VERSION ""

NS_ :

BS_:

BU_: GENERIC_GWMWakeup Generic_BCM TRM GWM _delete APIM SODL RTM FCIM PDM SCMH SCMG HSWM GPSM RSM SODR DDM RBM DSM SCME TSTR
VAL_TABLE_ OffOn_NotUsed_NoData 3 "No_Data_Present" 2 "NotUsed" 1 "On" 0 "Off" ;
VAL_TABLE_ BrkDrvMde_D_Rq 7 "Faulty" 6 "NotUsed3" 5 "NotUsed2" 4 "NotUsed1" 3 "Track" 2 "Snow_Wet" 1 "Sport" 0 "Normal" ;
VAL_TABLE_ Null_Off_On 3 "NotUsed" 2 "On" 1 "Off" 0 "Null" ;
VAL_TABLE_ Faulty_1FFF 8191 "Faulty" ;
VAL_TABLE_ CnvtTopTrgt_D_Rq 7 "NotUsed4" 6 "NotUsed3" 5 "NotUsed2" 4 "NotUsed1" 3 "OpenTarget" 2 "OpenPosition" 1 "ClosePosition" 0 "CloseTarget" ;
VAL_TABLE_ CnvtTopPos_D_Stat 15 "Faulty" 14 "NotUsed7" 13 "NotUsed6" 12 "NotUsed5" 11 "NotUsed4" 10 "NotUsed3" 9 "NotUsed2" 8 "NotUsed1" 7 "ShutdownComplete" 6 "NoNormalised" 5 "Moving" 4 "PositionIntermediate" 3 "PositionOpenTarget" 2 "PositionOpenPosition" 1 "PositionClosePosition" 0 "PositionCloseTarget" ;
VAL_TABLE_ CnvtTopPar_D_Rq 7 "NotUsed" 6 "ForceIncrease3" 5 "ForceIncrease2" 4 "ForceIncrease1" 3 "NoAdapt" 2 "Teach" 1 "NoPwmNoAp" 0 "Normal" ;
VAL_TABLE_ CnvtTopComplt_D_Stat 7 "DenormalizingReady" 6 "NormalizingReady" 5 "RunoutComplete" 4 "StopByPositioning" 3 "StopByFault" 2 "StopByPinch" 1 "StopByStall" 0 "StopByRequest" ;
VAL_TABLE_ Inactive_Active_NotUsed_Faulty 3 "Faulty" 2 "NotUsed" 1 "Active" 0 "Inactive" ;
VAL_TABLE_ CnvtTop_D_Rq 7 "NotUsed" 6 "ResetErrorFlags" 5 "DiscardNormalization" 4 "SetNormalization" 3 "DirectDriveClose" 2 "DirectDriveOpen" 1 "DirectPosition" 0 "Stop" ;
VAL_TABLE_ FohEng_D_Rq 3 "AutoEnable_ParkEnable" 2 "AutoDisable_ParkEnable" 1 "AutoEnable_ParkDisable" 0 "Disable_Stop" ;
VAL_TABLE_ Null_Hi_NotUsed_Low 3 "Low" 2 "Not_Used" 1 "High" 0 "Null" ;
VAL_TABLE_ Current_Color 15 "NotUsed7" 14 "NotUsed6" 13 "NotUsed5" 12 "NotUsed4" 11 "NotUsed3" 10 "NotUsed2" 9 "NotUsed1" 8 "Null" 7 "Color7" 6 "Color6" 5 "Color5" 4 "Color4" 3 "Color3" 2 "Color2" 1 "Color1" 0 "Off" ;
VAL_TABLE_ Blended_Color 15 "NotUsed10" 14 "NotUsed9" 13 "NotUsed8" 12 "NotUsed7" 11 "NotUsed6" 10 "NotUsed5" 9 "NotUsed4" 8 "NotUsed3" 7 "NotUsed2" 6 "NotUsed1" 5 "_5" 4 "_4" 3 "_3" 2 "_2" 1 "_1" 0 "Null" ;
VAL_TABLE_ OffOn_Null_NotUsed 3 "NotUsed" 2 "Null" 1 "On" 0 "Off" ;
VAL_TABLE_ Null_Pers1_4_Vehicle 7 "Unused_2" 6 "Unused_1" 5 "Vehicle" 4 "PERS_4" 3 "PERS_3" 2 "PERS_2" 1 "PERS_1" 0 "Null" ;
VAL_TABLE_ VehKeyActv_D_Stat 15 "NotUsed7" 14 "NotUsed6" 13 "NotUsed5" 12 "NotUsed4" 11 "NotUsed3" 10 "NotUsed2" 9 "NotUsed1" 8 "Key8Active" 7 "Key7Active" 6 "Key6Active" 5 "Key5Active" 4 "Key4Active" 3 "Key3Active" 2 "Key2Active" 1 "Key1Active" 0 "NoKeyActive" ;
VAL_TABLE_ VehLckInd_D_Rq 3 "NotUsed" 2 "On_Day" 1 "On_Night" 0 "Off" ;
VAL_TABLE_ Off_On_Unknown_Invalid 3 "Invalid" 2 "Unknown" 1 "On" 0 "Off" ;
VAL_TABLE_ TowBarMsgTxt_D_Rq 7 "NotUsed3" 6 "NotUsed2" 5 "NotUsed1" 4 "TowBar_Ext_No_Trlr" 3 "Error_Dealer_Fix" 2 "Start_Engine_Swivel" 1 "Check_Tow_Bar" 0 "Null" ;
VAL_TABLE_ SeatFnChng 15 "Faulty" 14 "NotUsed9" 13 "NotUsed8" 12 "NotUsed7" 11 "NotUsed6" 10 "NotUsed5" 9 "NotUsed4" 8 "NotUsed3" 7 "NotUsed2" 6 "High" 5 "Low" 4 "Off" 3 "Decrease" 2 "Increase" 1 "NotUsed1" 0 "Inactive" ;
VAL_TABLE_ NoData_Faulty_3E_3F 63 "Faulty" 62 "NoDataExists" ;
VAL_TABLE_ Faulty_3FF 1023 "Faulty" ;
VAL_TABLE_ DynoMde_B_Cmd 1 "Two_Wheel_Dyno" 0 "Normal_Operation" ;
VAL_TABLE_ HvacPrecondRecirc_D_Rq 3 "Last_User_Setting" 2 "Auto" 1 "Recirc" 0 "Outside" ;
VAL_TABLE_ HvacPrecondAC_D_Rq 3 "Last_User_Setting" 2 "Auto" 1 "On" 0 "Off" ;
VAL_TABLE_ NoData_Faulty_FFFE_FFFF 65535 "Faulty" 65534 "NoDataExists" ;
VAL_TABLE_ PepsKeyActv_D_Stat 15 "NotUsed11" 14 "NotUsed10" 13 "NotUsed9" 12 "NotUsed8" 11 "NotUsed7" 10 "NotUsed6" 9 "NotUsed5" 8 "Key4Active" 7 "NotUsed4" 6 "NotUsed3" 5 "NotUsed2" 4 "Key3Active" 3 "NotUsed1" 2 "Key2Active" 1 "Key1Active" 0 "NoKeyActive" ;
VAL_TABLE_ CellLock_D_Rq 7 "NotUsed3" 6 "NotUsed2" 5 "NotUsed1" 4 "TrunkRelPopGlassLgCargo" 3 "LockAllDoorsandTailgate" 2 "UnlockDriversDoor" 1 "UnlockAllDoorsandTailgate" 0 "NoRequest" ;
VAL_TABLE_ DrTgateChime2_D_Rq 7 "NotUsed3" 6 "NotUsed2" 5 "NotUsed1" 4 "Long_Repeated" 3 "Fast" 2 "Short" 1 "Long" 0 "Off" ;
VAL_TABLE_ ValetMode_D_Stat 3 "Not used_3" 2 "On" 1 "Off" 0 "Null" ;
VAL_TABLE_ StopStrtDrvMde_D_Indic 3 "NotUsed" 2 "StartStop_IndirectDeselect" 1 "StopStart_Deselected" 0 "StopStart_Selected" ;
VAL_TABLE_ StopStrtStdby_D_Indic 6 "NotUsed2" 5 "Telltale_Struck_Out" 4 "Telltale_Flashing_Amber" 3 "Telltale_On_Amber" 2 "Telltale_Flashing_Green" 1 "Telltale_On_Green" 0 "Telltale_Off" 7 "NotUsed3" ;
VAL_TABLE_ CtaInnr_D_Stat 3 "Reporting" 2 "Not_Reporting" 1 "System_Standby" 0 "Initialization" ;
VAL_TABLE_ FohMsgTxt_D_Rq 4 "BatteryNotFullyCharged" 3 "Exceed7DaysFromLastEngRun" 2 "AmbientTemperatureTooHigh" 1 "LowFuel" 0 "NoMessage" ;
VAL_TABLE_ FohStrtDay_T_Rq 7 "Sunday" 6 "Saturday" 5 "Friday" 4 "Thursday" 3 "Wednesday" 2 "Tuesday" 1 "Monday" 0 "NotUsed" ;
VAL_TABLE_ DisableEnableNotUsedUnknown 3 "Unknown" 2 "NotUsed" 1 "Enable" 0 "Disable" ;
VAL_TABLE_ NoRequest_Request 1 "Request" 0 "NoRequest" ;
VAL_TABLE_ Foh_D_Stat 7 "Unused3" 6 "Unused2" 5 "Unused1" 4 "Stopping" 3 "Running" 2 "Starting" 1 "Prestart" 0 "Off" ;
VAL_TABLE_ ActiveStoragePassenger 7 "Unused3" 6 "Unused2" 5 "Unused1" 4 "StoreDipMemoryButton4" 3 "StoreDipMemoryButton3" 2 "StoreDipMemoryButton2" 1 "StoreDipMemoryButton1" 0 "Off" ;
VAL_TABLE_ DipMirror 1 "Dipped" 0 "Off" ;
VAL_TABLE_ WindowCmd 7 "Unused2" 6 "Unused1" 5 "NotDefined" 4 "Audo_Down" 3 "Manual_Down" 2 "Auto_Up" 1 "Manual_Up" 0 "Idle" ;
VAL_TABLE_ MirrorCmd 7 "Unused" 6 "Unfold" 5 "Fold" 4 "Right" 3 "Left" 2 "Down" 1 "Up" 0 "Idle" ;
VAL_TABLE_ WindowPosition 7 "Unused2" 6 "Unused1" 5 "Fully_Open" 4 "Bet60Percent_FullyOpen" 3 "Bet10Percent_60Percent" 2 "BetFully_10PercentOpen" 1 "Fully_Closed" 0 "Undefined" ;
VAL_TABLE_ OffOnNoDataUnused 3 "Unused" 2 "NoDataExists" 1 "On" 0 "Off" ;
VAL_TABLE_ FohFalt_D_Stat 15 "NotUsed4" 14 "NotUsed3" 13 "NotUsed2" 12 "NotUsed1" 11 "FuelTypeDoesNotMatchFOH" 10 "Lifecycle_ModeNotSet" 9 "AuxElectricCoolantPumpInop" 8 "TimeDelayAvoidExcessCycl" 7 "Fuel_Level_OutofRange" 6 "External_Fault" 5 "Internal_Fault" 4 "Voltage_limitation" 3 "Impact_Event" 2 "CoolantTemp_OutofRange" 1 "AmbientTemp_OutofRange" 0 "No_Disable" ;
VAL_TABLE_ FohRqRun_B_Rq 1 "SubmitRequest_toRun" 0 "DoesNotSubmitRequest_toRun" ;
VAL_TABLE_ SteWhlHeat 15 "NotUsed6" 14 "NotUsed5" 13 "NotUsed4" 12 "NotUsed3" 11 "NotUsed2" 10 "NotUsed1" 9 "Reserved_3" 8 "Reserved_2" 7 "Reserved_1" 6 "Level_3_Heating" 5 "Level_3_Heating_LS" 4 "Level_2_Heating" 3 "Level_2_Heating_LS" 2 "Level_1_Heating" 1 "Level_1_Heating_LS" 0 "Off" ;
VAL_TABLE_ OffOnUnusedFault 3 "Fault" 2 "Unused" 1 "On" 0 "Off" ;
VAL_TABLE_ EngineBrakeOff_Active 1 "Engine_Braking_Activated" 0 "Engine_Braking_Off" ;
VAL_TABLE_ Allowed_Denied 1 "Denied" 0 "Allowed" ;
VAL_TABLE_ PrkAid_D_Falt 7 "NotUsed2" 6 "NotUsed1" 5 "Failure_Front_PSM_Sensors" 4 "No_Data_Exists" 3 "Failure_Rear_Sensors" 2 "Speaker_Fault" 1 "ECU_Fault" 0 "No_Fault" ;
VAL_TABLE_ ApaSwtch_D_RqDrv 3 "Faulty" 2 "Stuck" 1 "Pressed" 0 "NotPressed" ;
VAL_TABLE_ _7F_Null 127 "Null" ;
VAL_TABLE_ SeatFnDrv_D_Rq 7 "CushionMassage" 6 "LumbarMassage" 5 "UpperBolster" 4 "LowerBolster" 3 "UpperLumbar" 2 "MiddleLumbar" 1 "LowerLumbar" 0 "Inactive" ;
VAL_TABLE_ Inactive_IncreaseDecrease 2 "Decrease" 1 "Increase" 0 "Inactive" ;
VAL_TABLE_ MemFeedback 8 "Recall_4" 7 "Recall_3" 6 "Recall_2" 5 "Recall_1" 4 "Store_4" 3 "Store_3" 2 "Store_2" 1 "Store_1" 0 "Inactive" ;
VAL_TABLE_ Null_Off_LowHigh 3 "High" 2 "Low" 1 "Off" 0 "Null" ;
VAL_TABLE_ NotUpdate_Update 1 "Updating" 0 "NotUpdating" ;
VAL_TABLE_ SeatFnDrv_D_Stat 7 "CushionMassage" 6 "LumbarMassage" 5 "UpperBolster" 4 "LowerBolster" 3 "UpperLumbar" 2 "MiddleLumbar" 1 "LowerLumbar" 0 "Null" ;
VAL_TABLE_ GearRvrse_D_Actl 7 "Fault" 6 "NotUsed_3" 5 "NotUsed_2" 4 "NotUsed_1" 3 "Active_confirmed" 2 "Active_not_confirmed" 1 "Inactive_confirmed" 0 "Inactive_not_confirmed" ;
VAL_TABLE_ SideDetect_SnStat_Invalid 3 "Invalid" 2 "System_Failure" 1 "Blocked" 0 "Clear" ;
VAL_TABLE_ SideDetect_OpStat 4 "Invalid" 3 "Disabled" 2 "On" 1 "Trailer_Tow_Off" 0 "Off" ;
VAL_TABLE_ SideDetect_Present 4 "Sensor_Blocked" 3 "Sensor_Fault" 2 "Flash_On" 1 "Alert_On" 0 "AlertOff_FlashOff_SensrClr" ;
VAL_TABLE_ Off_On_Flash_BulbProveout 3 "Bulb_Proveout" 2 "Flash" 1 "On" 0 "Off" ;
VAL_TABLE_ SideDetect_BLIS_Off_On 2 "BLIS_On_Second_Warning_ON" 1 "BLIS_On_Second_Warning_OFF" 0 "Off" ;
VAL_TABLE_ SideDetect_report 3 "Reporting" 2 "Not_Reporting" 1 "System_Standby" 0 "Initialization" ;
VAL_TABLE_ DrTGate_D_Rq 3 "NotUsed" 2 "Closing" 1 "Opening" 0 "Not_Moving" ;
VAL_TABLE_ WndwSide_D_Stat 3 "BothWindow_Operating" 2 "RearWindow_Operating" 1 "FrontWindow_Operating" 0 "NoWindows_Operating" ;
VAL_TABLE_ False_True 1 "True" 0 "False" ;
VAL_TABLE_ Null_Up_Down 3 "Unused" 2 "Down" 1 "Up" 0 "Null" ;
VAL_TABLE_ Null_Fwd_Rwd 3 "Unused" 2 "Rearward" 1 "Forward" 0 "Null" ;
VAL_TABLE_ Null_Ack_Nack_NotUsed 3 "Not_Used" 2 "Nack" 1 "Ack" 0 "Null" ;
VAL_TABLE_ HvacBlwrFront_D_Stat 31 "Not_Used" 20 "Full_On" 19 "95_Percent" 18 "90_Percent" 17 "85_Percent" 16 "80_Percent" 15 "75_Percent" 14 "70_Percent" 13 "65_Percent" 12 "60_Percent" 11 "55_Percent" 10 "50_Percent" 9 "45_Percent" 8 "40_Percent" 7 "35_Percent" 6 "30_Percent" 5 "25_Percent" 4 "20_Percent" 3 "15_Percent" 2 "10_Percent" 1 "5_Percent" 0 "Off" ;
VAL_TABLE_ ACU_ARAudioSource_Rsp 15 "iPod" 14 "USB" 13 "BTAudio" 0 "AmfmRadio" 1 "FrontDisc" 2 "SDARS_DAB" 3 "InDashCdChanger" 4 "VoiceRecogniser" 5 "TelematicUnit" 6 "BluetoothPhone" 7 "RearDisc" 8 "APIM" 9 "FrontAuxInput" 10 "Navigation" 11 "RearAux" 12 "NotReq" ;
VAL_TABLE_ ACU_AROperationType_Rsp 0 "Inactive" 1 "Requestaudioresource" 2 "Releaseaudioresource" 3 "Releaseallaudioresouces" 4 "Getresourceupdate" 5 "Getallresourceupdates" ;
VAL_TABLE_ ACU_ARResponse_Rsp 0 "Inactive" 1 "RequestAccepted" 2 "RequestAcceptedWoCtrl" 3 "RequestDenied" 4 "RessourceUpdateStatus" ;
VAL_TABLE_ ACU_ARReqstrPriority_Rp 0 "EmergencyServ" 1 "TelService" 2 "AutoAnswer" 3 "Ta" 4 "PttMutevoice" 5 "NavUserVoiceCmd" 6 "NavSysVoiceCmd" 7 "Radio" 8 "Disc" 9 "Alarm" 10 "Ptynews" 11 "Aux_ExtSource" 12 "MobileNavAndTelMute" 13 "ManualAudioMute" 14 "NotReq" ;
VAL_TABLE_ ACU_RUAudioSource_St 15 "iPod" 14 "USB" 13 "BTAudio" 0 "AmfmRadio" 1 "FrontDisc" 2 "SDARS_DAB" 3 "InDashCdChanger" 4 "VoiceRecogniser" 5 "TelematicUnit" 6 "BluetoothPhone" 7 "RearDisc" 8 "APIM" 9 "FrontAuxInput" 10 "Navigation" 11 "RearAux" 12 "NotReq" ;
VAL_TABLE_ FrontRequest_RearRequest 0 "FrontRequester" 1 "RearRequester" ;
VAL_TABLE_ ACU_RUResReqstStatus_St 0 "NoResourceupdate" 1 "Deallocated" 2 "Allocated" 3 "Stacked" 4 "Granted" 5 "GrantedNoControlOfAudioSrc" ;
VAL_TABLE_ ACU_RUReqstrPriority_St 0 "EmergencyServ" 1 "TelService" 2 "AutoAnswer" 3 "Ta" 4 "PttMutevoice" 5 "NavUserVoiceCmd" 6 "NavSysVoiceCmd" 7 "Radio" 8 "Disc" 9 "Alarm" 10 "Ptynews" 11 "Aux_ExtSource" 12 "MobileNavAndTelMute" 13 "ManualAudioMute" 14 "NotReq" ;
VAL_TABLE_ EFP_Bezel_Diag_St 15 "Reserved" 3 "CalibrationPartNumber" 2 "HardwarePartNumber" 1 "SoftwarePartNumber" 0 "Inactive_NOP" ;
VAL_TABLE_ Invalid_SupportedNotSup 2 "Not_Supported" 1 "Supported" 0 "Invalid" ;
VAL_TABLE_ Invalid_EnabledDisabled 0 "Invalid" 2 "Disabled" 1 "Enabled" ;
VAL_TABLE_ Diagnostic_Operation_Rq 7 "SignalStrength" 6 "SDARSESNNumber" 5 "SpeakerWalkAround" 4 "CalibrationPartNumber" 15 "Reserved" 3 "HardwarePartNumber" 2 "SoftwarePartNumber" 1 "GetAllBackgroundDiagRq" 0 "Inactive" ;
VAL_TABLE_ Bezel_Diag_Module_Rq 15 "Reserved" 3 "EFP" 2 "DSP_AMP" 1 "AHU" 0 "Inactive" ;
VAL_TABLE_ HMI_HMIMode_St 5 "Load_Shed_Active" 0 "Invalid" 1 "OffMode" 2 "On" 3 "Phone" 4 "Climate" ;
VAL_TABLE_ PrmtrAlrmEvnt_D_Stat 15 "NotUsed" 14 "Trailer" 13 "Shock_Sensor" 12 "Post_Crash" 11 "Panic" 10 "Intrusion" 9 "Inclination" 8 "Ign_Tamper" 7 "LG_Door" 6 "Decklid" 5 "Hood" 4 "PR_Door" 3 "PF_Door" 2 "DR_Door" 1 "DF_Door" 0 "Null" ;
VAL_TABLE_ PtcHtr_D_Cmd 3 "TurnOn" 2 "AutoMode" 1 "TurnOff" 0 "NoDecision_Initializing" ;
VAL_TABLE_ NoData_Fault_FFFE_FFFF 65535 "Fault" 65534 "NoDataExists" ;
VAL_TABLE_ TrlrBattChrg_D_Stat 3 "Reverse" 2 "Normal" 1 "Low" 0 "Null" ;
VAL_TABLE_ TrlrLampCtl_D_Stat 3 "NotUsed" 2 "TrlrLampCnnctDrvFailure" 1 "TrlrLampNotCnnctDrvFailure" 0 "Null" ;
VAL_TABLE_ ElPw_D_StatStrtStop 15 "NotUsed6" 14 "NotUsed5" 13 "NotUsed4" 12 "NotUsed3" 11 "NotUsed2" 10 "NotUsed1" 9 "Supported_Level_4" 8 "Supported_Level_3" 7 "Supported_Level_2" 6 "Supported_Level_1" 5 "Limited_Support" 4 "Fault_Limited" 3 "LV_Event_in_Progress" 2 "Not_Supported_Imminent" 1 "Supported_All" 0 "Not_Supported" ;
VAL_TABLE_ ImpactEvntFdbck_D_Stat 3 "NotUsed" 2 "EventComplete" 1 "EventInProgress" 0 "Normal" ;
VAL_TABLE_ NoData_Fault_3E_3F 63 "Fault" 62 "NoDataExists" ;
VAL_TABLE_ Null_Open 1 "Open" 0 "Null" ;
VAL_TABLE_ Inactive_Enable_Disable 0 "Inactive" 2 "Disable" 1 "Enable" ;
VAL_TABLE_ TempDegreesC_DegreesF 0 "Temperature_deg_c" 1 "Temperature_deg_f" ;
VAL_TABLE_ Temp_Detents 15 "Unused5" 14 "Unused4" 13 "Unused3" 12 "Unused2" 11 "Unused1" 10 "Display_Blank" 9 "_4_Heat_Bars" 8 "_3_Heat_Bars" 7 "_2_Heat_Bars" 6 "_1_Heat_Bar" 5 "Neutral_Bar_Only" 4 "_1_Cool_Bar" 3 "_2_Cool_Bars" 2 "_3_Cool_Bars" 1 "_4_Cool_Bars" 0 "No_Bars" ;
VAL_TABLE_ Set_Temp_Dig3 2 "_5" 1 "_0" 0 "Off" ;
VAL_TABLE_ Set_Temp_Dig 15 "Blank6" 14 "Blank5" 13 "Blank4" 12 "Blank3" 11 "Blank2" 10 "Blank1" 9 "_9" 8 "_8" 7 "_7" 6 "_6" 5 "_5" 4 "_4" 3 "_3" 2 "_2" 1 "_1" 0 "_0" ;
VAL_TABLE_ Btn_Status 16 "Rear_Control_Pressed" 15 "RHS_Cld_Seat_Pressed" 14 "LHS_Cld_Seat_Pressed" 13 "RHS_Htd_Seat_Pressed" 12 "LHS_Htd_Seat_Pressed" 11 "Rear_Power_Pressed" 10 "AUTO_Pressed" 9 "Blwr_Dec_Pressed" 8 "Blwr_Inc_Pressed" 7 "RHS_Temp_Dec_Pressed" 6 "RHS_Temp_Inc_Pressed" 5 "LHS_Temp_Dec_Pressed" 4 "LHS_Temp_Inc_Pressed" 3 "Floor_Pressed" 2 "Panel_Floor_Pressed" 1 "Panel_Pressed" 0 "None_Pressed" ;
VAL_TABLE_ Cond_Seat_Status 7 "Unused" 6 "Level_3_Heating" 5 "Level_2_Heating" 4 "Level_1_Heating" 3 "Level_3_Cooling" 2 "Level_2_Cooling" 1 "Level_1_Cooling" 0 "Off" ;
VAL_TABLE_ Htd_Strg_Whl_Status 3 "Level_3_Heating" 2 "Level_2_Heating" 1 "Level_1_Heating" 0 "Off" ;
VAL_TABLE_ Frt_Btn_Status_1st 31 "Defrost_Pressed" 30 "Htg_Strg_Whl_Pressed" 29 "RHS_Cld_Seat_Pressed" 28 "LHS_Cld_Seat_Pressed" 27 "RHS_Htd_Seat_Pressed" 26 "LHS_Htd_Seat_Pressed" 25 "Max_Defrost_Pressed" 24 "My_Temp_Pressed" 23 "Front_Power_Pressed" 22 "Rear_Defrost_Pressed" 21 "Pnl_Flr_Ws_Pressed" 20 "Pnl_Ws_Pressed" 19 "Windscreen_Pressed" 18 "Htd_Frt_Wsh_Pressed" 17 "Auto_Recirc_Pressed" 16 "Outside_Pressed" 15 "Recirc_Pressed" 14 "Max_AC_Pressed" 13 "AUTO_Pressed" 12 "Blwr_Dec_Pressed" 11 "Blwr_Inc_Pressed" 10 "RHS_Temp_Dec_Pressed" 9 "RHS_Temp_Inc_Pressed" 8 "LHS_Temp_Dec_Pressed" 7 "LHS_Temp_Inc_Pressed" 6 "Dual_Pressed" 5 "AC_Pressed" 4 "Floor_Ws_Pressed" 3 "Floor_Pressed" 2 "Panel_Floor_Pressed" 1 "Panel_Pressed" 0 "None_Pressed" ;
VAL_TABLE_ Frt_Blower_Speed 3 "NotUsed" 2 "Max_Blower" 1 "Min_Blower" 0 "No_Request" ;
VAL_TABLE_ Blower_Indicate 15 "Display_Blank" 14 "14_Indicators_On" 13 "13_Indicators_On" 12 "12_Indicators_On" 11 "11_Indicators_On" 10 "10_Indicators_On" 9 "9_Indicators_On" 8 "8_Indicators_On" 7 "7_Indicators_On" 6 "6_Indicators_On" 5 "5_Indicators_On" 4 "4_Indicators_On" 3 "3_Indicators_On" 2 "2_Indicators_On" 1 "1_Indicator_On" 0 "Indicators_Off" ;
VAL_TABLE_ Front_AUTO_Label 3 "Full" 2 "Mode" 1 "Blower" 0 "Off" ;
VAL_TABLE_ Drv_Set_Temp 31 "HI" 30 "29_5" 29 "29_0" 28 "28_5" 27 "28_0" 26 "27_5" 25 "27_0" 24 "26_5" 23 "26_0" 22 "25_5" 21 "25_0" 20 "24_5" 19 "24_0" 18 "23_5" 17 "23_0" 16 "22_5" 15 "22_0" 14 "21_5" 13 "21_0" 12 "20_5" 11 "20_0" 10 "19_5" 9 "19_0" 8 "18_5" 7 "18_0" 6 "17_5" 5 "17_0" 4 "16_5" 3 "16_0" 2 "15_5" 1 "LO" 0 "No_Request" ;
VAL_TABLE_ CC_Fr_Stat_User_Adj 7 "Unused4" 6 "Unused3" 5 "Unused2" 4 "Unused1" 3 "Fr_Blwr_Spd_Selection" 2 "FRHS_SetPt_Selection" 1 "FLHS_SetPt_Selection" 0 "None" ;
VAL_TABLE_ CC_Rr_Stat_User_Adj 15 "Unused9" 14 "Unused8" 13 "Unused7" 12 "Unused6" 11 "Unused5" 10 "Unused4" 9 "Unused3" 8 "Unused2" 7 "Unused1" 6 "Rr_Auto_Selection" 5 "Rr_Control_Selection" 4 "Rr_Power_Selection" 3 "Rr_Blwr_Spd_Selection" 2 "RRHS_SetPt_Selection" 1 "RLHS_SetPt_Selection" 0 "None" ;
VAL_TABLE_ CC_Fr_Btn_User_Adj 31 "Unused15" 30 "Unused14" 29 "Unused13" 28 "Unused12" 27 "Unused11" 26 "Unused10" 25 "Unused9" 24 "Unused8" 23 "Unused7" 22 "Unused6" 21 "Unused5" 20 "Unused4" 19 "Unused3" 18 "Unused2" 17 "Unused1" 16 "Htd_WS_Selection" 15 "FLR_Cnd_St_Selection" 14 "FLH_Cnd_St_Selection" 13 "HSW_Selection" 12 "Dual_Selection" 11 "Rear_Defrost_Selection" 10 "Max_Defrost_Selection" 9 "Defrost_Selection" 8 "Fr_Air_Dist_Selection" 7 "Max_AC_Selection" 6 "Fr_Power_Selection" 5 "Recirc_Selection" 4 "AC_Selection" 3 "Fr_Auto_Selection" 2 "Use_MyTemp_Selection" 1 "Save_MyTemp_Selection" 0 "None" ;
VAL_TABLE_ HeadLghtHiFdbck_D_Stat 3 "NotUsed" 2 "Cancel" 1 "Hold" 0 "Allow_Change" ;
VAL_TABLE_ Backlit_LED_Status 15 "Unused3" 14 "Unused2" 13 "Unused1" 12 "Night_12" 11 "Night_11" 10 "Night_10" 9 "Night_9" 8 "Night_8" 7 "Night_7" 6 "Night_6" 5 "Night_5" 4 "Night_4" 3 "Night_3" 2 "Night_2" 1 "Night_1" 0 "Off" ;
VAL_TABLE_ Veh_Lock_Status 3 "UNLOCK_DRV" 2 "UNLOCK_ALL" 1 "LOCK_ALL" 0 "LOCK_DBL" ;
VAL_TABLE_ CrashEvnt_D_Stat 3 "Invalid" 2 "Fuel_Cutoff_Event" 1 "Deploy_Event" 0 "No_Event" ;
VAL_TABLE_ ReducedGuard_D_Stat 3 "NotUsed" 2 "Alarm_On" 1 "Alarm_Off_Previously_On" 0 "Alarm_Off" ;
VAL_TABLE_ HvacPrecondBlwr_D_Rq 15 "NotUsed6" 14 "NotUsed5" 13 "NotUsed4" 12 "NotUsed3" 11 "NotUsed2" 10 "NotUsed1" 9 "Last_User_Setting" 8 "Auto" 7 "Speed7" 6 "Speed6" 5 "Speed5" 4 "Speed4" 3 "Speed3" 2 "Speed2" 1 "Speed1" 0 "Off" ;
VAL_TABLE_ HvacPrecondMode_D_Rq 15 "NotUsed4" 14 "NotUsed3" 13 "NotUsed2" 12 "NotUsed1" 11 "Last_User_Settings" 10 "Auto" 9 "Max_Defrost" 8 "Windshield_Panel_Floor" 7 "Windshield_Panel" 6 "Windshield" 5 "Windshield_Floor" 4 "Floor" 3 "Panel_Floor" 2 "Panel" 1 "MAX_AC" 0 "Off" ;
VAL_TABLE_ Null_Pressed 1 "Pressed" 0 "Null" ;
VAL_TABLE_ FobComm_D_Stat 3 "NotUsed" 2 "RemEngStartOK" 1 "RemEngStartFail" 0 "Null" ;
VAL_TABLE_ PudLamp_D_Rq 3 "RAMP_DOWN" 2 "RAMP_UP" 1 "ON" 0 "OFF" ;
VAL_TABLE_ WndwGlbl_D_Cmd 7 "NotUsed3" 6 "NotUsed2" 5 "NotUsed1" 4 "GLEARN" 3 "GCLOSE" 2 "GOPEN" 1 "GSTOP" 0 "Null" ;
VAL_TABLE_ LockMsg 7 "MSG7" 6 "MSG6" 5 "MSG5" 4 "MSG4" 3 "MSG3" 2 "MSG2" 1 "MSG1" 0 "NO_WARNING" ;
VAL_TABLE_ ChildLockDisplay 3 "NOT_SUPPORTED" 2 "ERROR" 1 "CHILD_UNLOCK" 0 "CHILD_LOCK" ;
VAL_TABLE_ Null_Lock_Unlock 3 "Not Used" 2 "Unlock" 1 "Lock" 0 "Null" ;
VAL_TABLE_ NotDown_Down 1 "Down" 0 "Not_Down" ;
VAL_TABLE_ NotUp_Up 1 "Up" 0 "Not_Up" ;
VAL_TABLE_ Wiper 15 "NO_DATA_EXISTS" 14 "STALLED" 13 "RESERVED" 12 "AUTO_ADJUST" 11 "COURTESYWIPE" 10 "AUTO_HIGH" 9 "AUTO_LOW" 8 "WASH" 7 "MIST_FLICK" 6 "MAN_HIGH" 5 "MAN_LOW" 4 "MAN_INT_ON" 3 "MAN_INT_OFF" 2 "OFF_MOVING" 1 "AUTO_OFF" 0 "OFF" ;
VAL_TABLE_ Turn_switch 3 "Unused_Treat_As_Off" 2 "Right" 1 "Left" 0 "Off" ;
VAL_TABLE_ PrkLght_D_Stat 3 "Park_Both" 2 "Park_Right" 1 "Park_Left" 0 "Off" ;
VAL_TABLE_ HeadLghtSwtch_D_Stat 3 "Autolamp" 2 "Headlamp" 1 "Parklamp" 0 "Off" ;
VAL_TABLE_ LifeCycMde_D_Actl 3 "Transport" 2 "NotUsed" 1 "Factory" 0 "Normal" ;
VAL_TABLE_ ClimtHeat_D_Rq 7 "NotUsed4" 6 "NotUsed3" 5 "NotUsed2" 4 "NotUsed1" 3 "Defrost_Defog" 2 "FastTempPullDownHeatingReq" 1 "OpportunisticHeatingReq" 0 "NoHeatingRequest" ;
VAL_TABLE_ ClimtCool_D_Rq 7 "NotUsed4" 6 "NotUsed3" 5 "NotUsed2" 4 "NotUsed1" 3 "Defrost_Defog" 2 "FastTempPullDownCoolReq" 1 "OpportunisticCoolingReq" 0 "NoCoolingRequest" ;
VAL_TABLE_ HvacRec_D_RqMxBatt 15 "NotUsed5" 14 "NotUsed4" 13 "NotUsed3" 12 "NotUsed2" 11 "NotUsed1" 10 "No_Override" 9 "90Percent_RecircMax" 8 "80Percent_RecircMax" 7 "70Percent_RecircMax" 6 "60Percent_RecircMax" 5 "50Percent_RecircMax" 4 "40Percent_RecircMax" 3 "30Percent_RecircMax" 2 "20Percent_RecircMax" 1 "10Percent_RecircMax" 0 "0Percent_RecircFullOpen" ;
VAL_TABLE_ PrkBrkStatus 7 "GeneralFault_MaintenceMode" 6 "ECD_by_Brake_ECU_Active" 5 "EPB_Limphome_Active" 4 "Rear_Caliper_Open" 3 "RWU_By_EPB_Active" 2 "Rear_Caliper_Transition" 1 "Rear_Caliper_Closed" 0 "Not_Supported" ;
VAL_TABLE_ Quality_Data 3 "OK" 2 "Not_Within_Specifications" 1 "Eval_In_Progress" 0 "Fault" ;
VAL_TABLE_ PwSrcULoFalt_D_Stat 3 "Fault_No_Output" 2 "Fault_Reduced_Output" 1 "Fault_NonSpecific" 0 "No_Fault" ;
VAL_TABLE_ Eng_D_Stat 3 "NotUsed" 2 "EngAutoStopped" 1 "EngOn" 0 "EngOff" ;
VAL_TABLE_ ElPw_D_Stat 7 "NotUsed_3" 6 "NotUsed_2" 5 "NotUsed_1" 4 "Fault_Limited" 3 "LV_Event_In_Progress" 2 "Not_Supported_Imminent" 1 "Supported" 0 "Not_Supported" ;
VAL_TABLE_ PwPckTq_D_Stat 3 "PwPckOn_TqAvailable" 2 "StartInPrgrss_TqNotAvail" 1 "PwPckOn_TqNotAvailable" 0 "PwPckOff_TqNotAvailable" ;
VAL_TABLE_ Fault_FF 255 "Fault" ;
VAL_TABLE_ ElCmprOverTe_D_Stat 3 "OverTempStop" 2 "OverTempWarning" 1 "Normal" 0 "Undefined" ;
VAL_TABLE_ Southern_Northern 3 "Fault" 2 "Northern" 1 "Southern" 0 "Invalid" ;
VAL_TABLE_ Fault_3FF 1023 "Fault" ;
VAL_TABLE_ Fault_F 15 "Fault" ;
VAL_TABLE_ Fault_1F 31 "Fault" ;
VAL_TABLE_ LockInhibit 1 "Inhibit" 0 "No_Inhibit" ;
VAL_TABLE_ FCIM_Target_ID 15 "ALL" 9 "GIM" 8 "DSP" 7 "SAT3" 6 "SAT2" 5 "SAT1" 4 "RSC" 3 "FES" 2 "ACM" 1 "CPM" 0 "NOP" ;
VAL_TABLE_ FCIM_Button_Type 54 "_6" 53 "_5" 52 "_4" 51 "_3" 50 "_2" 49 "_1" 48 "_0" 47 "Phone_Mute" 46 "Pause" 45 "Play_Pause" 44 "Volume_Down" 43 "Volume_Up" 42 "Tune_Down" 41 "Tune_Up" 40 "Treble_Down" 39 "Treble_Up" 38 "Tape" 37 "Seek_Down" 36 "Seek_Up" 35 "Shuffle" 34 "Repeat" 33 "Scan" 32 "Navigation" 31 "Fast_Forward" 30 "Reverse" 29 "Preset_6" 28 "Preset_5" 27 "Preset_4" 26 "Preset_3" 25 "Preset_2" 24 "Preset_1" 23 "Memory_Recall" 22 "Clear" 21 "End" 20 "Send" 19 "Fade_Down" 18 "Fade_Up" 17 "Dolby" 16 "Compression" 15 "Clock" 14 "Bass_Down" 13 "Bass_Up" 12 "Balance_Down" 11 "Balance_Up" 10 "Folder_Previous" 9 "Folder_Next" 8 "Category_Folder" 7 "File" 6 "Autoset" 5 "Menu_Previous" 4 "Menu_Next" 3 "Menu" 2 "OK_Select" 1 "Power_On_Off" 0 "NOP_No_Button" 255 "Last" 153 "RPT_Repeat" 152 "NAV" 151 "Dest_Destination" 150 "Map" 149 "SWC_End" 148 "SWC_Send" 147 "Special_2" 146 "Special_1" 145 "Phone_Data" 144 "Rear_Zone_Control" 141 "DISP_Display" 140 "INFO" 139 "Climate" 138 "Radio" 137 "Playmode" 136 "Bezel_Diagnostics" 135 "CursorDown" 134 "CursorUp" 133 "Mute" 132 "Phone" 131 "Eject" 130 "Load" 129 "CD" 128 "AM_FM" 124 "Pound_Clock" 123 "Reserved" 122 "Compass_Cal" 121 "SAT" 120 "Aux" 119 "Sound" 118 "Star_Direct_Direct" 117 "List_Item_5" 116 "List_Item_4" 115 "List_Item_3" 114 "List_Item_2" 113 "List_Item_1" 112 "Reserved_Feature_C" 111 "Reserved_Feature_B" 110 "Reserved_Feature_A" 109 "Active_Path" 108 "Distance_Markers" 107 "Return" 106 "Off" 105 "On" 104 "SWC_Seek_Down" 103 "SWC_Seek_Up" 102 "Media" 101 "Stop_Eject" 100 "B_Button" 99 "A_Button" 98 "TestTone" 97 "Lock_List_Item_5" 96 "Lock_List_Item_4" 95 "Lock_List_Item_3" 94 "Lock_List_Item_2" 93 "Lock_List_Item_1" 92 "Skip_List_Item_5" 91 "Skip_List_Item_4" 90 "Skip_List_Item_3" 89 "Skip_List_Item_2" 88 "Skip_List_Item_1" 87 "Enter" 86 "Back" 85 "Keypad" 84 "Channel_List_5" 83 "Channel_List_4" 82 "Channel_List_3" 81 "Channel_List_2" 80 "Channel_List_1" 79 "Category_List_Item_5" 78 "Category_List_Item_4" 77 "Category_List_Item_3" 76 "Category_List_Item_2" 75 "Category_List_Item_1" 74 "Channel_Guide" 73 "Scan_Presets" 72 "Category_Previous" 71 "Category_Next" 70 "Album" 69 "Song_Title" 68 "Artist" 67 "Text" 66 "BER_Display_Button" 65 "PSN_Display_Button" 64 "ESN_Display_Button" 63 "Category" 62 "Display_Previous" 61 "Display_Next" 60 "Voice_PTT" 59 "POUND" 58 "ASTERISK" 57 "_9" 56 "_8" 55 "_7" ;
VAL_TABLE_ FCIM_Button_State 2 "Button_Pressed" 1 "Button_Released" 0 "NOP" ;
VAL_TABLE_ Temp_Units 2 "Fahrenheit" 1 "Celsius" 0 "Off" ;
VAL_TABLE_ Shed_Feature_Group_ID 14 "HtdMirr" 13 "HvacRearBlwr_Third" 12 "HvacRearBlwr_Second" 11 "HvacRearBlwr_First" 31 "All LSHED1 Features" 10 "Htd_Windscrn" 9 "SpltHtdBcklight_HtdMirr" 8 "HtdBcklight_HtdMirr" 7 "HtdCoolSeat_FrtDriver" 6 "HtdCoolSeat_FrtPass" 5 "HtdCoolSeat_RearPass" 4 "HtdCoolSeat_RearDriver" 3 "SmartTrlrTowBattCharge" 2 "Htd_StrWhl" 1 "Htd_Washer_Fluid" 0 "No_LSHED1_Features" 15 "Engine_Coolant_Fan" ;
VAL_TABLE_ CoolantFanStepAct 31 "Unused7" 30 "Unused6" 29 "Unused5" 28 "Unused4" 27 "Unused3" 26 "Unused2" 25 "Unused1" 23 "Step23" 22 "Step22" 21 "Step21" 20 "Step20" 19 "Step19" 18 "Step18" 17 "Step17" 16 "Step16" 15 "Step15" 14 "Step14" 13 "Step13" 12 "Step12" 11 "Step11" 10 "Step10" 9 "Step9" 8 "Step8" 7 "Step7" 6 "Step6" 5 "Step5" 4 "Step4" 3 "Step3" 2 "Step2" 1 "Step1" 24 "Max_Fan_Speed_Req" 0 "Fan_Cmd_Off" ;
VAL_TABLE_ Null_Cancel 1 "Cancel" 0 "Null" ;
VAL_TABLE_ Null_Drive_EasyEntry 2 "Easy_Entry" 1 "Drive" 0 "Null" ;
VAL_TABLE_ Veh_Lock_Requestor 31 "Unused8" 30 "Unused7" 29 "Unused6" 28 "Unused5" 27 "Unused4" 26 "Unused3" 25 "Unused2" 24 "Unused1" 23 "Diagnostics" 22 "Console_Lock" 21 "Child_Lock" 20 "Double_Lock" 19 "Passive_Pasenger" 18 "Passive_Driver" 17 "Slam_Lock_Protect" 16 "SYNC" 15 "Passport" 14 "Passive_Smart_Unlock" 13 "Autorelock" 12 "RemoteStart" 0 "Null" 1 "Autolock" 11 "Smart_Unlock" 10 "Sliding_Door" 9 "Passive" 8 "Remote" 7 "Programming" 6 "Powerslide" 5 "Keypad" 4 "Key_Cylinder" 3 "Interior" 2 "Auto_Unlock" ;
VAL_TABLE_ Perimeter_Alarm_Mode 3 "Activated" 2 "Armed" 1 "Prearmed" 0 "Disarmed" ;
VAL_TABLE_ Invalid_FFFF 65535 "Invalid" ;
VAL_TABLE_ Shed_Level_Req 7 "Unused_2" 6 "Loads_On" 5 "SHED_ENG_OFF" 4 "SOON_ENG_OFF" 3 "SHED2_CONTIN" 2 "SHED2_TRANS" 1 "SHED1" 0 "NO_SHED" ;
VAL_TABLE_ Eastern_Western 0 "Invalid" 1 "Eastern" 2 "Western" 3 "Fault" ;
VAL_TABLE_ EATC_Temp_Digit3 2 "_5" 1 "_0" 0 "OFF" ;
VAL_TABLE_ EATC_Units 2 "Fahrenheit" 1 "Celsius" 0 "Off" ;
VAL_TABLE_ RKE_Filter_Ctrl 3 "Streaming" 2 "Filter" 1 "Not_Used" 0 "Null" ;
VAL_TABLE_ RstrnImpactEvntStatus 7 "Invalid" 6 "Not_Used_4" 5 "Threshold_2_Exceeded" 4 "Not_Used_3" 3 "Threshold_1_Exceeded" 2 "Not_Used_2" 1 "Not_Used_1" 0 "Normal" ;
VAL_TABLE_ Closed_Ajar 1 "Ajar" 0 "Closed" ;
VAL_TABLE_ Quality_Factor 3 "OK" 2 "Not_Within_Specifications" 1 "No_Data_Exists" 0 "Faulty" ;
VAL_TABLE_ Null_Day_Night 3 "NotUsed" 2 "Night" 1 "Day" 0 "Null" ;
VAL_TABLE_ WhlDir 3 "Failed" 2 "Unknown" 1 "Backward" 0 "Forward" ;
VAL_TABLE_ Unknown_Fault_1FE_1FF 511 "Fault" 510 "Unknown" ;
VAL_TABLE_ Unknown_Fault_FFFE_FFFF 65535 "Fault" 65534 "Unknown" ;
VAL_TABLE_ Invalid_FFFFFF 16777215 "Invalid" ;
VAL_TABLE_ GearLvrPos_D_Actl 15 "Fault" 14 "Unknown_Position" 13 "Undefined_Treat_as__Fault" 12 "Undefined_Treat_as_Fault" 11 "sixth" 10 "fifth" 9 "fourth" 8 "third" 7 "second" 6 "first" 5 "Low" 4 "Sport_DriveSport" 3 "Drive" 2 "Neutral" 1 "Reverse" 0 "Park" ;
VAL_TABLE_ AslIconDsply_D_Rq 3 "Not_Used" 2 "On_Active" 1 "On_Passive" 0 "Off" ;
VAL_TABLE_ Unknown_Fault_3E_3F 63 "Fault" 62 "Unknown" ;
VAL_TABLE_ NotPressed_Pressed 1 "Pressed" 0 "Not_Pressed" ;
VAL_TABLE_ NotQuiet_Quiet 1 "Quiet" 0 "Not_Quiet" ;
VAL_TABLE_ Remote_Device_Feedback 7 "Unused3" 6 "Unused2" 5 "Unused1" 4 "Shutdown" 3 "Running" 2 "Starting" 1 "Acknowledge" 0 "Null" ;
VAL_TABLE_ Remote_Start_Req 3 "Not_Used" 2 "Remote_Cancel" 1 "Remote_Start" 0 "No_Request" ;
VAL_TABLE_ Modulation_Ctrl 3 "Unused" 2 "FSK" 1 "ASK_FSK" 0 "ASK" ;
VAL_TABLE_ Unlock_Lock 1 "Locked" 0 "Unlock" ;
VAL_TABLE_ Unknown_Fault_FFE_FFF 4095 "Fault" 4094 "Unknown" ;
VAL_TABLE_ InhibitNoinhibit 1 "Inhibit" 0 "No_Inibit" ;
VAL_TABLE_ DisableEnable 1 "Enable" 0 "Disable" ;
VAL_TABLE_ Side_Detect_Sn_State 3 "Second_Warning_Audio" 2 "System_Failure" 1 "Blocked" 0 "Clear" ;
VAL_TABLE_ Litval_values 255 "Invalid" 254 "Unknown" 5 "Day" 4 "Twilight_4" 3 "Twilight_3" 2 "Twilight_2" 1 "Twilight_1" 0 "Night" ;
VAL_TABLE_ Dimming_Lvl 255 "Invalid" 254 "Unknown" 18 "Day_6" 17 "Day_5" 16 "Day_4" 15 "Day_3" 14 "Day_2" 13 "Day_1" 12 "Night_12" 11 "Night_11" 10 "Night_10" 9 "Night_9" 8 "Night_8" 7 "Night_7" 6 "Night_6" 5 "Night_5" 4 "Night_4" 3 "Night_3" 2 "Night_2" 1 "Night_1" 0 "Off" ;
VAL_TABLE_ Remote_Start_Status 3 "Invalid" 2 "Unknown" 1 "Remote" 0 "Null" ;
VAL_TABLE_ Enabled_Active_Disabled 3 "Unused" 2 "Disabled" 1 "Active" 0 "Enabled_Inactive" ;
VAL_TABLE_ Lock_Subld 15 "Unused7" 14 "Unused6" 13 "Unused5" 12 "Unused4" 11 "Unused3" 10 "Unused2" 9 "Unused1" 8 "Customer_8" 7 "Customer_7" 6 "Customer_6" 5 "Customer_5" 4 "Customer_4" 3 "Customer_3" 2 "Customer_2" 1 "Customer_1" 0 "Null" ;
VAL_TABLE_ OFF_ON_Unknown_Invalid 1 "On" 0 "Off" 3 "Invalid" 2 "Unknown" ;
VAL_TABLE_ Brake_Fluid 3 "Invalid" 2 "Unknown" 1 "Low" 0 "OK" ;
VAL_TABLE_ Unknown_Invalid_FE_FF 255 "Invalid" 254 "Unknown" ;
VAL_TABLE_ Invalid_FF 255 "Invalid" ;
VAL_TABLE_ NotLow_Low 1 "Low" 0 "Not_Low" ;
VAL_TABLE_ Key_In_Ignition_Status 1 "In" 0 "Out" ;
VAL_TABLE_ Ignition_Status 0 "Unknown" 1 "Off" 15 "Invalid" 8 "Start" 4 "Run" 2 "Accessory" ;
VAL_TABLE_ Disabled_Enabled_NoSupport 2 "Unused" 3 "Not_Supported" 1 "Enabled" 0 "Disabled" ;
VAL_TABLE_ Unknown_Fault_FE_FF 255 "Fault" 254 "Unknown" ;
VAL_TABLE_ Null_Unlock 1 "Unlock" 0 "Null" ;
VAL_TABLE_ Null_Active 1 "Active" 0 "Null" ;
VAL_TABLE_ MemoryCmd 7 "Recall_3" 4 "Store_4" 3 "Store_3" 6 "Recall_2" 5 "Recall_1" 2 "Store_2" 1 "Store_1" 0 "Null" 8 "Recall_4" ;
VAL_TABLE_ PassRstrnInd_Stat 7 "Invalid" 6 "Unused_2" 5 "Unused_1" 4 "Both_Indicators_Faulted" 3 "AirbagOff_Indicator_fault" 2 "AirbagOn_Indicator_fault" 1 "Normal" 0 "Not_Supported" ;
VAL_TABLE_ PassRstrnInd_Req 3 "ABOnNotIllum_OffNotIllum" 2 "AirbagOnNot_Illum_OffIllum" 1 "AirbagOn_Illum_OffNotIllum" 0 "AirbagOn_Illum_Off_Illum" ;
VAL_TABLE_ GPS_dimension 2 "_3D" 1 "_2D" 0 "No_Fix" ;
VAL_TABLE_ GPS_Compass_dirctn 7 "NorthWest" 6 "West" 5 "SouthWest" 4 "South" 3 "SouthEast" 2 "East" 1 "NorthEast" 0 "North" ;
VAL_TABLE_ GPS_Actual_Infer 1 "Inferred_Position" 0 "Actual_Postition" ;
VAL_TABLE_ Off_On 1 "On" 0 "Off" ;
VAL_TABLE_ InactiveActive 1 "Active" 0 "Inactive" ;
VAL_TABLE_ Unknown_Invalid_1E_1F 31 "Invalid" 30 "Unknown" ;
VAL_TABLE_ Unknown_Invalid_3FFE_3FFF 16383 "Invalid" 16382 "Unknown" ;
VAL_TABLE_ NoYes 1 "Yes" 0 "No" ;
VAL_TABLE_ Unknown_Fault_3FE_3FF 1023 "Fault" 1022 "Unknown" ;
VAL_TABLE_ LockSwStat 3 "Invalid" 2 "Unlock" 1 "Lock" 0 "Null" ;
VAL_TABLE_ Null_Override 1 "Override" 0 "Null" ;
VAL_TABLE_ Off_On_Flash 3 "Not_Used" 2 "Flash" 1 "On" 0 "Off" ;
VAL_TABLE_ Update_Bit 1 "Fresh_data" 0 "Unchanged_data" ;
VAL_TABLE_ Tire_Pressure_Stat 4 "Alert" 15 "Not_Supported" 3 "Fault" 2 "Low" 1 "Normal" 0 "Unknown" ;
VAL_TABLE_ Tire_Pressure_System2 13 "Training_Complete" 12 "Train_InsideLeftRear_tire" 11 "Train_OutsideLeftRear_tire" 10 "Train_LeftRear_tire" 9 "Train_InsideRtRear_tire" 8 "Train_OutsideRtRear_tire" 7 "Train_RightRear_tire" 14 "Tires_not_trained" 6 "Train_RightFront_tire" 5 "Train_LeftFront_tire" 4 "Systm_Activ_Composite_Stat" 3 "Low_Composite_Stat" 2 "Sensr_Fault_Composite_Stat" 1 "Systm_Fault_Composite_Stat" 0 "Unknown_Composite_Stat" ;
VAL_TABLE_ Running_Board 3 "Unused" 2 "Manually_Deployed" 1 "All_Enabled" 0 "All_Disabled" ;
VAL_TABLE_ Clmt_Ctrl_Seat_Setting 128 "H3_High_Heat__MAX" 64 "H2_Medium_Heat" 32 "H1_Low_Heat" 16 "C3_High_Cool__MAX" 8 "C2_Medium_Cool" 4 "C1_Low_Cool" 2 "Off" ;
VAL_TABLE_ Turn_Seq 3 "Seq" 2 "On" 1 "Off" 0 "Null" ;
VAL_TABLE_ NotPark 1 "Park" 0 "Not_Park" ;
VAL_TABLE_ PersOptIn 1 "OPTED_IN" 0 "NOT_OPTED_IN" ;
VAL_TABLE_ PersonalSetUp 3 "Non_Moveable_Person" 2 "Moveable_Person" 1 "Vehicle" 0 "Factory" ;
VAL_TABLE_ Full_Limited 1 "Limited" 0 "Full" ;
VAL_TABLE_ NoConflict_Conflict 1 "Conflict" 0 "No_Conflict" ;
VAL_TABLE_ Assoc_Confirm 0 "None" 7 "Associate" 6 "Keycode_Rejected" 5 "Keycode_Accepted" 4 "In_Progress" 3 "Erase" 2 "Duplicate" 1 "Disassociate" ;
VAL_TABLE_ Complete_Inprogress 3 "Unused" 2 "Null" 1 "InProgress" 0 "Complete" ;
VAL_TABLE_ Null_Pers1_4 7 "Unused_3" 6 "Unused_2" 5 "Unused_1" 4 "PERS_4" 3 "PERS_3" 2 "PERS_2" 1 "PERS_1" 0 "Null" ;
VAL_TABLE_ Pers1_4 7 "Unused_3" 6 "Unused_2" 5 "Unused_1" 4 "Vehicle" 3 "PERS_4" 2 "PERS_3" 1 "PERS_2" 0 "PERS_1" ;
VAL_TABLE_ Null_Query 7 "Unused_2" 6 "Unused_1" 5 "Copy" 4 "Restore" 3 "Upload" 2 "Set" 1 "Query" 0 "Null" ;
VAL_TABLE_ Ign_Key_Device_Type 15 "Invalid" 14 "Unknown" 3 "Key_Not_Prgrm_Read_Failure" 2 "Key_In_Ign_My_Key" 1 "Key_In_Ign_Standard_Key" 0 "Key_Read_In_Progress" ;
VAL_TABLE_ Off_No_Eff_Unknown_Invalid 3 "Invalid" 2 "Unknown" 1 "No_Effect" 0 "Off" ;
VAL_TABLE_ Null_Out 1 "Out" 0 "Null" ;

BO_ 945 Body_Info_7_MS1: 8 GWM
 SG_ KeyOffMde_D_Actl : 7|4@0+ (1,0) [0|15] "SED" Vector__XXX

BO_ 1079 GatewayData2_MS1: 8 GWM
 SG_ BattULo2_Te_Actl : 7|7@0+ (1,-40) [-40|86] "degC"  FCIM
 SG_ BattULo2_Te_Actl_UB : 0|1@0+ (1,0) [0|1] "SED"  FCIM

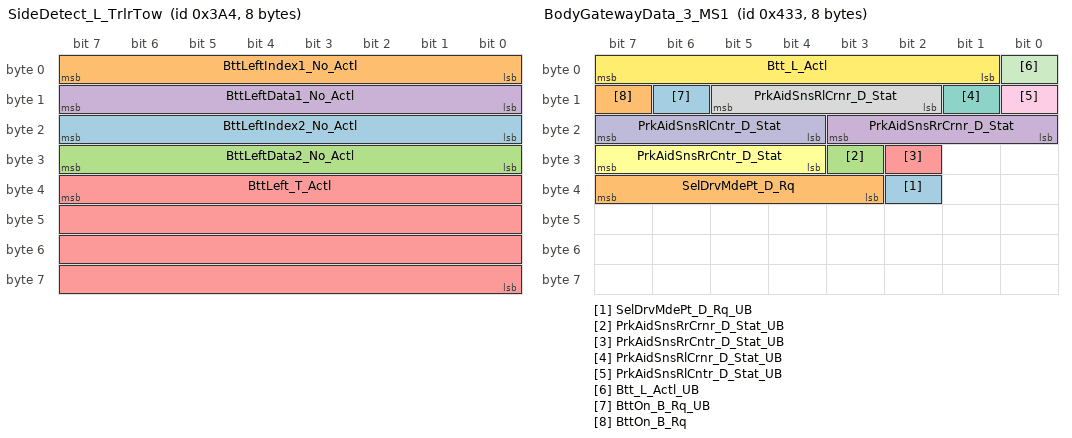
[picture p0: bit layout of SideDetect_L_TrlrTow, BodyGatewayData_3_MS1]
BO_ 932 SideDetect_L_TrlrTow: 8 SODL
 SG_ BttLeftIndex2_No_Actl : 23|8@0+ (1,0) [0|255] "unitless"  SODR
 SG_ BttLeftIndex1_No_Actl : 7|8@0+ (1,0) [0|255] "unitless"  SODR
 SG_ BttLeftData2_No_Actl : 31|8@0+ (1,0) [0|255] "unitless"  SODR
 SG_ BttLeftData1_No_Actl : 15|8@0+ (1,0) [0|255] "unitless"  SODR
 SG_ BttLeft_T_Actl : 39|32@0+ (1,0) [0|4294967295] "ms"  SODR

BO_ 1075 BodyGatewayData_3_MS1: 8 GWM
 SG_ SelDrvMdePt_D_Rq_UB : 34|1@0+ (1,0) [0|1] "SED"  FCIM
 SG_ SelDrvMdePt_D_Rq : 39|5@0+ (1,0) [0|31] "SED"  FCIM
 SG_ PrkAidSnsRrCrnr_D_Stat_UB : 27|1@0+ (1,0) [0|1] "SED"  SODL,SODR
 SG_ PrkAidSnsRrCrnr_D_Stat : 19|4@0+ (1,0) [0|15] "SED"  SODL,SODR
 SG_ PrkAidSnsRrCntr_D_Stat_UB : 26|1@0+ (1,0) [0|1] "SED"  SODL,SODR
 SG_ PrkAidSnsRrCntr_D_Stat : 31|4@0+ (1,0) [0|15] "SED"  SODL,SODR
 SG_ PrkAidSnsRlCrnr_D_Stat_UB : 9|1@0+ (1,0) [0|1] "SED"  SODL,SODR
 SG_ PrkAidSnsRlCrnr_D_Stat : 13|4@0+ (1,0) [0|15] "SED"  SODL,SODR
 SG_ PrkAidSnsRlCntr_D_Stat_UB : 8|1@0+ (1,0) [0|1] "SED"  SODL,SODR
 SG_ PrkAidSnsRlCntr_D_Stat : 23|4@0+ (1,0) [0|15] "SED"  SODL,SODR
 SG_ Btt_L_Actl_UB : 0|1@0+ (1,0) [0|1] "SED"  SODL,SODR
 SG_ Btt_L_Actl : 7|7@0+ (0.1,0) [0|12.5] "meter"  SODL,SODR
 SG_ BttOn_B_Rq_UB : 14|1@0+ (1,0) [0|1] "SED"  SODL,SODR
 SG_ BttOn_B_Rq : 15|1@0+ (1,0) [0|1] "SED"  SODL,SODR

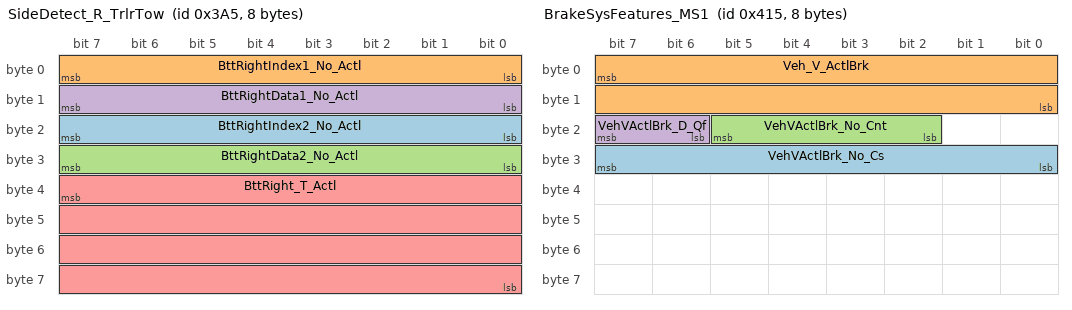
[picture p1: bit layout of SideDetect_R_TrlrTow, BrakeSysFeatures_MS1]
BO_ 933 SideDetect_R_TrlrTow: 8 SODR
 SG_ BttRightIndex2_No_Actl : 23|8@0+ (1,0) [0|255] "unitless"  SODL
 SG_ BttRightIndex1_No_Actl : 7|8@0+ (1,0) [0|255] "unitless"  SODL
 SG_ BttRightData2_No_Actl : 31|8@0+ (1,0) [0|255] "unitless"  SODL
 SG_ BttRightData1_No_Actl : 15|8@0+ (1,0) [0|255] "unitless"  SODL
 SG_ BttRight_T_Actl : 39|32@0+ (1,0) [0|4294967295] "ms"  SODL

BO_ 1098 TrailerInfo_2: 8 TRM
 SG_ TrlrAidSwtch_D_RqDrv : 35|2@0+ (1,0) [0|3] "SED"  GWM
 SG_ TrlrAidCtl_U_RqDrv : 31|12@0+ (0.00125,0) [0|5.11625] "volt"  GWM

BO_ 1045 BrakeSysFeatures_MS1: 8 GWM
 SG_ VehVActlBrk_No_Cs : 31|8@0+ (1,0) [0|255] "Unitless"  TRM
 SG_ Veh_V_ActlBrk : 7|16@0+ (0.01,0) [0|655.35] "kph"  TRM
 SG_ VehVActlBrk_No_Cnt : 21|4@0+ (1,0) [0|15] "Unitless"  TRM
 SG_ VehVActlBrk_D_Qf : 23|2@0+ (1,0) [0|3] "SED"  TRM

BO_ 1189 Running_Board_Data: 8 RBM
 SG_ Running_Board_Stat : 7|2@0+ (1,0) [0|3] "SED"  GWM

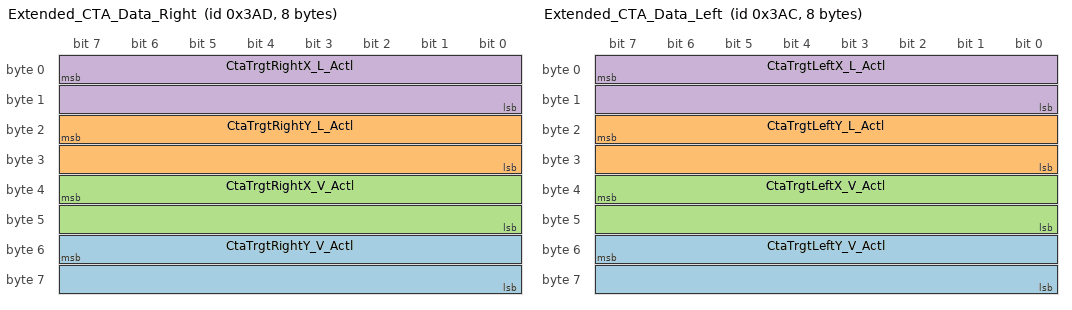
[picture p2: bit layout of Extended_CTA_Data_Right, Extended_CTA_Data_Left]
BO_ 941 Extended_CTA_Data_Right: 8 SODR
 SG_ CtaTrgtRightY_V_Actl : 55|16@0+ (0.001526,-50) [-50|50.00641] "meters/sec"  SODL
 SG_ CtaTrgtRightY_L_Actl : 23|16@0+ (0.0030519,-100) [-100|100.0062665] "meter"  SODL
 SG_ CtaTrgtRightX_V_Actl : 39|16@0+ (0.001526,-50) [-50|50.00641] "meters/sec"  SODL
 SG_ CtaTrgtRightX_L_Actl : 7|16@0+ (0.0021363,-120) [-120|20.0024205] "meter"  SODL

BO_ 940 Extended_CTA_Data_Left: 8 SODL
 SG_ CtaTrgtLeftY_V_Actl : 55|16@0+ (0.001526,-50) [-50|50.00641] "meters/sec"  SODR
 SG_ CtaTrgtLeftY_L_Actl : 23|16@0+ (0.0030519,-100) [-100|100.0062665] "meter"  SODR
 SG_ CtaTrgtLeftX_V_Actl : 39|16@0+ (0.001526,-50) [-50|50.00641] "meters/sec"  SODR
 SG_ CtaTrgtLeftX_L_Actl : 7|16@0+ (0.0021363,-120) [-120|20.0024205] "meter"  SODR

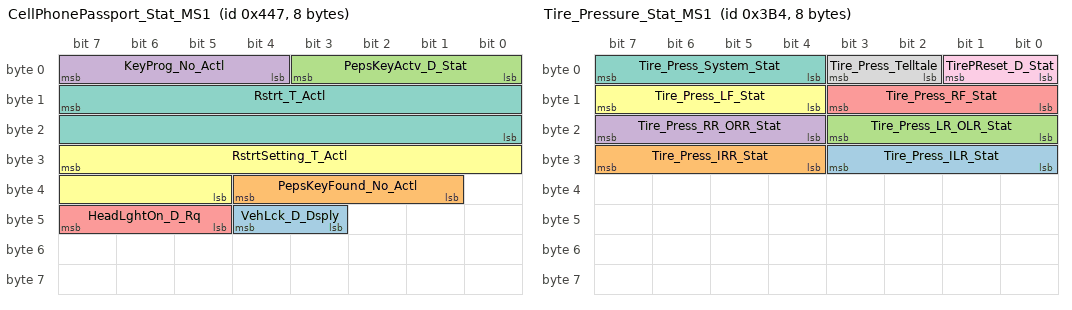
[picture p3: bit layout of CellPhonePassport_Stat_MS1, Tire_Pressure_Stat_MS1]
BO_ 1095 CellPhonePassport_Stat_MS1: 8 GWM
 SG_ VehLck_D_Dsply : 44|2@0+ (1,0) [0|3] "SED" Vector__XXX
 SG_ PepsKeyFound_No_Actl : 36|4@0+ (1,0) [0|15] "unitless" Vector__XXX
 SG_ PepsKeyActv_D_Stat : 3|4@0+ (1,0) [0|15] "SED" Vector__XXX
 SG_ KeyProg_No_Actl : 7|4@0+ (1,0) [0|15] "unitless" Vector__XXX
 SG_ HeadLghtOn_D_Rq : 47|3@0+ (1,0) [0|7] "SED" Vector__XXX
 SG_ RstrtSetting_T_Actl : 31|11@0+ (1,0) [0|2047] "second"  RSM
 SG_ Rstrt_T_Actl : 15|16@0+ (1,0) [0|65535] "seconds"  RSM

BO_ 948 Tire_Pressure_Stat_MS1: 8 GWM
 SG_ Tire_Press_ILR_Stat : 27|4@0+ (1,0) [0|15] "SED"  RTM
 SG_ Tire_Press_IRR_Stat : 31|4@0+ (1,0) [0|15] "SED"  RTM
 SG_ Tire_Press_LR_OLR_Stat : 19|4@0+ (1,0) [0|15] "SED"  RTM
 SG_ Tire_Press_RR_ORR_Stat : 23|4@0+ (1,0) [0|15] "SED"  RTM
 SG_ Tire_Press_RF_Stat : 11|4@0+ (1,0) [0|15] "SED"  RTM
 SG_ Tire_Press_LF_Stat : 15|4@0+ (1,0) [0|15] "SED"  RTM
 SG_ Tire_Press_System_Stat : 7|4@0+ (1,0) [0|15] "SED"  RTM
 SG_ Tire_Press_Telltale : 3|2@0+ (1,0) [0|3] "SED"  RTM
 SG_ TirePReset_D_Stat : 1|2@0+ (1,0) [0|3] "Discrete"  RTM

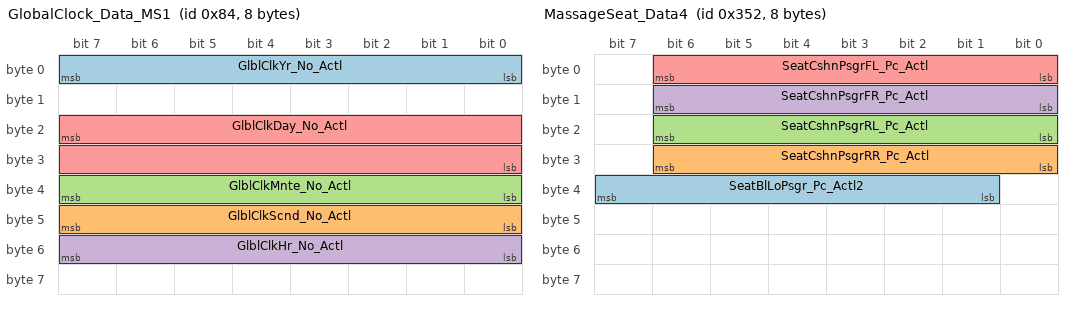
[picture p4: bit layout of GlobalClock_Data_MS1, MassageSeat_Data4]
BO_ 132 GlobalClock_Data_MS1: 8 GWM
 SG_ GlblClkYr_No_Actl : 7|8@0+ (1,2000) [2000|2255] "year"  TRM
 SG_ GlblClkScnd_No_Actl : 47|8@0+ (1,0) [0|255] "second"  TRM
 SG_ GlblClkMnte_No_Actl : 39|8@0+ (1,0) [0|255] "minute"  TRM
 SG_ GlblClkHr_No_Actl : 55|8@0+ (1,0) [0|255] "hour"  TRM
 SG_ GlblClkDay_No_Actl : 23|16@0+ (1,0) [0|65535] "julian day"  TRM

BO_ 1378 APIM_Network_Mgmt_MS1: 8 APIM
 SG_ APIM_Network_Mgmt : 7|64@0+ (1,0) [0|1.844674407371E+019] "unitless"  GWM,DSM,FCIM,GPSM,PDM,RBM,RTM,SCME,TRM

BO_ 839 FuelOpHeater_Stat: 8 GENERIC_GWMWakeup
 SG_ FohKeyOff_B_Rq : 6|1@0+ (1,0) [0|1] "SED"  GWM

BO_ 850 MassageSeat_Data4: 8 SCMH
 SG_ SeatBlLoPsgr_Pc_Actl2 : 39|7@0+ (1,0) [0|126] "Percent"  GWM
 SG_ SeatCshnPsgrRR_Pc_Actl : 30|7@0+ (1,0) [0|126] "Percent"  GWM
 SG_ SeatCshnPsgrRL_Pc_Actl : 22|7@0+ (1,0) [0|126] "Percent"  GWM
 SG_ SeatCshnPsgrFR_Pc_Actl : 14|7@0+ (1,0) [0|126] "Percent"  GWM
 SG_ SeatCshnPsgrFL_Pc_Actl : 6|7@0+ (1,0) [0|126] "Percent"  GWM

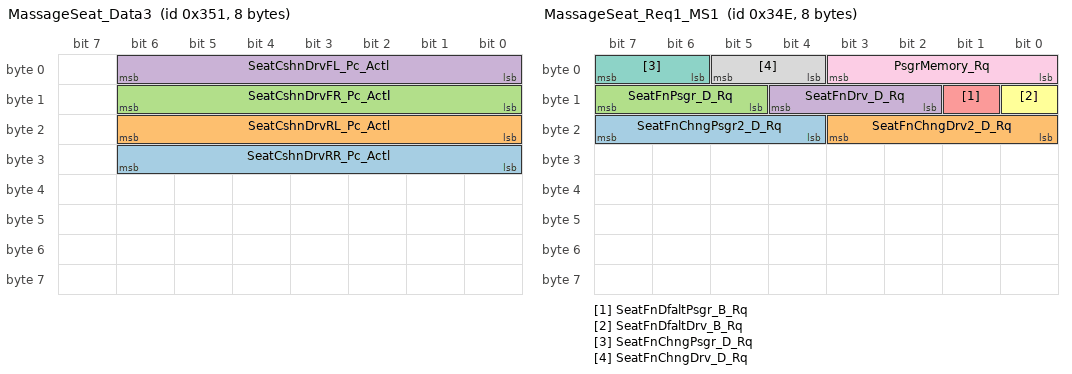
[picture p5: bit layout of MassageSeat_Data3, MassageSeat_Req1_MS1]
BO_ 849 MassageSeat_Data3: 8 SCMG
 SG_ SeatCshnDrvRR_Pc_Actl : 30|7@0+ (1,0) [0|126] "Percent"  GWM
 SG_ SeatCshnDrvRL_Pc_Actl : 22|7@0+ (1,0) [0|126] "Percent"  GWM
 SG_ SeatCshnDrvFR_Pc_Actl : 14|7@0+ (1,0) [0|126] "Percent"  GWM
 SG_ SeatCshnDrvFL_Pc_Actl : 6|7@0+ (1,0) [0|126] "Percent"  GWM

BO_ 846 MassageSeat_Req1_MS1: 8 GWM
 SG_ SeatFnChngPsgr2_D_Rq : 23|4@0+ (1,0) [0|15] "SED"  SCMG,SCMH
 SG_ SeatFnChngDrv2_D_Rq : 19|4@0+ (1,0) [0|15] "SED"  SCMG,SCMH
 SG_ SeatFnPsgr_D_Rq : 15|3@0+ (1,0) [0|7] "SED"  SCMH,SCMG
 SG_ SeatFnDrv_D_Rq : 12|3@0+ (1,0) [0|7] "SED"  SCMH,SCMG
 SG_ SeatFnDfaltPsgr_B_Rq : 9|1@0+ (1,0) [0|1] "SED"  SCMH,SCMG
 SG_ SeatFnDfaltDrv_B_Rq : 8|1@0+ (1,0) [0|1] "SED"  SCMH,SCMG
 SG_ SeatFnChngPsgr_D_Rq : 7|2@0+ (1,0) [0|3] "SED"  SCMH,SCMG
 SG_ SeatFnChngDrv_D_Rq : 5|2@0+ (1,0) [0|3] "SED"  SCMH,SCMG
 SG_ PsgrMemory_Rq : 3|4@0+ (1,0) [0|15] "SED"  SCMH,SCMG

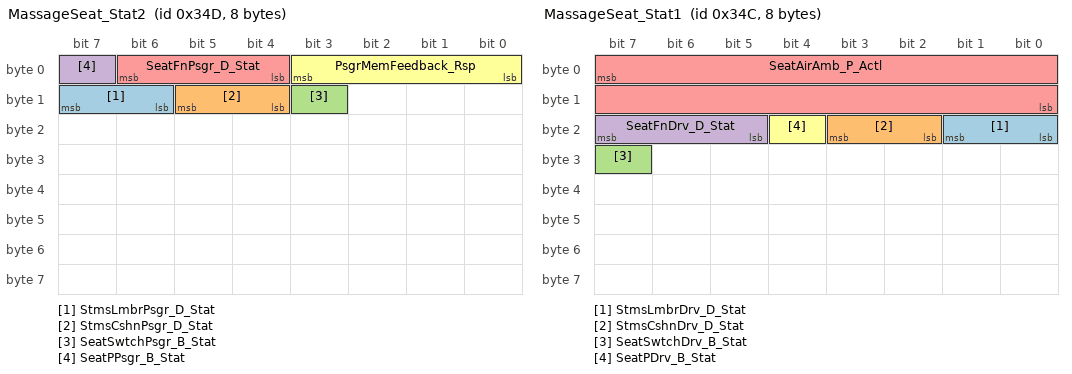
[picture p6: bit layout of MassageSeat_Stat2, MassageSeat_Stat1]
BO_ 845 MassageSeat_Stat2: 8 SCMH
 SG_ StmsLmbrPsgr_D_Stat : 15|2@0+ (1,0) [0|3] "SED"  GWM
 SG_ StmsCshnPsgr_D_Stat : 13|2@0+ (1,0) [0|3] "SED"  GWM
 SG_ SeatSwtchPsgr_B_Stat : 11|1@0+ (1,0) [0|1] "SED"  GWM
 SG_ SeatPPsgr_B_Stat : 7|1@0+ (1,0) [0|1] "SED"  GWM
 SG_ SeatFnPsgr_D_Stat : 6|3@0+ (1,0) [0|7] "SED"  GWM
 SG_ PsgrMemFeedback_Rsp : 3|4@0+ (1,0) [0|15] "SED"  GWM

BO_ 844 MassageSeat_Stat1: 8 SCMG
 SG_ StmsLmbrDrv_D_Stat : 17|2@0+ (1,0) [0|3] "SED"  GWM
 SG_ StmsCshnDrv_D_Stat : 19|2@0+ (1,0) [0|3] "SED"  GWM
 SG_ SeatSwtchDrv_B_Stat : 31|1@0+ (1,0) [0|1] "SED"  GWM
 SG_ SeatFnDrv_D_Stat : 23|3@0+ (1,0) [0|7] "SED"  GWM
 SG_ SeatAirAmb_P_Actl : 7|16@0+ (0.01,0) [0|655.35] "KiloPascal"  SCMH
 SG_ SeatPDrv_B_Stat : 20|1@0+ (1,0) [0|1] "SED"  GWM

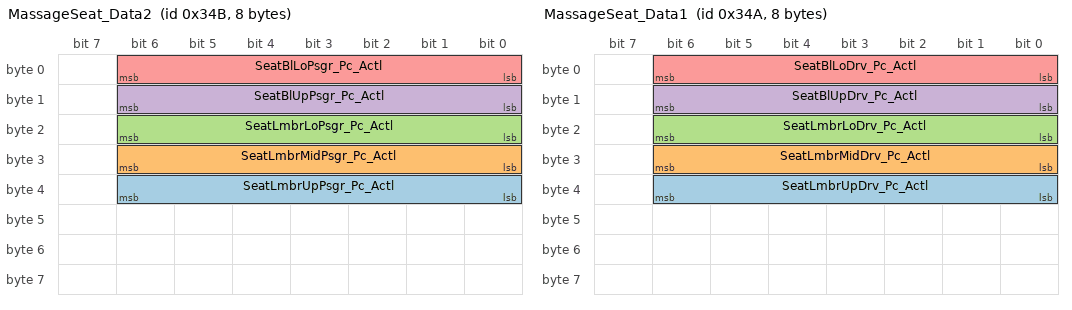
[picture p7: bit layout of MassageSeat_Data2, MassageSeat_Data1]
BO_ 843 MassageSeat_Data2: 8 SCMH
 SG_ SeatLmbrUpPsgr_Pc_Actl : 38|7@0+ (1,0) [0|126] "Percent"  GWM
 SG_ SeatLmbrMidPsgr_Pc_Actl : 30|7@0+ (1,0) [0|126] "Percent"  GWM
 SG_ SeatLmbrLoPsgr_Pc_Actl : 22|7@0+ (1,0) [0|126] "Percent"  GWM
 SG_ SeatBlUpPsgr_Pc_Actl : 14|7@0+ (1,0) [0|126] "Percent"  GWM
 SG_ SeatBlLoPsgr_Pc_Actl : 6|7@0+ (1,0) [0|126] "Percent"  GWM

BO_ 842 MassageSeat_Data1: 8 SCMG
 SG_ SeatLmbrUpDrv_Pc_Actl : 38|7@0+ (1,0) [0|126] "Percent"  GWM
 SG_ SeatLmbrMidDrv_Pc_Actl : 30|7@0+ (1,0) [0|126] "Percent"  GWM
 SG_ SeatLmbrLoDrv_Pc_Actl : 22|7@0+ (1,0) [0|126] "Percent"  GWM
 SG_ SeatBlUpDrv_Pc_Actl : 14|7@0+ (1,0) [0|126] "Percent"  GWM
 SG_ SeatBlLoDrv_Pc_Actl : 6|7@0+ (1,0) [0|126] "Percent"  GWM

BO_ 1994 TesterPhysicalResRSM: 8 RSM
 SG_ TesterPhysicalResRSM : 7|64@0+ (1,0) [0|1.84467E+019] "unitless"  TSTR

BO_ 1986 TesterPhysicalReqRSM: 8 TSTR
 SG_ TesterPhysicalReqRSM : 7|64@0+ (1,0) [0|1.84467E+019] "unitless"  RSM

BO_ 1383 RSM_Network_MgmtM: 8 RSM
 SG_ RSM_Network_Mgmt : 7|64@0+ (1,0) [0|1.844674407371E+019] "unitless"  DDM,DSM,FCIM,GPSM,PDM,RBM,GWM,RTM,SCME,TRM

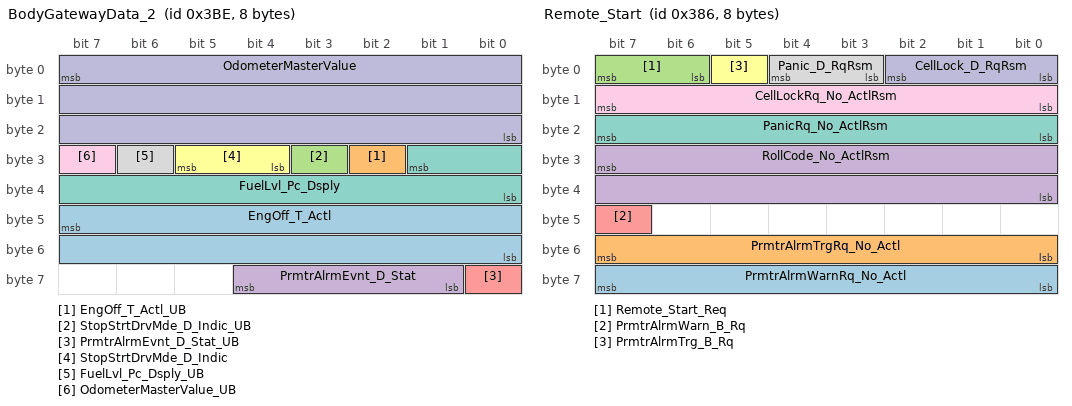
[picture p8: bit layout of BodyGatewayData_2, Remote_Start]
BO_ 958 BodyGatewayData_2: 8 GWM
 SG_ EngOff_T_Actl : 47|16@0+ (1,0) [0|65534] "seconds"  FCIM
 SG_ EngOff_T_Actl_UB : 26|1@0+ (1,0) [0|1] "SED"  FCIM
 SG_ StopStrtDrvMde_D_Indic_UB : 27|1@0+ (1,0) [0|1] "SED"  FCIM
 SG_ PrmtrAlrmEvnt_D_Stat : 60|4@0+ (1,0) [0|15] "SED"  RSM
 SG_ PrmtrAlrmEvnt_D_Stat_UB : 56|1@0+ (1,0) [0|1] "SED"  RSM
 SG_ StopStrtDrvMde_D_Indic : 29|2@0+ (1,0) [0|3] "SED"  FCIM
 SG_ FuelLvl_Pc_Dsply : 25|10@0+ (0.108696,-5.217408) [-5.217408|105.9786] "Percent" Vector__XXX
 SG_ FuelLvl_Pc_Dsply_UB : 30|1@0+ (1,0) [0|1] "SED" Vector__XXX
 SG_ OdometerMasterValue_UB : 31|1@0+ (1,0) [0|1] "SED" Vector__XXX
 SG_ OdometerMasterValue : 7|24@0+ (1,0) [0|16777214] "km" Vector__XXX

BO_ 827 SteeringSw_Stat_MS1: 8 GWM
 SG_ SteClmnSwtchTlt_D_Stat : 5|2@0+ (1,0) [0|3] "SED"  DSM
 SG_ SteClmnSwtchTel_D_Stat : 7|2@0+ (1,0) [0|3] "SED"  DSM

BO_ 902 Remote_Start: 8 RSM
 SG_ PrmtrAlrmWarnRq_No_Actl : 63|8@0+ (1,0) [0|255] "unitless"  GWM
 SG_ PrmtrAlrmTrgRq_No_Actl : 55|8@0+ (1,0) [0|255] "unitless"  GWM
 SG_ Remote_Start_Req : 7|2@0+ (1,0) [0|3] "SED"  GWM
 SG_ RollCode_No_ActlRsm : 31|16@0+ (1,0) [0|65535] "unitless"  GWM
 SG_ PrmtrAlrmWarn_B_Rq : 47|1@0+ (1,0) [0|1] "SED"  GWM
 SG_ PrmtrAlrmTrg_B_Rq : 5|1@0+ (1,0) [0|1] "SED"  GWM
 SG_ PanicRq_No_ActlRsm : 23|8@0+ (1,0) [0|255] "unitless"  GWM
 SG_ Panic_D_RqRsm : 4|2@0+ (1,0) [0|3] "SED"  GWM
 SG_ CellLockRq_No_ActlRsm : 15|8@0+ (1,0) [0|255] "unitless"  GWM
 SG_ CellLock_D_RqRsm : 2|3@0+ (1,0) [0|7] "SED"  GWM

BO_ 765 HS3_GatewayData_MS1: 8 GWM
 SG_ EmPrflButtnAssoc_D_Rq_UB : 56|1@0+ (1,0) [0|1] "SED" Vector__XXX
 SG_ EmPrflButtnAssoc_D_Rq : 17|2@0+ (1,0) [0|3] "SED"  DSM
 SG_ ValetMode_D_Stat_UB : 35|1@0+ (1,0) [0|1] "SED"  DSM
 SG_ ValetMode_D_Stat : 25|2@0+ (1,0) [0|3] "SED"  DSM
 SG_ TrlrBrkActCnnct_B_Actl_UB : 62|1@0+ (1,0) [0|1] "SED"  SODL,SODR
 SG_ TrlrBrkActCnnct_B_Actl : 63|1@0+ (1,0) [0|1] "SED"  SODL,SODR
 SG_ TrlrAidMsgTxt_D_Rq_UB : 48|1@0+ (1,0) [0|1] "SED"  TRM
 SG_ TrlrAidMsgTxt_D_Rq : 53|5@0+ (1,0) [0|31] "SED"  TRM
 SG_ Voice_Blower_Limit_UB : 44|1@0+ (1,0) [0|1] "SED"  FCIM
 SG_ Voice_Blower_Limit : 45|1@0+ (1,0) [0|1] "SED"  FCIM
 SG_ CamraFrntStat_D_Stat_UB : 32|1@0+ (1,0) [0|1] "SED" Vector__XXX
 SG_ CamraFrntStat_D_Stat : 34|2@0+ (1,0) [0|3] "SED" Vector__XXX
 SG_ SteWhlHeat_D_Stat : 39|4@0+ (1,0) [0|15] "SED"  FCIM
 SG_ Running_Board_Cmd_UB : 27|1@0+ (1,0) [0|1] "SED"  RBM
 SG_ Running_Board_Cmd : 29|2@0+ (1,0) [0|3] "SED"  RBM
 SG_ Bezel_Beeps_Rq_UB : 18|1@0+ (1,0) [0|1] "SED"  FCIM
 SG_ Bezel_Beeps_Rq : 20|2@0+ (1,0) [0|3] "unitless"  FCIM
 SG_ Diagnostic_Operation_Rq_UB : 21|1@0+ (1,0) [0|1] "SED"  FCIM
 SG_ Bezel_Diag_State_Rq_UB : 23|1@0+ (1,0) [0|1] "SED"  FCIM
 SG_ Bezel_Diag_Module_Rq_UB : 22|1@0+ (1,0) [0|1] "SED"  FCIM
 SG_ Diagnostic_Operation_Rq : 11|4@0+ (1,0) [0|15] "unitless"  FCIM
 SG_ Bezel_Diag_State_Rq : 1|2@0+ (1,0) [0|3] "unitless"  FCIM
 SG_ Bezel_Diag_Module_Rq : 15|4@0+ (1,0) [0|15] "unitless"  FCIM
 SG_ HMI_HMIMode_St_UB : 2|1@0+ (1,0) [0|1] "SED"  FCIM
 SG_ HMI_HMIMode_St : 5|3@0+ (1,0) [0|7] "unitless"  FCIM
 SG_ Mc_VehUnitTempUsrSel_St_UB : 6|1@0+ (1,0) [0|1] "SED"  FCIM
 SG_ Mc_VehUnitTempUsrSel_St : 7|1@0+ (1,0) [0|1] "unitless"  FCIM
 SG_ SteWhlHeat_D_Stat_UB : 26|1@0+ (1,0) [0|1] "SED"  FCIM
 SG_ ParkDetect_Stat_UB : 30|1@0+ (1,0) [0|1] "SED"  RSM
 SG_ ParkDetect_Stat : 31|1@0+ (1,0) [0|1] "SED"  RSM

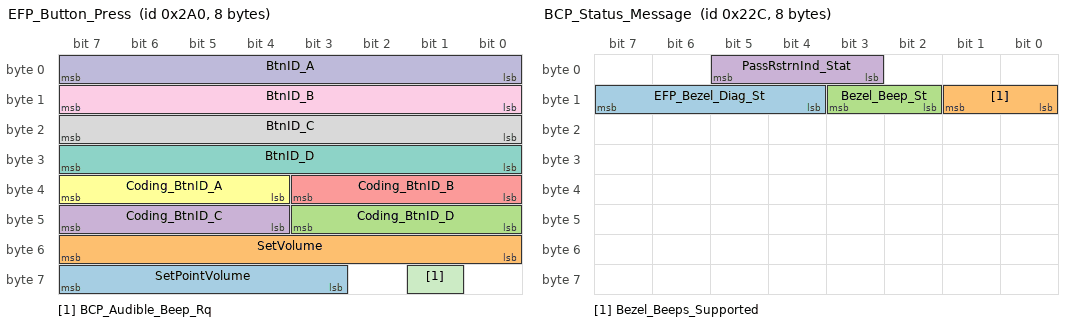
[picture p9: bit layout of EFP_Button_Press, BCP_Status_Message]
BO_ 672 EFP_Button_Press: 8 FCIM
 SG_ SetPointVolume : 63|5@0+ (1,0) [0|31] "unitless"  GWM
 SG_ SetVolume : 55|8@0+ (1,-30) [-30|30] "unitless"  GWM
 SG_ Coding_BtnID_D : 43|4@0+ (1,0) [0|15] "unitless"  GWM
 SG_ Coding_BtnID_C : 47|4@0+ (1,0) [0|15] "unitless"  GWM
 SG_ Coding_BtnID_B : 35|4@0+ (1,0) [0|15] "unitless"  GWM
 SG_ Coding_BtnID_A : 39|4@0+ (1,0) [0|15] "unitless"  GWM
 SG_ BtnID_D : 31|8@0+ (1,0) [0|255] "unitless"  GWM
 SG_ BtnID_C : 23|8@0+ (1,0) [0|255] "unitless"  GWM
 SG_ BtnID_B : 15|8@0+ (1,0) [0|255] "unitless"  GWM
 SG_ BtnID_A : 7|8@0+ (1,0) [0|255] "unitless"  GWM
 SG_ BCP_Audible_Beep_Rq : 57|1@0+ (1,0) [0|1] "unitless"  GWM

BO_ 710 BEZEL_RDISP_WORD_Tx: 8 FCIM
 SG_ BEZEL_RDISP_WORD_Tx : 7|64@0+ (1,0) [0|1.844674407371E+019] "unitless"  GWM

BO_ 556 BCP_Status_Message: 8 FCIM
 SG_ EFP_Bezel_Diag_St : 15|4@0+ (1,0) [0|15] "unitless"  GWM
 SG_ Bezel_Beeps_Supported : 9|2@0+ (1,0) [0|3] "unitless"  GWM
 SG_ Bezel_Beep_St : 11|2@0+ (1,0) [0|3] "unitless"  GWM
 SG_ PassRstrnInd_Stat : 5|3@0+ (1,0) [0|7] "SED"  GWM

CM_ BU_ TRM "Trailer Module";
CM_ BU_ GWM "Gateway Module CGEA1.3(Star Architecture)";
CM_ BU_ APIM "Accessory Protocol Interface Module, also known as MGM (Multimedia Gateway Module)
Note: Using CPM node id, Must be updated to GMRDB id's in 2007' (5/1/07)";
CM_ BU_ SODL "Side Obstacle Detection Control Module - Left (Primary)";
CM_ BU_ RTM "Radio Transceiver Module(RFA,TPM)";
CM_ BU_ FCIM "Front Controls Interface Module (EFP: Electronic Finish Panel, Integrated HVAC)";
CM_ BU_ PDM "Passenger Front Door Module ";
CM_ BU_ SCMH "Massaging Seat - Passenger";
CM_ BU_ SCMG "Massaging Seat - Driver";
CM_ BU_ HSWM "Heated Steering Wheel Module ";
CM_ BU_ GPSM "Global Positioning System Module";
CM_ BU_ RSM "Remote Start Module";
CM_ BU_ SODR "Side Obstacle Detection Control Module - Right

";
CM_ BU_ DDM "Driver Front Door Module, 2006 CD378 new module design";
CM_ BU_ RBM "Running Board Control Module, PRB (Power Running Board)";
CM_ BU_ DSM "Driver Front Seat Module";
CM_ BU_ SCME "Driver Climate Control Seat Module (alternate acronym DCSM),SME:Brian Nikiforuk";
CM_ BU_ TSTR "Diagnostic Tester";
CM_ SG_ 1189 Running_Board_Stat "Update msg. $115 to Event @ INIT in CMDB v4.06, 5/27/05.";
CM_ BO_ 948 "$3B4 used by CGEA SPDJB";
CM_ SG_ 839 FohKeyOff_B_Rq "Signal not transmitted on vehicles that do not have the Fuel operated heater feature.";
CM_ SG_ 765 Voice_Blower_Limit "VR session start- req. limit blower speed no more than X volts.  CC restriction on time msg. will be honored.Double Event msg1st event to request limit, 2nd event to release limit, No msg. CC Grammar v7.xls";
CM_ SG_ 765 Bezel_Beeps_Rq "Object: Vehicle Settings. Bezel_Beeps.Rq.BezelBeeps";
CM_ SG_ 765 Diagnostic_Operation_Rq "Object:BezelDiagnostics.MFD_Bezel_Diagnostic.St";
CM_ SG_ 765 Bezel_Diag_State_Rq "Object:BezelDiagnostics.MFD_Bezel_Diagnostic.Rq";
CM_ SG_ 765 Bezel_Diag_Module_Rq "Object:BezelDiagnostics.MFD_Bezel_Diagnostic.St";
CM_ SG_ 765 HMI_HMIMode_St "Object ACU System Master.HMIMode
OR
Object NAV System Master.HMIMode

Refer Method HMIAudioMode in the SPSS";
CM_ SG_ 765 Mc_VehUnitTempUsrSel_St "Object.VehicleSettings.Disp_Temperature.Rq";
CM_ BO_ 672 "Refer to the Input Translation Matrix for the button mapping in the method tables in the SPSS ";
CM_ SG_ 672 SetPointVolume "Method: EFP_Button_Press
0x0:Inactive
$0: Inactive
$1: No_Volume
$2: Volume_Step1
$3: Vol_Step2
$1F: Vol_Step30";
CM_ SG_ 672 SetVolume "$0: -30Steps
$1: -29Steps
$2: -28Steps
$1D: -1Step
$1E: NotPressed_Inactive
$1F: +1Step
$20: +2Steps
$21: +3Steps
$3C: +30Steps";
CM_ SG_ 672 Coding_BtnID_D "Object InputControlInterface ICI ButtonCoding_D
Object InputControlInterface ICI ButtonID_D";
CM_ SG_ 672 Coding_BtnID_C "Object InputControlInterface.ICI ButtonCoding_C
Object InputControlInterface.ICI ButtonID_C";
CM_ SG_ 672 Coding_BtnID_B "Object InputControlInterface ICI ButtonCoding_B
Object InputControlInterface.ICI ButtonID_B";
CM_ SG_ 672 Coding_BtnID_A "Object InputControlInterface ICI ButtonCoding_A
Object InputControlInterface.ICI ButtonID A";
CM_ SG_ 672 BtnID_D "Object InputControlInterface ICI ButtonID_D... 0xFF: Inactive";
CM_ SG_ 672 BtnID_C "Object InputControlInterface ICI ButtonID_D... 0xFF: Inactive";
CM_ SG_ 672 BtnID_B "Object InputControlInterface ICI ButtonID_D... 0xFF: Inactive";
CM_ SG_ 672 BtnID_A "Object InputControlInterface ICI ButtonID_D... 0xFF: Inactive";
CM_ SG_ 672 BCP_Audible_Beep_Rq "Object.AlertMethod.BCP_Audible_Beep";
CM_ SG_ 556 EFP_Bezel_Diag_St "Object:BezelDiagnostics.EFP_Bezel_Diag.St";
CM_ SG_ 556 Bezel_Beeps_Supported "Object: Vehicle Settings. Bezel_Beeps_Supported.St";
CM_ SG_ 556 Bezel_Beep_St "Object:VehicleSettings.Bezel_Beeps.St.Status";
BA_DEF_ SG_  "U_V36X_MY18_5_Gas_Rx" ENUM  "No","Yes";
BA_DEF_ SG_  "U_V36X_MY18_5_Hev_Rx" ENUM  "No","Yes";
BA_DEF_ SG_  "U_U55x_MY18_Gas_Rx" ENUM  "No","Yes";
BA_DEF_ SG_  "U_V408_MY18_Gas_Rx" ENUM  "No","Yes";
BA_DEF_ SG_  "U_V408_MY18_Diesel_Rx" ENUM  "No","Yes";
BA_DEF_ SG_  "U_V36X_MY18_5_Diesel_Rx" ENUM  "No","Yes";
BA_DEF_ SG_  "U_V36X_MY19_5_Diesel_Rx" ENUM  "No","Yes";
BA_DEF_ SG_  "U_V363E_N_MY19_5_20_Gas_Rx" ENUM  "No","Yes";
BA_DEF_ SG_  "U_V363E_N_MY19_5_20_Diesel_Rx" ENUM  "No","Yes";
BA_DEF_ SG_  "U_U55x_MY18_Gas_Tx" ENUM  "No","Yes";
BA_DEF_ SG_  "GenSigTimeoutTime_SCMJ" INT 0 100000;
BA_DEF_ BO_  "FrameGatewayNetwork" STRING ;
BA_DEF_ SG_  "U_CD42_MY16_Diesel_Rx" ENUM  "No","Yes";
BA_DEF_ SG_  "U_CD42_MY16_Gas_Rx" ENUM  "No","Yes";
BA_DEF_ SG_  "U_CD43_MY17_Gas_Rx" ENUM  "No","Yes";
BA_DEF_ SG_  "U_P552_MY17_Gas_Rx" ENUM  "No","Yes";
BA_DEF_ SG_  "U_P552_MY17_Gas_Tx" ENUM  "No","Yes";
BA_DEF_ SG_  "GenSigTimeoutTime_SOBDMD_AHCM_F" INT 0 100000;
BA_DEF_ SG_  "GenSigTimeoutTime_SFMA" INT 0 100000;
BA_DEF_ SG_  "GenSigTimeoutTime_SFMB" INT 0 100000;
BA_DEF_ SG_  "GenSigTimeoutTime_SCMD" INT 0 100000;
BA_DEF_ SG_  "GenSigTimeoutTime_DCMH" INT 0 100000;
BA_DEF_ SG_  "GenSigTimeoutTime_DCMG" INT 0 100000;
BA_DEF_ SG_  "GenSigTimeoutTime_DCMF" INT 0 100000;
BA_DEF_ SG_  "GenSigTimeoutTime_DCME" INT 0 100000;
BA_DEF_ SG_  "GenSigTimeoutTime_BCMB_ABM" INT 0 100000;
BA_DEF_ SG_  "GenSigTimeoutTime_SCMC" INT 0 100000;
BA_DEF_ SG_  "GenSigTimeoutTime_BCMB_CAPM" INT 0 100000;
BA_DEF_ SG_  "GenSigTimeoutTime_GFM_ASM" INT 0 100000;
BA_DEF_ SG_  "GenSigTimeoutTime_SCMB_PSM" INT 0 100000;
BA_DEF_ SG_  "GenSigTimeoutTime_BCMB_ALCM" INT 0 100000;
BA_DEF_ SG_  "U_CD42_MY15_Diesel_Rx" ENUM  "No","Yes";
BA_DEF_ SG_  "U_CD42_MY15_Gas_Rx" ENUM  "No","Yes";
BA_DEF_ SG_  "U_U502_MY16_Gas_Rx" ENUM  "No","Yes";
BA_DEF_ SG_  "U_P558_MY17_Gas_Rx" ENUM  "No","Yes";
BA_DEF_ SG_  "U_P558_MY17_Diesel_Rx" ENUM  "No","Yes";
BA_DEF_ SG_  "U_CD42_MY15_Diesel_Tx" ENUM  "No","Yes";
BA_DEF_ SG_  "U_CD42_MY15_Gas_Tx" ENUM  "No","Yes";
BA_DEF_ SG_  "U_CD4_MY15_Diesel_Tx" ENUM  "No","Yes";
BA_DEF_ SG_  "U_CD4_MY15_Gas_Tx" ENUM  "No","Yes";
BA_DEF_ SG_  "U_CD4_MY15_Hev_Tx" ENUM  "No","Yes";
BA_DEF_ SG_  "U_CD4_MY15_Phev_Tx" ENUM  "No","Yes";
BA_DEF_ SG_  "U_P558_MY17_Gas_Tx" ENUM  "No","Yes";
BA_DEF_ SG_  "U_P558_MY17_Diesel_Tx" ENUM  "No","Yes";
BA_DEF_ SG_  "GenSigTimeoutTime_SCMF" INT 0 100000;
BA_DEF_ SG_  "GenSigTimeoutTime_RGTM" INT 0 100000;
BA_DEF_ SG_  "GenSigTimeoutTime_GENERIC" INT 0 100000;
BA_DEF_ SG_  "GenSigTimeoutTime_AHCM_FOH" INT 0 100000;
BA_DEF_ SG_  "GenSigTimeoutTime_RLCMA" INT 0 100000;
BA_DEF_ SG_  "GenSigTimeoutTime_BCMB" INT 0 100000;
BA_DEF_ SG_  "GenSigTimeoutTime_RHVAC" INT 0 100000;
BA_DEF_ SG_  "GenSigTimeoutTime_MRCMB" INT 0 100000;
BA_DEF_ SG_  "GenSigTimeoutTime_MRCMA" INT 0 100000;
BA_DEF_ SG_  "GenSigTimeoutTime_HVAC_RCCM" INT 0 100000;
BA_DEF_ SG_  "Gateway_ID" INT 0 0;
BA_DEF_ SG_  "GenSigTimeoutTime__delete" INT 0 100000;
BA_DEF_ SG_  "GenSigTimeoutTime_APIM" INT 0 100000;
BA_DEF_ SG_  "GenSigTimeoutTime_Generic_BCM" INT 0 100000;
BA_DEF_ SG_  "GenSigTimeoutTime_RSM" INT 0 100000;
BA_DEF_ SG_  "GenSigTimeoutTime_PDM" INT 0 100000;
BA_DEF_ SG_  "GenSigTimeoutTime_TRM" INT 0 100000;
BA_DEF_ SG_  "GenSigTimeoutTime_SCMG" INT 0 100000;
BA_DEF_ SG_  "GenSigTimeoutTime_SCMH" INT 0 100000;
BA_DEF_ SG_  "GenSigTimeoutTime_RTM" INT 0 100000;
BA_DEF_ SG_  "GenSigTimeoutTime_GWM" INT 0 100000;
BA_DEF_ SG_  "GenSigTimeoutTime_FCIM" INT 0 100000;
BA_DEF_ SG_  "GenSigTimeoutTime_HSWM" INT 0 100000;
BA_DEF_ SG_  "GenSigTimeoutTime_GPSM" INT 0 100000;
BA_DEF_ SG_  "GenSigTimeoutTime_RBM" INT 0 100000;
BA_DEF_ SG_  "GenSigTimeoutTime_DDM" INT 0 100000;
BA_DEF_ SG_  "GenSigTimeoutTime_DSM" INT 0 100000;
BA_DEF_ SG_  "GenSigTimeoutTime_SODR" INT 0 100000;
BA_DEF_ SG_  "GenSigTimeoutTime_SODL" INT 0 100000;
BA_DEF_ SG_  "GenSigTimeoutTime_TSTR" INT 0 100000;
BA_DEF_ SG_  "GenSigTimeoutTime_SCME" INT 0 100000;
BA_DEF_  "BusType" STRING ;
BA_DEF_ BO_  "FrameGatewayMS1" HEX 0 1407;
BA_DEF_ BO_  "FrameGatewayHS3" HEX 0 1407;
BA_DEF_ BO_  "FrameGatewayHS2" HEX 0 1407;
BA_DEF_ BO_  "FrameGatewayHS1" HEX 0 1407;
BA_DEF_ BO_  "NetworkInitialization" ENUM  "No","Yes";
BA_DEF_ BO_  "FrameGatewayId" HEX 0 1407;
BA_DEF_ BO_  "EventRateOfChange" INT 10 10000;
BA_DEF_ BO_  "GenMsgStartDelayTime" INT 0 10000;
BA_DEF_ BO_  "GenMsgNrOfRepetition" INT 0 100;
BA_DEF_ BO_  "GenMsgDelayTime" INT 0 1000;
BA_DEF_ BO_  "GenMsgCycleTime" INT 0 100000;
BA_DEF_ BO_  "GenMsgSendType" ENUM  "FixedPeriodic","Event","EnabledPeriodic","NotUsed","NotUsed","EventPeriodic","NotUsed","NotUsed","NoMsgSendType";
BA_DEF_ SG_  "U_CD4_MY14_Phev_Tx" ENUM  "No","Yes";
BA_DEF_ SG_  "U_CD4_MY14_Hev_Tx" ENUM  "No","Yes";
BA_DEF_ SG_  "U_CD4_MY14_Gas_Tx" ENUM  "No","Yes";
BA_DEF_ SG_  "U_CD4_MY14_Diesel_Tx" ENUM  "No","Yes";
BA_DEF_ SG_  "U_CD43_MY16_Gas_Tx" ENUM  "No","Yes";
BA_DEF_ SG_  "U_UP375_MY15_Diesel_Tx" ENUM  "No","Yes";
BA_DEF_ SG_  "U_UP375_MY15_Gas_Tx" ENUM  "No","Yes";
BA_DEF_ SG_  "U_U502_MY15_Gas_Tx" ENUM  "No","Yes";
BA_DEF_ SG_  "U_B562LC_MY14_Gas_Tx" ENUM  "No","Yes";
BA_DEF_ SG_  "U_B562LC_MY14_Diesel_Tx" ENUM  "No","Yes";
BA_DEF_ SG_  "U_C489_MY14_Gas_Tx" ENUM  "No","Yes";
BA_DEF_ SG_  "U_S550_MY15_Gas_Tx" ENUM  "No","Yes";
BA_DEF_ SG_  "U_P552_MY15_Gas_Tx" ENUM  "No","Yes";
BA_DEF_ SG_  "U_CD42_MY14_Gas_Tx" ENUM  "No","Yes";
BA_DEF_ SG_  "U_CD42_MY14_Diesel_Tx" ENUM  "No","Yes";
BA_DEF_ SG_  "U_CD4_MY13_Phev_Tx" ENUM  "No","Yes";
BA_DEF_ SG_  "U_CD4_MY13_Hev_Tx" ENUM  "No","Yes";
BA_DEF_ SG_  "U_CD4_MY13_Gas_Tx" ENUM  "No","Yes";
BA_DEF_ SG_  "U_CD4_MY13_Diesel_Tx" ENUM  "No","Yes";
BA_DEF_ SG_  "U_CD4_MY14_Phev_Rx" ENUM  "No","Yes";
BA_DEF_ SG_  "U_CD4_MY14_Hev_Rx" ENUM  "No","Yes";
BA_DEF_ SG_  "U_CD4_MY14_Gas_Rx" ENUM  "No","Yes";
BA_DEF_ SG_  "U_CD4_MY14_Diesel_Rx" ENUM  "No","Yes";
BA_DEF_ SG_  "U_CD43_MY16_Gas_Rx" ENUM  "No","Yes";
BA_DEF_ SG_  "U_UP375_MY15_Diesel_Rx" ENUM  "No","Yes";
BA_DEF_ SG_  "U_UP375_MY15_Gas_Rx" ENUM  "No","Yes";
BA_DEF_ SG_  "U_B479_MY15_Gas_Rx" ENUM  "No","Yes";
BA_DEF_ SG_  "U_U502_MY15_Gas_Rx" ENUM  "No","Yes";
BA_DEF_ SG_  "U_B562LC_MY14_Gas_Rx" ENUM  "No","Yes";
BA_DEF_ SG_  "U_B562LC_MY14_Diesel_Rx" ENUM  "No","Yes";
BA_DEF_ SG_  "U_C489_MY14_Gas_Rx" ENUM  "No","Yes";
BA_DEF_ SG_  "U_S550_MY15_Gas_Rx" ENUM  "No","Yes";
BA_DEF_ SG_  "U_P552_MY15_Gas_Rx" ENUM  "No","Yes";
BA_DEF_ SG_  "U_CD42_MY14_Gas_Rx" ENUM  "No","Yes";
BA_DEF_ SG_  "U_CD42_MY14_Diesel_Rx" ENUM  "No","Yes";
BA_DEF_ SG_  "U_CD4_MY13_Phev_Rx" ENUM  "No","Yes";
BA_DEF_ SG_  "U_CD4_MY13_Hev_Rx" ENUM  "No","Yes";
BA_DEF_ SG_  "U_CD4_MY13_Gas_Rx" ENUM  "No","Yes";
BA_DEF_ SG_  "U_CD4_MY13_Diesel_Rx" ENUM  "No","Yes";
BA_DEF_ SG_  "ContentDependant" ENUM  "No","Yes";
BA_DEF_ SG_  "GenSigStartValue" INT 0 1000000000;
BA_DEF_ SG_  "UsedOnPgmDBC" ENUM  "No","Yes";
BA_DEF_ SG_  "CrossOver_LIN" ENUM  "No","Yes";
BA_DEF_ SG_  "CrossOver_InfoCAN" ENUM  "No","Yes";
BA_DEF_ SG_  "WakeupSignal" ENUM  "No","Yes";
BA_DEF_ SG_  "FMC_SIG_SSPEC" STRING ;
BA_DEF_ SG_  "GenSigMissingSourceValue" INT 0 1000000000;
BA_DEF_ SG_  "GenSigInactiveValue" INT 0 100000;
BA_DEF_ SG_  "GenSigSendType" ENUM  "Cyclic","OnWrite","vector_leerstring","OnChange","vector_leerstring","IfActive","vector_leerstring","NoSigSendType";
BA_DEF_ BO_  "DiagState" ENUM  "No","Yes";
BA_DEF_ BO_  "TpTxIndex" INT 0 255;
BA_DEF_ BO_  "DiagRequest" ENUM  "No","Yes";
BA_DEF_ BO_  "DiagResponse" ENUM  "No","Yes";
BA_DEF_ BO_  "NmMessage" ENUM  "No","Yes";
BA_DEF_ BO_  "GenMsgILSupport" ENUM  "No","Yes";
BA_DEF_ BU_  "Terminator" ENUM  "No","Yes";
BA_DEF_ BU_  "NodeWakeUpTime" INT 0 1000;
BA_DEF_ BU_  "NodeStartUpTime" INT 0 4500;
BA_DEF_ BU_  "NmAsrNodeIdentifier" HEX 128 255;
BA_DEF_ BU_  "PowerType" ENUM  "Switched","Latched","Sleep","vector_leerstring","vector_leerstring";
BA_DEF_ BU_  "DiagNode" ENUM  "GGDS","GDS","NONE";
BA_DEF_ BU_  "EOL_SB_Flash" ENUM  "GGDS","GDS","NONE","vector_leerstring";
BA_DEF_ BU_  "NetworkInitializationUsed" ENUM  "No","Yes";
BA_DEF_ BU_  "NmNode" ENUM  "No","Yes";
BA_DEF_ BU_  "NmStationAddress" INT 0 255;
BA_DEF_ BU_  "ILUsed" ENUM  "No","Yes";
BA_DEF_ BU_  "NosPackage" ENUM  "None","I3_1","I3_2","1.0.1","RP","EuCD","Volcano";
BA_DEF_ BU_  "PackageID" STRING ;
BA_DEF_ BU_  "GatewayECU" ENUM  "No","Yes";
BA_DEF_  "StarNetworkGwType" ENUM  "0=NotDefined","1=HS1","2=HS2","3=HS3","4=HS4","5=HS5","6=MS1";
BA_DEF_  "CMDB_Version" STRING ;
BA_DEF_  "NmType" STRING ;
BA_DEF_  "NetworkSpeed" ENUM  "500kBits/s","125kBit/s";
BA_DEF_  "NmAsrMessageCount" INT 128 128;
BA_DEF_  "NmAsrBaseAddress" HEX 1408 1408;
BA_DEF_  "DBName" STRING ;
BA_DEF_  "VersionDay" INT 1 31;
BA_DEF_  "Manufacturer" STRING ;
BA_DEF_  "VersionNumber" INT 0 10000;
BA_DEF_  "VersionMonth" INT 1 12;
BA_DEF_  "VersionYear" INT 2000 3000;
BA_DEF_  "NmBaseAddress" HEX 1280 1280;
BA_DEF_  "NmMessageCount" INT 0 128;
BA_DEF_DEF_  "U_V36X_MY18_5_Gas_Rx" "No";
BA_DEF_DEF_  "U_V36X_MY18_5_Hev_Rx" "No";
BA_DEF_DEF_  "U_U55x_MY18_Gas_Rx" "No";
BA_DEF_DEF_  "U_V408_MY18_Gas_Rx" "No";
BA_DEF_DEF_  "U_V408_MY18_Diesel_Rx" "No";
BA_DEF_DEF_  "U_V36X_MY18_5_Diesel_Rx" "No";
BA_DEF_DEF_  "U_V36X_MY19_5_Diesel_Rx" "No";
BA_DEF_DEF_  "U_V363E_N_MY19_5_20_Gas_Rx" "No";
BA_DEF_DEF_  "U_V363E_N_MY19_5_20_Diesel_Rx" "No";
BA_DEF_DEF_  "U_U55x_MY18_Gas_Tx" "No";
BA_DEF_DEF_  "GenSigTimeoutTime_SCMJ" 5000;
BA_DEF_DEF_  "FrameGatewayNetwork" "NONE";
BA_DEF_DEF_  "U_CD42_MY16_Diesel_Rx" "No";
BA_DEF_DEF_  "U_CD42_MY16_Gas_Rx" "No";
BA_DEF_DEF_  "U_CD43_MY17_Gas_Rx" "No";
BA_DEF_DEF_  "U_P552_MY17_Gas_Rx" "No";
BA_DEF_DEF_  "U_P552_MY17_Gas_Tx" "No";
BA_DEF_DEF_  "GenSigTimeoutTime_SOBDMD_AHCM_F" 5000;
BA_DEF_DEF_  "GenSigTimeoutTime_SFMA" 5000;
BA_DEF_DEF_  "GenSigTimeoutTime_SFMB" 5000;
BA_DEF_DEF_  "GenSigTimeoutTime_SCMD" 5000;
BA_DEF_DEF_  "GenSigTimeoutTime_DCMH" 5000;
BA_DEF_DEF_  "GenSigTimeoutTime_DCMG" 5000;
BA_DEF_DEF_  "GenSigTimeoutTime_DCMF" 5000;
BA_DEF_DEF_  "GenSigTimeoutTime_DCME" 5000;
BA_DEF_DEF_  "GenSigTimeoutTime_BCMB_ABM" 5000;
BA_DEF_DEF_  "GenSigTimeoutTime_SCMC" 5000;
BA_DEF_DEF_  "GenSigTimeoutTime_BCMB_CAPM" 5000;
BA_DEF_DEF_  "GenSigTimeoutTime_GFM_ASM" 5000;
BA_DEF_DEF_  "GenSigTimeoutTime_SCMB_PSM" 5000;
BA_DEF_DEF_  "GenSigTimeoutTime_BCMB_ALCM" 5000;
BA_DEF_DEF_  "U_CD42_MY15_Diesel_Rx" "No";
BA_DEF_DEF_  "U_CD42_MY15_Gas_Rx" "No";
BA_DEF_DEF_  "U_U502_MY16_Gas_Rx" "No";
BA_DEF_DEF_  "U_P558_MY17_Gas_Rx" "No";
BA_DEF_DEF_  "U_P558_MY17_Diesel_Rx" "No";
BA_DEF_DEF_  "U_CD42_MY15_Diesel_Tx" "No";
BA_DEF_DEF_  "U_CD42_MY15_Gas_Tx" "No";
BA_DEF_DEF_  "U_CD4_MY15_Diesel_Tx" "No";
BA_DEF_DEF_  "U_CD4_MY15_Gas_Tx" "No";
BA_DEF_DEF_  "U_CD4_MY15_Hev_Tx" "No";
BA_DEF_DEF_  "U_CD4_MY15_Phev_Tx" "No";
BA_DEF_DEF_  "U_P558_MY17_Gas_Tx" "No";
BA_DEF_DEF_  "U_P558_MY17_Diesel_Tx" "No";
BA_DEF_DEF_  "GenSigTimeoutTime_SCMF" 5000;
BA_DEF_DEF_  "GenSigTimeoutTime_RGTM" 5000;
BA_DEF_DEF_  "GenSigTimeoutTime_GENERIC" 5000;
BA_DEF_DEF_  "GenSigTimeoutTime_AHCM_FOH" 5000;
BA_DEF_DEF_  "GenSigTimeoutTime_RLCMA" 5000;
BA_DEF_DEF_  "GenSigTimeoutTime_BCMB" 5000;
BA_DEF_DEF_  "GenSigTimeoutTime_RHVAC" 5000;
BA_DEF_DEF_  "GenSigTimeoutTime_MRCMB" 5000;
BA_DEF_DEF_  "GenSigTimeoutTime_MRCMA" 5000;
BA_DEF_DEF_  "GenSigTimeoutTime_HVAC_RCCM" 5000;
BA_DEF_DEF_  "Gateway_ID" 0;
BA_DEF_DEF_  "GenSigTimeoutTime__delete" 5000;
BA_DEF_DEF_  "GenSigTimeoutTime_APIM" 5000;
BA_DEF_DEF_  "GenSigTimeoutTime_Generic_BCM" 5000;
BA_DEF_DEF_  "GenSigTimeoutTime_RSM" 5000;
BA_DEF_DEF_  "GenSigTimeoutTime_PDM" 5000;
BA_DEF_DEF_  "GenSigTimeoutTime_TRM" 5000;
BA_DEF_DEF_  "GenSigTimeoutTime_SCMG" 5000;
BA_DEF_DEF_  "GenSigTimeoutTime_SCMH" 5000;
BA_DEF_DEF_  "GenSigTimeoutTime_RTM" 5000;
BA_DEF_DEF_  "GenSigTimeoutTime_GWM" 5000;
BA_DEF_DEF_  "GenSigTimeoutTime_FCIM" 5000;
BA_DEF_DEF_  "GenSigTimeoutTime_HSWM" 5000;
BA_DEF_DEF_  "GenSigTimeoutTime_GPSM" 5000;
BA_DEF_DEF_  "GenSigTimeoutTime_RBM" 5000;
BA_DEF_DEF_  "GenSigTimeoutTime_DDM" 5000;
BA_DEF_DEF_  "GenSigTimeoutTime_DSM" 5000;
BA_DEF_DEF_  "GenSigTimeoutTime_SODR" 5000;
BA_DEF_DEF_  "GenSigTimeoutTime_SODL" 5000;
BA_DEF_DEF_  "GenSigTimeoutTime_TSTR" 5000;
BA_DEF_DEF_  "GenSigTimeoutTime_SCME" 5000;
BA_DEF_DEF_  "BusType" "";
BA_DEF_DEF_  "FrameGatewayMS1" 0;
BA_DEF_DEF_  "FrameGatewayHS3" 0;
BA_DEF_DEF_  "FrameGatewayHS2" 0;
BA_DEF_DEF_  "FrameGatewayHS1" 0;
BA_DEF_DEF_  "NetworkInitialization" "No";
BA_DEF_DEF_  "FrameGatewayId" 0;
BA_DEF_DEF_  "EventRateOfChange" 10000;
BA_DEF_DEF_  "GenMsgStartDelayTime" 0;
BA_DEF_DEF_  "GenMsgNrOfRepetition" 1;
BA_DEF_DEF_  "GenMsgDelayTime" 20;
BA_DEF_DEF_  "GenMsgCycleTime" 0;
BA_DEF_DEF_  "GenMsgSendType" "NoMsgSendType";
BA_DEF_DEF_  "U_CD4_MY14_Phev_Tx" "No";
BA_DEF_DEF_  "U_CD4_MY14_Hev_Tx" "No";
BA_DEF_DEF_  "U_CD4_MY14_Gas_Tx" "No";
BA_DEF_DEF_  "U_CD4_MY14_Diesel_Tx" "No";
BA_DEF_DEF_  "U_CD43_MY16_Gas_Tx" "No";
BA_DEF_DEF_  "U_UP375_MY15_Diesel_Tx" "No";
BA_DEF_DEF_  "U_UP375_MY15_Gas_Tx" "No";
BA_DEF_DEF_  "U_U502_MY15_Gas_Tx" "No";
BA_DEF_DEF_  "U_B562LC_MY14_Gas_Tx" "No";
BA_DEF_DEF_  "U_B562LC_MY14_Diesel_Tx" "No";
BA_DEF_DEF_  "U_C489_MY14_Gas_Tx" "No";
BA_DEF_DEF_  "U_S550_MY15_Gas_Tx" "No";
BA_DEF_DEF_  "U_P552_MY15_Gas_Tx" "No";
BA_DEF_DEF_  "U_CD42_MY14_Gas_Tx" "No";
BA_DEF_DEF_  "U_CD42_MY14_Diesel_Tx" "No";
BA_DEF_DEF_  "U_CD4_MY13_Phev_Tx" "No";
BA_DEF_DEF_  "U_CD4_MY13_Hev_Tx" "No";
BA_DEF_DEF_  "U_CD4_MY13_Gas_Tx" "No";
BA_DEF_DEF_  "U_CD4_MY13_Diesel_Tx" "No";
BA_DEF_DEF_  "U_CD4_MY14_Phev_Rx" "No";
BA_DEF_DEF_  "U_CD4_MY14_Hev_Rx" "No";
BA_DEF_DEF_  "U_CD4_MY14_Gas_Rx" "No";
BA_DEF_DEF_  "U_CD4_MY14_Diesel_Rx" "No";
BA_DEF_DEF_  "U_CD43_MY16_Gas_Rx" "No";
BA_DEF_DEF_  "U_UP375_MY15_Diesel_Rx" "No";
BA_DEF_DEF_  "U_UP375_MY15_Gas_Rx" "No";
BA_DEF_DEF_  "U_B479_MY15_Gas_Rx" "No";
BA_DEF_DEF_  "U_U502_MY15_Gas_Rx" "No";
BA_DEF_DEF_  "U_B562LC_MY14_Gas_Rx" "No";
BA_DEF_DEF_  "U_B562LC_MY14_Diesel_Rx" "No";
BA_DEF_DEF_  "U_C489_MY14_Gas_Rx" "No";
BA_DEF_DEF_  "U_S550_MY15_Gas_Rx" "No";
BA_DEF_DEF_  "U_P552_MY15_Gas_Rx" "No";
BA_DEF_DEF_  "U_CD42_MY14_Gas_Rx" "No";
BA_DEF_DEF_  "U_CD42_MY14_Diesel_Rx" "No";
BA_DEF_DEF_  "U_CD4_MY13_Phev_Rx" "No";
BA_DEF_DEF_  "U_CD4_MY13_Hev_Rx" "No";
BA_DEF_DEF_  "U_CD4_MY13_Gas_Rx" "No";
BA_DEF_DEF_  "U_CD4_MY13_Diesel_Rx" "No";
BA_DEF_DEF_  "ContentDependant" "No";
BA_DEF_DEF_  "GenSigStartValue" 0;
BA_DEF_DEF_  "UsedOnPgmDBC" "Yes";
BA_DEF_DEF_  "CrossOver_LIN" "No";
BA_DEF_DEF_  "CrossOver_InfoCAN" "No";
BA_DEF_DEF_  "WakeupSignal" "No";
BA_DEF_DEF_  "FMC_SIG_SSPEC" "Unknown";
BA_DEF_DEF_  "GenSigMissingSourceValue" 0;
BA_DEF_DEF_  "GenSigInactiveValue" 0;
BA_DEF_DEF_  "GenSigSendType" "NoSigSendType";
BA_DEF_DEF_  "DiagState" "No";
BA_DEF_DEF_  "TpTxIndex" 0;
BA_DEF_DEF_  "DiagRequest" "No";
BA_DEF_DEF_  "DiagResponse" "No";
BA_DEF_DEF_  "NmMessage" "No";
BA_DEF_DEF_  "GenMsgILSupport" "Yes";
BA_DEF_DEF_  "Terminator" "No";
BA_DEF_DEF_  "NodeWakeUpTime" 10;
BA_DEF_DEF_  "NodeStartUpTime" 250;
BA_DEF_DEF_  "NmAsrNodeIdentifier" 128;
BA_DEF_DEF_  "PowerType" "Switched";
BA_DEF_DEF_  "DiagNode" "GGDS";
BA_DEF_DEF_  "EOL_SB_Flash" "GGDS";
BA_DEF_DEF_  "NetworkInitializationUsed" "No";
BA_DEF_DEF_  "NmNode" "No";
BA_DEF_DEF_  "NmStationAddress" 0;
BA_DEF_DEF_  "ILUsed" "Yes";
BA_DEF_DEF_  "NosPackage" "I3_1";
BA_DEF_DEF_  "PackageID" "08.05.00.00.71.xx.xx.rr.00.00";
BA_DEF_DEF_  "GatewayECU" "No";
BA_DEF_DEF_  "StarNetworkGwType" "0=NotDefined";
BA_DEF_DEF_  "CMDB_Version" "v11.01";
BA_DEF_DEF_  "NmType" "Ford-OSEK";
BA_DEF_DEF_  "NetworkSpeed" "500kBits/s";
BA_DEF_DEF_  "NmAsrMessageCount" 128;
BA_DEF_DEF_  "NmAsrBaseAddress" 1408;
BA_DEF_DEF_  "DBName" "";
BA_DEF_DEF_  "VersionDay" 1;
BA_DEF_DEF_  "Manufacturer" "Ford";
BA_DEF_DEF_  "VersionNumber" 1;
BA_DEF_DEF_  "VersionMonth" 1;
BA_DEF_DEF_  "VersionYear" 2011;
BA_DEF_DEF_  "NmBaseAddress" 1280;
BA_DEF_DEF_  "NmMessageCount" 128;
BA_ "VersionDay" 20;
BA_ "BusType" "CAN";
BA_ "VersionYear" 2018;
BA_ "VersionMonth" 3;
BA_ "NetworkSpeed" 1;
BA_ "CMDB_Version" "v13.01";
BA_ "StarNetworkGwType" 6;
BA_ "VersionNumber" 9;
BA_ "DBName" "MS1_CAN";
BA_ "NmStationAddress" BU_ Generic_BCM 1;
BA_ "PowerType" BU_ Generic_BCM 2;
BA_ "NodeStartUpTime" BU_ Generic_BCM 1000;
BA_ "NmNode" BU_ Generic_BCM 1;
BA_ "NmStationAddress" BU_ TRM 84;
BA_ "NmNode" BU_ TRM 1;
BA_ "PowerType" BU_ TRM 2;
BA_ "NodeStartUpTime" BU_ TRM 1000;
BA_ "NodeWakeUpTime" BU_ TRM 20;
BA_ "NmStationAddress" BU_ GWM 30;
BA_ "NmNode" BU_ GWM 1;
BA_ "PowerType" BU_ GWM 2;
BA_ "NodeStartUpTime" BU_ GWM 100;
BA_ "Terminator" BU_ GWM 1;
BA_ "GatewayECU" BU_ GWM 1;
BA_ "NosPackage" BU_ GWM 4;
BA_ "NmStationAddress" BU_ APIM 98;
BA_ "NmNode" BU_ APIM 1;
BA_ "PowerType" BU_ APIM 2;
BA_ "NodeStartUpTime" BU_ APIM 1000;
BA_ "NodeWakeUpTime" BU_ APIM 200;
BA_ "NosPackage" BU_ APIM 4;
BA_ "NmStationAddress" BU_ SODL 106;
BA_ "NmStationAddress" BU_ RTM 59;
BA_ "NmNode" BU_ RTM 1;
BA_ "PowerType" BU_ RTM 2;
BA_ "NodeStartUpTime" BU_ RTM 1000;
BA_ "NodeWakeUpTime" BU_ RTM 25;
BA_ "NmStationAddress" BU_ FCIM 93;
BA_ "NmNode" BU_ FCIM 1;
BA_ "PowerType" BU_ FCIM 2;
BA_ "NodeStartUpTime" BU_ FCIM 1000;
BA_ "NodeWakeUpTime" BU_ FCIM 50;
BA_ "Terminator" BU_ FCIM 1;
BA_ "NosPackage" BU_ FCIM 4;
BA_ "NmStationAddress" BU_ PDM 5;
BA_ "NmNode" BU_ PDM 1;
BA_ "NetworkInitializationUsed" BU_ PDM 1;
BA_ "PowerType" BU_ PDM 2;
BA_ "NodeStartUpTime" BU_ PDM 1000;
BA_ "NodeWakeUpTime" BU_ PDM 50;
BA_ "NmStationAddress" BU_ SCMH 44;
BA_ "NodeStartUpTime" BU_ SCMH 1000;
BA_ "NmStationAddress" BU_ SCMG 43;
BA_ "NodeStartUpTime" BU_ SCMG 1000;
BA_ "NmStationAddress" BU_ HSWM 86;
BA_ "NmStationAddress" BU_ GPSM 108;
BA_ "NmNode" BU_ GPSM 1;
BA_ "PowerType" BU_ GPSM 2;
BA_ "NodeStartUpTime" BU_ GPSM 1000;
BA_ "NodeWakeUpTime" BU_ GPSM 200;
BA_ "NmStationAddress" BU_ RSM 103;
BA_ "NmNode" BU_ RSM 1;
BA_ "PowerType" BU_ RSM 2;
BA_ "NodeStartUpTime" BU_ RSM 4500;
BA_ "NodeWakeUpTime" BU_ RSM 20;
BA_ "NmStationAddress" BU_ SODR 107;
BA_ "NmStationAddress" BU_ DDM 4;
BA_ "NmNode" BU_ DDM 1;
BA_ "NetworkInitializationUsed" BU_ DDM 1;
BA_ "PowerType" BU_ DDM 2;
BA_ "NodeStartUpTime" BU_ DDM 1000;
BA_ "NodeWakeUpTime" BU_ DDM 50;
BA_ "NmStationAddress" BU_ RBM 69;
BA_ "NmNode" BU_ RBM 1;
BA_ "NetworkInitializationUsed" BU_ RBM 1;
BA_ "PowerType" BU_ RBM 2;
BA_ "NodeStartUpTime" BU_ RBM 500;
BA_ "NodeWakeUpTime" BU_ RBM 50;
BA_ "NmStationAddress" BU_ DSM 11;
BA_ "NmNode" BU_ DSM 1;
BA_ "NetworkInitializationUsed" BU_ DSM 1;
BA_ "PowerType" BU_ DSM 2;
BA_ "NodeStartUpTime" BU_ DSM 100;
BA_ "NodeWakeUpTime" BU_ DSM 100;
BA_ "NmStationAddress" BU_ SCME 39;
BA_ "NmNode" BU_ SCME 1;
BA_ "NetworkInitializationUsed" BU_ SCME 1;
BA_ "PowerType" BU_ SCME 2;
BA_ "NodeStartUpTime" BU_ SCME 1000;
BA_ "NodeWakeUpTime" BU_ SCME 20;
BA_ "NetworkInitializationUsed" BU_ TSTR 1;
BA_ "PowerType" BU_ TSTR 2;
BA_ "NodeStartUpTime" BU_ TSTR 1000;
BA_ "FrameGatewayId" BO_ 945 945;
BA_ "FrameGatewayHS1" BO_ 945 945;
BA_ "FrameGatewayNetwork" BO_ 945 "HS1_CAN";
BA_ "GenMsgSendType" BO_ 1079 5;
BA_ "GenMsgCycleTime" BO_ 1079 1000;
BA_ "GenMsgSendType" BO_ 932 0;
BA_ "GenMsgCycleTime" BO_ 932 50;
BA_ "GenMsgSendType" BO_ 1075 5;
BA_ "GenMsgCycleTime" BO_ 1075 1000;
BA_ "NetworkInitialization" BO_ 1075 1;
BA_ "GenMsgSendType" BO_ 933 0;
BA_ "GenMsgCycleTime" BO_ 933 50;
BA_ "GenMsgCycleTime" BO_ 1098 50;
BA_ "GenMsgSendType" BO_ 1098 0;
BA_ "FrameGatewayNetwork" BO_ 1045 "HS2_CAN";
BA_ "FrameGatewayId" BO_ 1045 1045;
BA_ "FrameGatewayHS2" BO_ 1045 1045;
BA_ "GenMsgSendType" BO_ 1189 5;
BA_ "GenMsgCycleTime" BO_ 1189 1000;
BA_ "NetworkInitialization" BO_ 941 1;
BA_ "GenMsgSendType" BO_ 941 0;
BA_ "GenMsgCycleTime" BO_ 941 50;
BA_ "NetworkInitialization" BO_ 940 1;
BA_ "GenMsgSendType" BO_ 940 0;
BA_ "GenMsgCycleTime" BO_ 940 50;
BA_ "NetworkInitialization" BO_ 1095 1;
BA_ "FrameGatewayNetwork" BO_ 1095 "HS1_CAN";
BA_ "FrameGatewayId" BO_ 1095 1095;
BA_ "FrameGatewayHS1" BO_ 1095 1095;
BA_ "FrameGatewayNetwork" BO_ 948 "HS1_CAN";
BA_ "FrameGatewayId" BO_ 948 948;
BA_ "FrameGatewayHS1" BO_ 948 948;
BA_ "FrameGatewayNetwork" BO_ 132 "HS1_CAN";
BA_ "FrameGatewayId" BO_ 132 132;
BA_ "FrameGatewayHS1" BO_ 132 132;
BA_ "GenMsgILSupport" BO_ 1378 0;
BA_ "NmMessage" BO_ 1378 1;
BA_ "GenMsgSendType" BO_ 1378 1;
BA_ "GenMsgSendType" BO_ 839 0;
BA_ "GenMsgCycleTime" BO_ 839 100;
BA_ "GenMsgSendType" BO_ 850 0;
BA_ "GenMsgCycleTime" BO_ 850 500;
BA_ "GenMsgSendType" BO_ 849 0;
BA_ "GenMsgCycleTime" BO_ 849 500;
BA_ "FrameGatewayNetwork" BO_ 846 "HS3_CAN";
BA_ "FrameGatewayId" BO_ 846 846;
BA_ "FrameGatewayHS3" BO_ 846 846;
BA_ "GenMsgSendType" BO_ 845 5;
BA_ "GenMsgCycleTime" BO_ 845 1000;
BA_ "GenMsgSendType" BO_ 844 5;
BA_ "GenMsgCycleTime" BO_ 844 1000;
BA_ "GenMsgSendType" BO_ 843 0;
BA_ "GenMsgCycleTime" BO_ 843 500;
BA_ "GenMsgSendType" BO_ 842 0;
BA_ "GenMsgCycleTime" BO_ 842 500;
BA_ "GenMsgILSupport" BO_ 1994 0;
BA_ "DiagResponse" BO_ 1994 1;
BA_ "GenMsgSendType" BO_ 1994 1;
BA_ "GenMsgDelayTime" BO_ 1994 0;
BA_ "GenMsgILSupport" BO_ 1986 0;
BA_ "DiagRequest" BO_ 1986 1;
BA_ "GenMsgSendType" BO_ 1986 1;
BA_ "GenMsgDelayTime" BO_ 1986 0;
BA_ "GenMsgILSupport" BO_ 1383 0;
BA_ "NmMessage" BO_ 1383 1;
BA_ "GenMsgSendType" BO_ 1383 1;
BA_ "GenMsgSendType" BO_ 958 5;
BA_ "GenMsgCycleTime" BO_ 958 100;
BA_ "FrameGatewayNetwork" BO_ 827 "HS2_CAN";
BA_ "GenMsgStartDelayTime" BO_ 827 100;
BA_ "FrameGatewayId" BO_ 827 827;
BA_ "FrameGatewayHS2" BO_ 827 827;
BA_ "GenMsgSendType" BO_ 902 5;
BA_ "GenMsgCycleTime" BO_ 902 1000;
BA_ "NetworkInitialization" BO_ 765 1;
BA_ "GenMsgSendType" BO_ 765 5;
BA_ "GenMsgCycleTime" BO_ 765 1000;
BA_ "GenMsgSendType" BO_ 672 5;
BA_ "GenMsgCycleTime" BO_ 672 1000;
BA_ "GenMsgDelayTime" BO_ 672 5;
BA_ "GenMsgStartDelayTime" BO_ 672 200;
BA_ "TpTxIndex" BO_ 710 26;
BA_ "GenMsgSendType" BO_ 556 5;
BA_ "GenMsgCycleTime" BO_ 556 1000;
BA_ "U_V36X_MY18_5_Diesel_Rx" SG_ 945 KeyOffMde_D_Actl 1;
BA_ "U_V36X_MY19_5_Diesel_Rx" SG_ 945 KeyOffMde_D_Actl 1;
BA_ "U_V363E_N_MY19_5_20_Gas_Rx" SG_ 945 KeyOffMde_D_Actl 1;
BA_ "U_V363E_N_MY19_5_20_Diesel_Rx" SG_ 945 KeyOffMde_D_Actl 1;
BA_ "U_V36X_MY18_5_Gas_Rx" SG_ 945 KeyOffMde_D_Actl 1;
BA_ "U_V36X_MY18_5_Hev_Rx" SG_ 945 KeyOffMde_D_Actl 1;
BA_ "GenSigStartValue" SG_ 1079 BattULo2_Te_Actl 127;
BA_ "U_P558_MY17_Diesel_Tx" SG_ 932 BttLeftIndex2_No_Actl 1;
BA_ "U_P558_MY17_Gas_Tx" SG_ 932 BttLeftIndex2_No_Actl 1;
BA_ "U_P558_MY17_Diesel_Rx" SG_ 932 BttLeftIndex2_No_Actl 1;
BA_ "U_P558_MY17_Gas_Rx" SG_ 932 BttLeftIndex2_No_Actl 1;
BA_ "U_P558_MY17_Diesel_Tx" SG_ 932 BttLeftIndex1_No_Actl 1;
BA_ "U_P558_MY17_Gas_Tx" SG_ 932 BttLeftIndex1_No_Actl 1;
BA_ "U_P558_MY17_Diesel_Rx" SG_ 932 BttLeftIndex1_No_Actl 1;
BA_ "U_P558_MY17_Gas_Rx" SG_ 932 BttLeftIndex1_No_Actl 1;
BA_ "U_P558_MY17_Diesel_Tx" SG_ 932 BttLeftData2_No_Actl 1;
BA_ "U_P558_MY17_Gas_Tx" SG_ 932 BttLeftData2_No_Actl 1;
BA_ "U_P558_MY17_Diesel_Rx" SG_ 932 BttLeftData2_No_Actl 1;
BA_ "U_P558_MY17_Gas_Rx" SG_ 932 BttLeftData2_No_Actl 1;
BA_ "U_P558_MY17_Diesel_Tx" SG_ 932 BttLeftData1_No_Actl 1;
BA_ "U_P558_MY17_Gas_Tx" SG_ 932 BttLeftData1_No_Actl 1;
BA_ "U_P558_MY17_Diesel_Rx" SG_ 932 BttLeftData1_No_Actl 1;
BA_ "U_P558_MY17_Gas_Rx" SG_ 932 BttLeftData1_No_Actl 1;
BA_ "U_P558_MY17_Diesel_Tx" SG_ 932 BttLeft_T_Actl 1;
BA_ "U_P558_MY17_Gas_Tx" SG_ 932 BttLeft_T_Actl 1;
BA_ "U_P558_MY17_Diesel_Rx" SG_ 932 BttLeft_T_Actl 1;
BA_ "U_P558_MY17_Gas_Rx" SG_ 932 BttLeft_T_Actl 1;
BA_ "U_V36X_MY19_5_Diesel_Rx" SG_ 1075 SelDrvMdePt_D_Rq_UB 1;
BA_ "U_V36X_MY18_5_Diesel_Rx" SG_ 1075 SelDrvMdePt_D_Rq_UB 1;
BA_ "U_V36X_MY19_5_Diesel_Rx" SG_ 1075 SelDrvMdePt_D_Rq 1;
BA_ "U_V36X_MY18_5_Diesel_Rx" SG_ 1075 SelDrvMdePt_D_Rq 1;
BA_ "GenSigSendType" SG_ 1075 SelDrvMdePt_D_Rq 3;
BA_ "U_P558_MY17_Diesel_Rx" SG_ 1075 PrkAidSnsRrCrnr_D_Stat_UB 1;
BA_ "U_P558_MY17_Gas_Rx" SG_ 1075 PrkAidSnsRrCrnr_D_Stat_UB 1;
BA_ "GenSigSendType" SG_ 1075 PrkAidSnsRrCrnr_D_Stat 3;
BA_ "CrossOver_InfoCAN" SG_ 1075 PrkAidSnsRrCrnr_D_Stat 1;
BA_ "U_P558_MY17_Diesel_Rx" SG_ 1075 PrkAidSnsRrCrnr_D_Stat 1;
BA_ "U_P558_MY17_Gas_Rx" SG_ 1075 PrkAidSnsRrCrnr_D_Stat 1;
BA_ "U_P558_MY17_Diesel_Rx" SG_ 1075 PrkAidSnsRrCntr_D_Stat_UB 1;
BA_ "U_P558_MY17_Gas_Rx" SG_ 1075 PrkAidSnsRrCntr_D_Stat_UB 1;
BA_ "GenSigSendType" SG_ 1075 PrkAidSnsRrCntr_D_Stat 3;
BA_ "CrossOver_InfoCAN" SG_ 1075 PrkAidSnsRrCntr_D_Stat 1;
BA_ "U_P558_MY17_Diesel_Rx" SG_ 1075 PrkAidSnsRrCntr_D_Stat 1;
BA_ "U_P558_MY17_Gas_Rx" SG_ 1075 PrkAidSnsRrCntr_D_Stat 1;
BA_ "U_P558_MY17_Diesel_Rx" SG_ 1075 PrkAidSnsRlCrnr_D_Stat_UB 1;
BA_ "U_P558_MY17_Gas_Rx" SG_ 1075 PrkAidSnsRlCrnr_D_Stat_UB 1;
BA_ "GenSigSendType" SG_ 1075 PrkAidSnsRlCrnr_D_Stat 3;
BA_ "CrossOver_InfoCAN" SG_ 1075 PrkAidSnsRlCrnr_D_Stat 1;
BA_ "U_P558_MY17_Diesel_Rx" SG_ 1075 PrkAidSnsRlCrnr_D_Stat 1;
BA_ "U_P558_MY17_Gas_Rx" SG_ 1075 PrkAidSnsRlCrnr_D_Stat 1;
BA_ "U_P558_MY17_Diesel_Rx" SG_ 1075 PrkAidSnsRlCntr_D_Stat_UB 1;
BA_ "U_P558_MY17_Gas_Rx" SG_ 1075 PrkAidSnsRlCntr_D_Stat_UB 1;
BA_ "GenSigSendType" SG_ 1075 PrkAidSnsRlCntr_D_Stat 3;
BA_ "CrossOver_InfoCAN" SG_ 1075 PrkAidSnsRlCntr_D_Stat 1;
BA_ "U_P558_MY17_Diesel_Rx" SG_ 1075 PrkAidSnsRlCntr_D_Stat 1;
BA_ "U_P558_MY17_Gas_Rx" SG_ 1075 PrkAidSnsRlCntr_D_Stat 1;
BA_ "U_P558_MY17_Diesel_Rx" SG_ 1075 Btt_L_Actl_UB 1;
BA_ "U_P558_MY17_Gas_Rx" SG_ 1075 Btt_L_Actl_UB 1;
BA_ "GenSigStartValue" SG_ 1075 Btt_L_Actl 126;
BA_ "U_P558_MY17_Diesel_Rx" SG_ 1075 Btt_L_Actl 1;
BA_ "U_P558_MY17_Gas_Rx" SG_ 1075 Btt_L_Actl 1;
BA_ "U_P558_MY17_Diesel_Rx" SG_ 1075 BttOn_B_Rq_UB 1;
BA_ "U_P558_MY17_Gas_Rx" SG_ 1075 BttOn_B_Rq_UB 1;
BA_ "GenSigSendType" SG_ 1075 BttOn_B_Rq 3;
BA_ "U_P558_MY17_Diesel_Rx" SG_ 1075 BttOn_B_Rq 1;
BA_ "U_P558_MY17_Gas_Rx" SG_ 1075 BttOn_B_Rq 1;
BA_ "U_P558_MY17_Diesel_Tx" SG_ 933 BttRightIndex2_No_Actl 1;
BA_ "U_P558_MY17_Gas_Tx" SG_ 933 BttRightIndex2_No_Actl 1;
BA_ "U_P558_MY17_Diesel_Rx" SG_ 933 BttRightIndex2_No_Actl 1;
BA_ "U_P558_MY17_Gas_Rx" SG_ 933 BttRightIndex2_No_Actl 1;
BA_ "U_P558_MY17_Diesel_Tx" SG_ 933 BttRightIndex1_No_Actl 1;
BA_ "U_P558_MY17_Gas_Tx" SG_ 933 BttRightIndex1_No_Actl 1;
BA_ "U_P558_MY17_Diesel_Rx" SG_ 933 BttRightIndex1_No_Actl 1;
BA_ "U_P558_MY17_Gas_Rx" SG_ 933 BttRightIndex1_No_Actl 1;
BA_ "U_P558_MY17_Diesel_Tx" SG_ 933 BttRightData2_No_Actl 1;
BA_ "U_P558_MY17_Gas_Tx" SG_ 933 BttRightData2_No_Actl 1;
BA_ "U_P558_MY17_Diesel_Rx" SG_ 933 BttRightData2_No_Actl 1;
BA_ "U_P558_MY17_Gas_Rx" SG_ 933 BttRightData2_No_Actl 1;
BA_ "U_P558_MY17_Diesel_Tx" SG_ 933 BttRightData1_No_Actl 1;
BA_ "U_P558_MY17_Gas_Tx" SG_ 933 BttRightData1_No_Actl 1;
BA_ "U_P558_MY17_Diesel_Rx" SG_ 933 BttRightData1_No_Actl 1;
BA_ "U_P558_MY17_Gas_Rx" SG_ 933 BttRightData1_No_Actl 1;
BA_ "U_P558_MY17_Diesel_Tx" SG_ 933 BttRight_T_Actl 1;
BA_ "U_P558_MY17_Gas_Tx" SG_ 933 BttRight_T_Actl 1;
BA_ "U_P558_MY17_Diesel_Rx" SG_ 933 BttRight_T_Actl 1;
BA_ "U_P558_MY17_Gas_Rx" SG_ 933 BttRight_T_Actl 1;
BA_ "U_P552_MY17_Gas_Tx" SG_ 1098 TrlrAidSwtch_D_RqDrv 1;
BA_ "U_P552_MY17_Gas_Tx" SG_ 1098 TrlrAidCtl_U_RqDrv 1;
BA_ "GenSigStartValue" SG_ 1098 TrlrAidCtl_U_RqDrv 4094;
BA_ "CrossOver_InfoCAN" SG_ 1045 VehVActlBrk_No_Cs 1;
BA_ "U_P552_MY15_Gas_Rx" SG_ 1045 VehVActlBrk_No_Cs 1;
BA_ "CrossOver_InfoCAN" SG_ 1045 Veh_V_ActlBrk 1;
BA_ "U_P552_MY15_Gas_Rx" SG_ 1045 Veh_V_ActlBrk 1;
BA_ "CrossOver_InfoCAN" SG_ 1045 VehVActlBrk_No_Cnt 1;
BA_ "U_P552_MY15_Gas_Rx" SG_ 1045 VehVActlBrk_No_Cnt 1;
BA_ "CrossOver_InfoCAN" SG_ 1045 VehVActlBrk_D_Qf 1;
BA_ "U_P552_MY15_Gas_Rx" SG_ 1045 VehVActlBrk_D_Qf 1;
BA_ "GenSigSendType" SG_ 1189 Running_Board_Stat 3;
BA_ "U_P552_MY15_Gas_Tx" SG_ 1189 Running_Board_Stat 1;
BA_ "GenSigStartValue" SG_ 941 CtaTrgtRightY_V_Actl 32767;
BA_ "U_P558_MY17_Diesel_Tx" SG_ 941 CtaTrgtRightY_V_Actl 1;
BA_ "U_P558_MY17_Gas_Tx" SG_ 941 CtaTrgtRightY_V_Actl 1;
BA_ "U_P558_MY17_Diesel_Rx" SG_ 941 CtaTrgtRightY_V_Actl 1;
BA_ "U_P558_MY17_Gas_Rx" SG_ 941 CtaTrgtRightY_V_Actl 1;
BA_ "GenSigStartValue" SG_ 941 CtaTrgtRightY_L_Actl 32767;
BA_ "U_P558_MY17_Diesel_Tx" SG_ 941 CtaTrgtRightY_L_Actl 1;
BA_ "U_P558_MY17_Gas_Tx" SG_ 941 CtaTrgtRightY_L_Actl 1;
BA_ "U_P558_MY17_Diesel_Rx" SG_ 941 CtaTrgtRightY_L_Actl 1;
BA_ "U_P558_MY17_Gas_Rx" SG_ 941 CtaTrgtRightY_L_Actl 1;
BA_ "GenSigStartValue" SG_ 941 CtaTrgtRightX_V_Actl 32767;
BA_ "U_P558_MY17_Diesel_Tx" SG_ 941 CtaTrgtRightX_V_Actl 1;
BA_ "U_P558_MY17_Gas_Tx" SG_ 941 CtaTrgtRightX_V_Actl 1;
BA_ "U_P558_MY17_Diesel_Rx" SG_ 941 CtaTrgtRightX_V_Actl 1;
BA_ "U_P558_MY17_Gas_Rx" SG_ 941 CtaTrgtRightX_V_Actl 1;
BA_ "GenSigStartValue" SG_ 941 CtaTrgtRightX_L_Actl 56174;
BA_ "U_P558_MY17_Diesel_Tx" SG_ 941 CtaTrgtRightX_L_Actl 1;
BA_ "U_P558_MY17_Gas_Tx" SG_ 941 CtaTrgtRightX_L_Actl 1;
BA_ "U_P558_MY17_Diesel_Rx" SG_ 941 CtaTrgtRightX_L_Actl 1;
BA_ "U_P558_MY17_Gas_Rx" SG_ 941 CtaTrgtRightX_L_Actl 1;
BA_ "GenSigStartValue" SG_ 940 CtaTrgtLeftY_V_Actl 32767;
BA_ "U_P558_MY17_Diesel_Tx" SG_ 940 CtaTrgtLeftY_V_Actl 1;
BA_ "U_P558_MY17_Gas_Tx" SG_ 940 CtaTrgtLeftY_V_Actl 1;
BA_ "GenSigStartValue" SG_ 940 CtaTrgtLeftY_L_Actl 32767;
BA_ "U_P558_MY17_Diesel_Tx" SG_ 940 CtaTrgtLeftY_L_Actl 1;
BA_ "U_P558_MY17_Gas_Tx" SG_ 940 CtaTrgtLeftY_L_Actl 1;
BA_ "GenSigStartValue" SG_ 940 CtaTrgtLeftX_V_Actl 32767;
BA_ "U_P558_MY17_Diesel_Tx" SG_ 940 CtaTrgtLeftX_V_Actl 1;
BA_ "U_P558_MY17_Gas_Tx" SG_ 940 CtaTrgtLeftX_V_Actl 1;
BA_ "GenSigStartValue" SG_ 940 CtaTrgtLeftX_L_Actl 56174;
BA_ "U_P558_MY17_Diesel_Tx" SG_ 940 CtaTrgtLeftX_L_Actl 1;
BA_ "U_P558_MY17_Gas_Tx" SG_ 940 CtaTrgtLeftX_L_Actl 1;
BA_ "U_CD43_MY17_Gas_Rx" SG_ 1095 VehLck_D_Dsply 1;
BA_ "WakeupSignal" SG_ 1095 HeadLghtOn_D_Rq 1;
BA_ "GenSigStartValue" SG_ 1095 HeadLghtOn_D_Rq 1;
BA_ "U_P558_MY17_Gas_Rx" SG_ 1095 HeadLghtOn_D_Rq 1;
BA_ "U_P558_MY17_Diesel_Rx" SG_ 1095 HeadLghtOn_D_Rq 1;
BA_ "U_CD4_MY13_Diesel_Rx" SG_ 1095 RstrtSetting_T_Actl 1;
BA_ "U_CD4_MY13_Gas_Rx" SG_ 1095 RstrtSetting_T_Actl 1;
BA_ "U_CD42_MY14_Diesel_Rx" SG_ 1095 RstrtSetting_T_Actl 1;
BA_ "U_CD42_MY14_Gas_Rx" SG_ 1095 RstrtSetting_T_Actl 1;
BA_ "U_P552_MY15_Gas_Rx" SG_ 1095 RstrtSetting_T_Actl 1;
BA_ "U_S550_MY15_Gas_Rx" SG_ 1095 RstrtSetting_T_Actl 1;
BA_ "U_C489_MY14_Gas_Rx" SG_ 1095 RstrtSetting_T_Actl 1;
BA_ "U_U502_MY15_Gas_Rx" SG_ 1095 RstrtSetting_T_Actl 1;
BA_ "U_CD43_MY16_Gas_Rx" SG_ 1095 RstrtSetting_T_Actl 1;
BA_ "U_CD4_MY14_Diesel_Rx" SG_ 1095 RstrtSetting_T_Actl 1;
BA_ "U_CD4_MY14_Gas_Rx" SG_ 1095 RstrtSetting_T_Actl 1;
BA_ "U_CD4_MY14_Hev_Rx" SG_ 1095 RstrtSetting_T_Actl 1;
BA_ "U_CD4_MY14_Phev_Rx" SG_ 1095 RstrtSetting_T_Actl 1;
BA_ "U_CD4_MY13_Diesel_Rx" SG_ 1095 Rstrt_T_Actl 1;
BA_ "U_CD4_MY13_Gas_Rx" SG_ 1095 Rstrt_T_Actl 1;
BA_ "U_CD42_MY14_Diesel_Rx" SG_ 1095 Rstrt_T_Actl 1;
BA_ "U_CD42_MY14_Gas_Rx" SG_ 1095 Rstrt_T_Actl 1;
BA_ "U_P552_MY15_Gas_Rx" SG_ 1095 Rstrt_T_Actl 1;
BA_ "U_S550_MY15_Gas_Rx" SG_ 1095 Rstrt_T_Actl 1;
BA_ "U_C489_MY14_Gas_Rx" SG_ 1095 Rstrt_T_Actl 1;
BA_ "U_U502_MY15_Gas_Rx" SG_ 1095 Rstrt_T_Actl 1;
BA_ "U_CD43_MY16_Gas_Rx" SG_ 1095 Rstrt_T_Actl 1;
BA_ "U_CD4_MY14_Diesel_Rx" SG_ 1095 Rstrt_T_Actl 1;
BA_ "U_CD4_MY14_Gas_Rx" SG_ 1095 Rstrt_T_Actl 1;
BA_ "U_CD4_MY14_Hev_Rx" SG_ 1095 Rstrt_T_Actl 1;
BA_ "U_CD4_MY14_Phev_Rx" SG_ 1095 Rstrt_T_Actl 1;
BA_ "CrossOver_InfoCAN" SG_ 948 Tire_Press_ILR_Stat 1;
BA_ "U_CD4_MY13_Diesel_Rx" SG_ 948 Tire_Press_ILR_Stat 1;
BA_ "U_CD4_MY13_Gas_Rx" SG_ 948 Tire_Press_ILR_Stat 1;
BA_ "U_CD4_MY13_Hev_Rx" SG_ 948 Tire_Press_ILR_Stat 1;
BA_ "U_CD4_MY13_Phev_Rx" SG_ 948 Tire_Press_ILR_Stat 1;
BA_ "U_CD42_MY14_Diesel_Rx" SG_ 948 Tire_Press_ILR_Stat 1;
BA_ "U_CD42_MY14_Gas_Rx" SG_ 948 Tire_Press_ILR_Stat 1;
BA_ "U_P552_MY15_Gas_Rx" SG_ 948 Tire_Press_ILR_Stat 1;
BA_ "U_S550_MY15_Gas_Rx" SG_ 948 Tire_Press_ILR_Stat 1;
BA_ "U_C489_MY14_Gas_Rx" SG_ 948 Tire_Press_ILR_Stat 1;
BA_ "U_U502_MY15_Gas_Rx" SG_ 948 Tire_Press_ILR_Stat 1;
BA_ "U_UP375_MY15_Gas_Rx" SG_ 948 Tire_Press_ILR_Stat 1;
BA_ "U_UP375_MY15_Diesel_Rx" SG_ 948 Tire_Press_ILR_Stat 1;
BA_ "U_CD43_MY16_Gas_Rx" SG_ 948 Tire_Press_ILR_Stat 1;
BA_ "CrossOver_InfoCAN" SG_ 948 Tire_Press_IRR_Stat 1;
BA_ "U_CD4_MY13_Diesel_Rx" SG_ 948 Tire_Press_IRR_Stat 1;
BA_ "U_CD4_MY13_Gas_Rx" SG_ 948 Tire_Press_IRR_Stat 1;
BA_ "U_CD4_MY13_Hev_Rx" SG_ 948 Tire_Press_IRR_Stat 1;
BA_ "U_CD4_MY13_Phev_Rx" SG_ 948 Tire_Press_IRR_Stat 1;
BA_ "U_CD42_MY14_Diesel_Rx" SG_ 948 Tire_Press_IRR_Stat 1;
BA_ "U_CD42_MY14_Gas_Rx" SG_ 948 Tire_Press_IRR_Stat 1;
BA_ "U_P552_MY15_Gas_Rx" SG_ 948 Tire_Press_IRR_Stat 1;
BA_ "U_S550_MY15_Gas_Rx" SG_ 948 Tire_Press_IRR_Stat 1;
BA_ "U_C489_MY14_Gas_Rx" SG_ 948 Tire_Press_IRR_Stat 1;
BA_ "U_U502_MY15_Gas_Rx" SG_ 948 Tire_Press_IRR_Stat 1;
BA_ "U_UP375_MY15_Gas_Rx" SG_ 948 Tire_Press_IRR_Stat 1;
BA_ "U_UP375_MY15_Diesel_Rx" SG_ 948 Tire_Press_IRR_Stat 1;
BA_ "U_CD43_MY16_Gas_Rx" SG_ 948 Tire_Press_IRR_Stat 1;
BA_ "CrossOver_InfoCAN" SG_ 948 Tire_Press_LR_OLR_Stat 1;
BA_ "U_CD4_MY13_Diesel_Rx" SG_ 948 Tire_Press_LR_OLR_Stat 1;
BA_ "U_CD4_MY13_Gas_Rx" SG_ 948 Tire_Press_LR_OLR_Stat 1;
BA_ "U_CD4_MY13_Hev_Rx" SG_ 948 Tire_Press_LR_OLR_Stat 1;
BA_ "U_CD4_MY13_Phev_Rx" SG_ 948 Tire_Press_LR_OLR_Stat 1;
BA_ "U_CD42_MY14_Diesel_Rx" SG_ 948 Tire_Press_LR_OLR_Stat 1;
BA_ "U_CD42_MY14_Gas_Rx" SG_ 948 Tire_Press_LR_OLR_Stat 1;
BA_ "U_P552_MY15_Gas_Rx" SG_ 948 Tire_Press_LR_OLR_Stat 1;
BA_ "U_S550_MY15_Gas_Rx" SG_ 948 Tire_Press_LR_OLR_Stat 1;
BA_ "U_C489_MY14_Gas_Rx" SG_ 948 Tire_Press_LR_OLR_Stat 1;
BA_ "U_U502_MY15_Gas_Rx" SG_ 948 Tire_Press_LR_OLR_Stat 1;
BA_ "U_UP375_MY15_Gas_Rx" SG_ 948 Tire_Press_LR_OLR_Stat 1;
BA_ "U_UP375_MY15_Diesel_Rx" SG_ 948 Tire_Press_LR_OLR_Stat 1;
BA_ "U_CD43_MY16_Gas_Rx" SG_ 948 Tire_Press_LR_OLR_Stat 1;
BA_ "CrossOver_InfoCAN" SG_ 948 Tire_Press_RR_ORR_Stat 1;
BA_ "U_CD4_MY13_Diesel_Rx" SG_ 948 Tire_Press_RR_ORR_Stat 1;
BA_ "U_CD4_MY13_Gas_Rx" SG_ 948 Tire_Press_RR_ORR_Stat 1;
BA_ "U_CD4_MY13_Hev_Rx" SG_ 948 Tire_Press_RR_ORR_Stat 1;
BA_ "U_CD4_MY13_Phev_Rx" SG_ 948 Tire_Press_RR_ORR_Stat 1;
BA_ "U_CD42_MY14_Diesel_Rx" SG_ 948 Tire_Press_RR_ORR_Stat 1;
BA_ "U_CD42_MY14_Gas_Rx" SG_ 948 Tire_Press_RR_ORR_Stat 1;
BA_ "U_P552_MY15_Gas_Rx" SG_ 948 Tire_Press_RR_ORR_Stat 1;
BA_ "U_S550_MY15_Gas_Rx" SG_ 948 Tire_Press_RR_ORR_Stat 1;
BA_ "U_C489_MY14_Gas_Rx" SG_ 948 Tire_Press_RR_ORR_Stat 1;
BA_ "U_U502_MY15_Gas_Rx" SG_ 948 Tire_Press_RR_ORR_Stat 1;
BA_ "U_UP375_MY15_Gas_Rx" SG_ 948 Tire_Press_RR_ORR_Stat 1;
BA_ "U_UP375_MY15_Diesel_Rx" SG_ 948 Tire_Press_RR_ORR_Stat 1;
BA_ "U_CD43_MY16_Gas_Rx" SG_ 948 Tire_Press_RR_ORR_Stat 1;
BA_ "CrossOver_InfoCAN" SG_ 948 Tire_Press_RF_Stat 1;
BA_ "U_CD4_MY13_Diesel_Rx" SG_ 948 Tire_Press_RF_Stat 1;
BA_ "U_CD4_MY13_Gas_Rx" SG_ 948 Tire_Press_RF_Stat 1;
BA_ "U_CD4_MY13_Hev_Rx" SG_ 948 Tire_Press_RF_Stat 1;
BA_ "U_CD4_MY13_Phev_Rx" SG_ 948 Tire_Press_RF_Stat 1;
BA_ "U_CD42_MY14_Diesel_Rx" SG_ 948 Tire_Press_RF_Stat 1;
BA_ "U_CD42_MY14_Gas_Rx" SG_ 948 Tire_Press_RF_Stat 1;
BA_ "U_P552_MY15_Gas_Rx" SG_ 948 Tire_Press_RF_Stat 1;
BA_ "U_S550_MY15_Gas_Rx" SG_ 948 Tire_Press_RF_Stat 1;
BA_ "U_C489_MY14_Gas_Rx" SG_ 948 Tire_Press_RF_Stat 1;
BA_ "U_U502_MY15_Gas_Rx" SG_ 948 Tire_Press_RF_Stat 1;
BA_ "U_UP375_MY15_Gas_Rx" SG_ 948 Tire_Press_RF_Stat 1;
BA_ "U_UP375_MY15_Diesel_Rx" SG_ 948 Tire_Press_RF_Stat 1;
BA_ "U_CD43_MY16_Gas_Rx" SG_ 948 Tire_Press_RF_Stat 1;
BA_ "CrossOver_InfoCAN" SG_ 948 Tire_Press_LF_Stat 1;
BA_ "U_CD4_MY13_Diesel_Rx" SG_ 948 Tire_Press_LF_Stat 1;
BA_ "U_CD4_MY13_Gas_Rx" SG_ 948 Tire_Press_LF_Stat 1;
BA_ "U_CD4_MY13_Hev_Rx" SG_ 948 Tire_Press_LF_Stat 1;
BA_ "U_CD4_MY13_Phev_Rx" SG_ 948 Tire_Press_LF_Stat 1;
BA_ "U_CD42_MY14_Diesel_Rx" SG_ 948 Tire_Press_LF_Stat 1;
BA_ "U_CD42_MY14_Gas_Rx" SG_ 948 Tire_Press_LF_Stat 1;
BA_ "U_P552_MY15_Gas_Rx" SG_ 948 Tire_Press_LF_Stat 1;
BA_ "U_S550_MY15_Gas_Rx" SG_ 948 Tire_Press_LF_Stat 1;
BA_ "U_C489_MY14_Gas_Rx" SG_ 948 Tire_Press_LF_Stat 1;
BA_ "U_U502_MY15_Gas_Rx" SG_ 948 Tire_Press_LF_Stat 1;
BA_ "U_UP375_MY15_Gas_Rx" SG_ 948 Tire_Press_LF_Stat 1;
BA_ "U_UP375_MY15_Diesel_Rx" SG_ 948 Tire_Press_LF_Stat 1;
BA_ "U_CD43_MY16_Gas_Rx" SG_ 948 Tire_Press_LF_Stat 1;
BA_ "CrossOver_InfoCAN" SG_ 948 Tire_Press_System_Stat 1;
BA_ "U_CD4_MY13_Diesel_Rx" SG_ 948 Tire_Press_System_Stat 1;
BA_ "U_CD4_MY13_Gas_Rx" SG_ 948 Tire_Press_System_Stat 1;
BA_ "U_CD4_MY13_Hev_Rx" SG_ 948 Tire_Press_System_Stat 1;
BA_ "U_CD4_MY13_Phev_Rx" SG_ 948 Tire_Press_System_Stat 1;
BA_ "U_CD42_MY14_Diesel_Rx" SG_ 948 Tire_Press_System_Stat 1;
BA_ "U_CD42_MY14_Gas_Rx" SG_ 948 Tire_Press_System_Stat 1;
BA_ "U_P552_MY15_Gas_Rx" SG_ 948 Tire_Press_System_Stat 1;
BA_ "U_S550_MY15_Gas_Rx" SG_ 948 Tire_Press_System_Stat 1;
BA_ "U_C489_MY14_Gas_Rx" SG_ 948 Tire_Press_System_Stat 1;
BA_ "U_U502_MY15_Gas_Rx" SG_ 948 Tire_Press_System_Stat 1;
BA_ "U_UP375_MY15_Gas_Rx" SG_ 948 Tire_Press_System_Stat 1;
BA_ "U_UP375_MY15_Diesel_Rx" SG_ 948 Tire_Press_System_Stat 1;
BA_ "U_CD43_MY16_Gas_Rx" SG_ 948 Tire_Press_System_Stat 1;
BA_ "CrossOver_InfoCAN" SG_ 948 Tire_Press_Telltale 1;
BA_ "U_CD4_MY13_Diesel_Rx" SG_ 948 Tire_Press_Telltale 1;
BA_ "U_CD4_MY13_Gas_Rx" SG_ 948 Tire_Press_Telltale 1;
BA_ "U_CD4_MY13_Hev_Rx" SG_ 948 Tire_Press_Telltale 1;
BA_ "U_CD4_MY13_Phev_Rx" SG_ 948 Tire_Press_Telltale 1;
BA_ "U_CD42_MY14_Diesel_Rx" SG_ 948 Tire_Press_Telltale 1;
BA_ "U_CD42_MY14_Gas_Rx" SG_ 948 Tire_Press_Telltale 1;
BA_ "U_P552_MY15_Gas_Rx" SG_ 948 Tire_Press_Telltale 1;
BA_ "U_S550_MY15_Gas_Rx" SG_ 948 Tire_Press_Telltale 1;
BA_ "U_C489_MY14_Gas_Rx" SG_ 948 Tire_Press_Telltale 1;
BA_ "U_U502_MY15_Gas_Rx" SG_ 948 Tire_Press_Telltale 1;
BA_ "U_UP375_MY15_Gas_Rx" SG_ 948 Tire_Press_Telltale 1;
BA_ "U_UP375_MY15_Diesel_Rx" SG_ 948 Tire_Press_Telltale 1;
BA_ "U_CD43_MY16_Gas_Rx" SG_ 948 Tire_Press_Telltale 1;
BA_ "CrossOver_InfoCAN" SG_ 948 TirePReset_D_Stat 1;
BA_ "U_CD4_MY13_Diesel_Rx" SG_ 948 TirePReset_D_Stat 1;
BA_ "U_CD4_MY13_Gas_Rx" SG_ 948 TirePReset_D_Stat 1;
BA_ "U_CD4_MY13_Hev_Rx" SG_ 948 TirePReset_D_Stat 1;
BA_ "U_CD4_MY13_Phev_Rx" SG_ 948 TirePReset_D_Stat 1;
BA_ "U_CD42_MY14_Diesel_Rx" SG_ 948 TirePReset_D_Stat 1;
BA_ "U_CD42_MY14_Gas_Rx" SG_ 948 TirePReset_D_Stat 1;
BA_ "U_P552_MY15_Gas_Rx" SG_ 948 TirePReset_D_Stat 1;
BA_ "U_S550_MY15_Gas_Rx" SG_ 948 TirePReset_D_Stat 1;
BA_ "U_C489_MY14_Gas_Rx" SG_ 948 TirePReset_D_Stat 1;
BA_ "U_U502_MY15_Gas_Rx" SG_ 948 TirePReset_D_Stat 1;
BA_ "U_UP375_MY15_Gas_Rx" SG_ 948 TirePReset_D_Stat 1;
BA_ "U_UP375_MY15_Diesel_Rx" SG_ 948 TirePReset_D_Stat 1;
BA_ "U_CD43_MY16_Gas_Rx" SG_ 948 TirePReset_D_Stat 1;
BA_ "CrossOver_InfoCAN" SG_ 132 GlblClkYr_No_Actl 1;
BA_ "U_P552_MY15_Gas_Rx" SG_ 132 GlblClkYr_No_Actl 1;
BA_ "CrossOver_InfoCAN" SG_ 132 GlblClkScnd_No_Actl 1;
BA_ "U_P552_MY15_Gas_Rx" SG_ 132 GlblClkScnd_No_Actl 1;
BA_ "CrossOver_InfoCAN" SG_ 132 GlblClkMnte_No_Actl 1;
BA_ "U_P552_MY15_Gas_Rx" SG_ 132 GlblClkMnte_No_Actl 1;
BA_ "CrossOver_InfoCAN" SG_ 132 GlblClkHr_No_Actl 1;
BA_ "U_P552_MY15_Gas_Rx" SG_ 132 GlblClkHr_No_Actl 1;
BA_ "CrossOver_InfoCAN" SG_ 132 GlblClkDay_No_Actl 1;
BA_ "U_P552_MY15_Gas_Rx" SG_ 132 GlblClkDay_No_Actl 1;
BA_ "GenSigSendType" SG_ 1378 APIM_Network_Mgmt 3;
BA_ "U_CD4_MY13_Diesel_Rx" SG_ 1378 APIM_Network_Mgmt 1;
BA_ "U_CD4_MY13_Gas_Rx" SG_ 1378 APIM_Network_Mgmt 1;
BA_ "U_CD4_MY13_Hev_Rx" SG_ 1378 APIM_Network_Mgmt 1;
BA_ "U_CD4_MY13_Phev_Rx" SG_ 1378 APIM_Network_Mgmt 1;
BA_ "U_CD42_MY14_Diesel_Rx" SG_ 1378 APIM_Network_Mgmt 1;
BA_ "U_CD42_MY14_Gas_Rx" SG_ 1378 APIM_Network_Mgmt 1;
BA_ "U_P552_MY15_Gas_Rx" SG_ 1378 APIM_Network_Mgmt 1;
BA_ "U_C489_MY14_Gas_Rx" SG_ 1378 APIM_Network_Mgmt 1;
BA_ "U_UP375_MY15_Gas_Rx" SG_ 1378 APIM_Network_Mgmt 1;
BA_ "U_UP375_MY15_Diesel_Rx" SG_ 1378 APIM_Network_Mgmt 1;
BA_ "U_S550_MY15_Gas_Rx" SG_ 1378 APIM_Network_Mgmt 1;
BA_ "U_U502_MY15_Gas_Rx" SG_ 1378 APIM_Network_Mgmt 1;
BA_ "U_CD43_MY16_Gas_Rx" SG_ 1378 APIM_Network_Mgmt 1;
BA_ "U_CD4_MY14_Diesel_Rx" SG_ 1378 APIM_Network_Mgmt 1;
BA_ "U_CD4_MY14_Gas_Rx" SG_ 1378 APIM_Network_Mgmt 1;
BA_ "U_CD4_MY14_Hev_Rx" SG_ 1378 APIM_Network_Mgmt 1;
BA_ "U_CD4_MY14_Phev_Rx" SG_ 1378 APIM_Network_Mgmt 1;
BA_ "U_CD4_MY13_Diesel_Tx" SG_ 1378 APIM_Network_Mgmt 1;
BA_ "U_CD4_MY13_Gas_Tx" SG_ 1378 APIM_Network_Mgmt 1;
BA_ "U_CD4_MY13_Hev_Tx" SG_ 1378 APIM_Network_Mgmt 1;
BA_ "U_CD4_MY13_Phev_Tx" SG_ 1378 APIM_Network_Mgmt 1;
BA_ "U_CD42_MY14_Diesel_Tx" SG_ 1378 APIM_Network_Mgmt 1;
BA_ "U_CD42_MY14_Gas_Tx" SG_ 1378 APIM_Network_Mgmt 1;
BA_ "U_P552_MY15_Gas_Tx" SG_ 1378 APIM_Network_Mgmt 1;
BA_ "U_S550_MY15_Gas_Tx" SG_ 1378 APIM_Network_Mgmt 1;
BA_ "U_C489_MY14_Gas_Tx" SG_ 1378 APIM_Network_Mgmt 1;
BA_ "U_U502_MY15_Gas_Tx" SG_ 1378 APIM_Network_Mgmt 1;
BA_ "U_UP375_MY15_Gas_Tx" SG_ 1378 APIM_Network_Mgmt 1;
BA_ "U_UP375_MY15_Diesel_Tx" SG_ 1378 APIM_Network_Mgmt 1;
BA_ "U_CD43_MY16_Gas_Tx" SG_ 1378 APIM_Network_Mgmt 1;
BA_ "WakeupSignal" SG_ 839 FohKeyOff_B_Rq 1;
BA_ "CrossOver_InfoCAN" SG_ 839 FohKeyOff_B_Rq 1;
BA_ "ContentDependant" SG_ 839 FohKeyOff_B_Rq 1;
BA_ "U_CD4_MY13_Diesel_Rx" SG_ 839 FohKeyOff_B_Rq 1;
BA_ "U_CD4_MY13_Gas_Rx" SG_ 839 FohKeyOff_B_Rq 1;
BA_ "U_CD4_MY13_Hev_Rx" SG_ 839 FohKeyOff_B_Rq 1;
BA_ "U_CD4_MY13_Phev_Rx" SG_ 839 FohKeyOff_B_Rq 1;
BA_ "U_CD42_MY14_Diesel_Rx" SG_ 839 FohKeyOff_B_Rq 1;
BA_ "U_CD42_MY14_Gas_Rx" SG_ 839 FohKeyOff_B_Rq 1;
BA_ "U_P552_MY15_Gas_Rx" SG_ 839 FohKeyOff_B_Rq 1;
BA_ "U_S550_MY15_Gas_Rx" SG_ 839 FohKeyOff_B_Rq 1;
BA_ "U_C489_MY14_Gas_Rx" SG_ 839 FohKeyOff_B_Rq 1;
BA_ "U_U502_MY15_Gas_Rx" SG_ 839 FohKeyOff_B_Rq 1;
BA_ "U_B479_MY15_Gas_Rx" SG_ 839 FohKeyOff_B_Rq 1;
BA_ "U_UP375_MY15_Gas_Rx" SG_ 839 FohKeyOff_B_Rq 1;
BA_ "U_UP375_MY15_Diesel_Rx" SG_ 839 FohKeyOff_B_Rq 1;
BA_ "CrossOver_InfoCAN" SG_ 850 SeatBlLoPsgr_Pc_Actl2 1;
BA_ "GenSigStartValue" SG_ 850 SeatBlLoPsgr_Pc_Actl2 127;
BA_ "U_CD4_MY15_Diesel_Tx" SG_ 850 SeatBlLoPsgr_Pc_Actl2 1;
BA_ "U_CD4_MY15_Gas_Tx" SG_ 850 SeatBlLoPsgr_Pc_Actl2 1;
BA_ "U_CD4_MY15_Hev_Tx" SG_ 850 SeatBlLoPsgr_Pc_Actl2 1;
BA_ "U_CD4_MY15_Phev_Tx" SG_ 850 SeatBlLoPsgr_Pc_Actl2 1;
BA_ "CrossOver_InfoCAN" SG_ 850 SeatCshnPsgrRR_Pc_Actl 1;
BA_ "GenSigStartValue" SG_ 850 SeatCshnPsgrRR_Pc_Actl 127;
BA_ "U_CD4_MY13_Diesel_Tx" SG_ 850 SeatCshnPsgrRR_Pc_Actl 1;
BA_ "U_CD4_MY13_Gas_Tx" SG_ 850 SeatCshnPsgrRR_Pc_Actl 1;
BA_ "U_CD4_MY13_Hev_Tx" SG_ 850 SeatCshnPsgrRR_Pc_Actl 1;
BA_ "U_CD4_MY13_Phev_Tx" SG_ 850 SeatCshnPsgrRR_Pc_Actl 1;
BA_ "U_CD42_MY14_Diesel_Tx" SG_ 850 SeatCshnPsgrRR_Pc_Actl 1;
BA_ "U_CD42_MY14_Gas_Tx" SG_ 850 SeatCshnPsgrRR_Pc_Actl 1;
BA_ "U_P552_MY15_Gas_Tx" SG_ 850 SeatCshnPsgrRR_Pc_Actl 1;
BA_ "U_U502_MY15_Gas_Tx" SG_ 850 SeatCshnPsgrRR_Pc_Actl 1;
BA_ "U_CD43_MY16_Gas_Tx" SG_ 850 SeatCshnPsgrRR_Pc_Actl 1;
BA_ "CrossOver_InfoCAN" SG_ 850 SeatCshnPsgrRL_Pc_Actl 1;
BA_ "GenSigStartValue" SG_ 850 SeatCshnPsgrRL_Pc_Actl 127;
BA_ "U_CD4_MY13_Diesel_Tx" SG_ 850 SeatCshnPsgrRL_Pc_Actl 1;
BA_ "U_CD4_MY13_Gas_Tx" SG_ 850 SeatCshnPsgrRL_Pc_Actl 1;
BA_ "U_CD4_MY13_Hev_Tx" SG_ 850 SeatCshnPsgrRL_Pc_Actl 1;
BA_ "U_CD4_MY13_Phev_Tx" SG_ 850 SeatCshnPsgrRL_Pc_Actl 1;
BA_ "U_CD42_MY14_Diesel_Tx" SG_ 850 SeatCshnPsgrRL_Pc_Actl 1;
BA_ "U_CD42_MY14_Gas_Tx" SG_ 850 SeatCshnPsgrRL_Pc_Actl 1;
BA_ "U_P552_MY15_Gas_Tx" SG_ 850 SeatCshnPsgrRL_Pc_Actl 1;
BA_ "U_U502_MY15_Gas_Tx" SG_ 850 SeatCshnPsgrRL_Pc_Actl 1;
BA_ "U_CD43_MY16_Gas_Tx" SG_ 850 SeatCshnPsgrRL_Pc_Actl 1;
BA_ "CrossOver_InfoCAN" SG_ 850 SeatCshnPsgrFR_Pc_Actl 1;
BA_ "GenSigStartValue" SG_ 850 SeatCshnPsgrFR_Pc_Actl 127;
BA_ "U_CD4_MY13_Diesel_Tx" SG_ 850 SeatCshnPsgrFR_Pc_Actl 1;
BA_ "U_CD4_MY13_Gas_Tx" SG_ 850 SeatCshnPsgrFR_Pc_Actl 1;
BA_ "U_CD4_MY13_Hev_Tx" SG_ 850 SeatCshnPsgrFR_Pc_Actl 1;
BA_ "U_CD4_MY13_Phev_Tx" SG_ 850 SeatCshnPsgrFR_Pc_Actl 1;
BA_ "U_CD42_MY14_Diesel_Tx" SG_ 850 SeatCshnPsgrFR_Pc_Actl 1;
BA_ "U_CD42_MY14_Gas_Tx" SG_ 850 SeatCshnPsgrFR_Pc_Actl 1;
BA_ "U_P552_MY15_Gas_Tx" SG_ 850 SeatCshnPsgrFR_Pc_Actl 1;
BA_ "U_U502_MY15_Gas_Tx" SG_ 850 SeatCshnPsgrFR_Pc_Actl 1;
BA_ "U_CD43_MY16_Gas_Tx" SG_ 850 SeatCshnPsgrFR_Pc_Actl 1;
BA_ "CrossOver_InfoCAN" SG_ 850 SeatCshnPsgrFL_Pc_Actl 1;
BA_ "GenSigStartValue" SG_ 850 SeatCshnPsgrFL_Pc_Actl 127;
BA_ "U_CD4_MY13_Diesel_Tx" SG_ 850 SeatCshnPsgrFL_Pc_Actl 1;
BA_ "U_CD4_MY13_Gas_Tx" SG_ 850 SeatCshnPsgrFL_Pc_Actl 1;
BA_ "U_CD4_MY13_Hev_Tx" SG_ 850 SeatCshnPsgrFL_Pc_Actl 1;
BA_ "U_CD4_MY13_Phev_Tx" SG_ 850 SeatCshnPsgrFL_Pc_Actl 1;
BA_ "U_CD42_MY14_Diesel_Tx" SG_ 850 SeatCshnPsgrFL_Pc_Actl 1;
BA_ "U_CD42_MY14_Gas_Tx" SG_ 850 SeatCshnPsgrFL_Pc_Actl 1;
BA_ "U_P552_MY15_Gas_Tx" SG_ 850 SeatCshnPsgrFL_Pc_Actl 1;
BA_ "U_U502_MY15_Gas_Tx" SG_ 850 SeatCshnPsgrFL_Pc_Actl 1;
BA_ "U_CD43_MY16_Gas_Tx" SG_ 850 SeatCshnPsgrFL_Pc_Actl 1;
BA_ "CrossOver_InfoCAN" SG_ 849 SeatCshnDrvRR_Pc_Actl 1;
BA_ "GenSigStartValue" SG_ 849 SeatCshnDrvRR_Pc_Actl 127;
BA_ "U_CD4_MY13_Diesel_Tx" SG_ 849 SeatCshnDrvRR_Pc_Actl 1;
BA_ "U_CD4_MY13_Gas_Tx" SG_ 849 SeatCshnDrvRR_Pc_Actl 1;
BA_ "U_CD4_MY13_Hev_Tx" SG_ 849 SeatCshnDrvRR_Pc_Actl 1;
BA_ "U_CD4_MY13_Phev_Tx" SG_ 849 SeatCshnDrvRR_Pc_Actl 1;
BA_ "U_CD42_MY14_Diesel_Tx" SG_ 849 SeatCshnDrvRR_Pc_Actl 1;
BA_ "U_CD42_MY14_Gas_Tx" SG_ 849 SeatCshnDrvRR_Pc_Actl 1;
BA_ "U_P552_MY15_Gas_Tx" SG_ 849 SeatCshnDrvRR_Pc_Actl 1;
BA_ "U_U502_MY15_Gas_Tx" SG_ 849 SeatCshnDrvRR_Pc_Actl 1;
BA_ "U_CD43_MY16_Gas_Tx" SG_ 849 SeatCshnDrvRR_Pc_Actl 1;
BA_ "CrossOver_InfoCAN" SG_ 849 SeatCshnDrvRL_Pc_Actl 1;
BA_ "GenSigStartValue" SG_ 849 SeatCshnDrvRL_Pc_Actl 127;
BA_ "U_CD4_MY13_Diesel_Tx" SG_ 849 SeatCshnDrvRL_Pc_Actl 1;
BA_ "U_CD4_MY13_Gas_Tx" SG_ 849 SeatCshnDrvRL_Pc_Actl 1;
BA_ "U_CD4_MY13_Hev_Tx" SG_ 849 SeatCshnDrvRL_Pc_Actl 1;
BA_ "U_CD4_MY13_Phev_Tx" SG_ 849 SeatCshnDrvRL_Pc_Actl 1;
BA_ "U_CD42_MY14_Diesel_Tx" SG_ 849 SeatCshnDrvRL_Pc_Actl 1;
BA_ "U_CD42_MY14_Gas_Tx" SG_ 849 SeatCshnDrvRL_Pc_Actl 1;
BA_ "U_P552_MY15_Gas_Tx" SG_ 849 SeatCshnDrvRL_Pc_Actl 1;
BA_ "U_U502_MY15_Gas_Tx" SG_ 849 SeatCshnDrvRL_Pc_Actl 1;
BA_ "U_CD43_MY16_Gas_Tx" SG_ 849 SeatCshnDrvRL_Pc_Actl 1;
BA_ "CrossOver_InfoCAN" SG_ 849 SeatCshnDrvFR_Pc_Actl 1;
BA_ "GenSigStartValue" SG_ 849 SeatCshnDrvFR_Pc_Actl 127;
BA_ "U_CD4_MY13_Diesel_Tx" SG_ 849 SeatCshnDrvFR_Pc_Actl 1;
BA_ "U_CD4_MY13_Gas_Tx" SG_ 849 SeatCshnDrvFR_Pc_Actl 1;
BA_ "U_CD4_MY13_Hev_Tx" SG_ 849 SeatCshnDrvFR_Pc_Actl 1;
BA_ "U_CD4_MY13_Phev_Tx" SG_ 849 SeatCshnDrvFR_Pc_Actl 1;
BA_ "U_CD42_MY14_Diesel_Tx" SG_ 849 SeatCshnDrvFR_Pc_Actl 1;
BA_ "U_CD42_MY14_Gas_Tx" SG_ 849 SeatCshnDrvFR_Pc_Actl 1;
BA_ "U_P552_MY15_Gas_Tx" SG_ 849 SeatCshnDrvFR_Pc_Actl 1;
BA_ "U_U502_MY15_Gas_Tx" SG_ 849 SeatCshnDrvFR_Pc_Actl 1;
BA_ "U_CD43_MY16_Gas_Tx" SG_ 849 SeatCshnDrvFR_Pc_Actl 1;
BA_ "CrossOver_InfoCAN" SG_ 849 SeatCshnDrvFL_Pc_Actl 1;
BA_ "GenSigStartValue" SG_ 849 SeatCshnDrvFL_Pc_Actl 127;
BA_ "U_CD4_MY13_Diesel_Tx" SG_ 849 SeatCshnDrvFL_Pc_Actl 1;
BA_ "U_CD4_MY13_Gas_Tx" SG_ 849 SeatCshnDrvFL_Pc_Actl 1;
BA_ "U_CD4_MY13_Hev_Tx" SG_ 849 SeatCshnDrvFL_Pc_Actl 1;
BA_ "U_CD4_MY13_Phev_Tx" SG_ 849 SeatCshnDrvFL_Pc_Actl 1;
BA_ "U_CD42_MY14_Diesel_Tx" SG_ 849 SeatCshnDrvFL_Pc_Actl 1;
BA_ "U_CD42_MY14_Gas_Tx" SG_ 849 SeatCshnDrvFL_Pc_Actl 1;
BA_ "U_P552_MY15_Gas_Tx" SG_ 849 SeatCshnDrvFL_Pc_Actl 1;
BA_ "U_U502_MY15_Gas_Tx" SG_ 849 SeatCshnDrvFL_Pc_Actl 1;
BA_ "U_CD43_MY16_Gas_Tx" SG_ 849 SeatCshnDrvFL_Pc_Actl 1;
BA_ "U_P552_MY15_Gas_Rx" SG_ 846 SeatFnChngPsgr2_D_Rq 1;
BA_ "U_U502_MY15_Gas_Rx" SG_ 846 SeatFnChngPsgr2_D_Rq 1;
BA_ "U_CD43_MY16_Gas_Rx" SG_ 846 SeatFnChngPsgr2_D_Rq 1;
BA_ "U_P552_MY15_Gas_Rx" SG_ 846 SeatFnChngDrv2_D_Rq 1;
BA_ "U_U502_MY15_Gas_Rx" SG_ 846 SeatFnChngDrv2_D_Rq 1;
BA_ "U_CD43_MY16_Gas_Rx" SG_ 846 SeatFnChngDrv2_D_Rq 1;
BA_ "CrossOver_InfoCAN" SG_ 846 SeatFnPsgr_D_Rq 1;
BA_ "U_CD4_MY13_Diesel_Rx" SG_ 846 SeatFnPsgr_D_Rq 1;
BA_ "U_CD4_MY13_Gas_Rx" SG_ 846 SeatFnPsgr_D_Rq 1;
BA_ "U_CD4_MY13_Hev_Rx" SG_ 846 SeatFnPsgr_D_Rq 1;
BA_ "U_CD4_MY13_Phev_Rx" SG_ 846 SeatFnPsgr_D_Rq 1;
BA_ "U_CD42_MY14_Diesel_Rx" SG_ 846 SeatFnPsgr_D_Rq 1;
BA_ "U_CD42_MY14_Gas_Rx" SG_ 846 SeatFnPsgr_D_Rq 1;
BA_ "U_P552_MY15_Gas_Rx" SG_ 846 SeatFnPsgr_D_Rq 1;
BA_ "U_U502_MY15_Gas_Rx" SG_ 846 SeatFnPsgr_D_Rq 1;
BA_ "U_CD43_MY16_Gas_Rx" SG_ 846 SeatFnPsgr_D_Rq 1;
BA_ "CrossOver_InfoCAN" SG_ 846 SeatFnDrv_D_Rq 1;
BA_ "U_CD4_MY13_Diesel_Rx" SG_ 846 SeatFnDrv_D_Rq 1;
BA_ "U_CD4_MY13_Gas_Rx" SG_ 846 SeatFnDrv_D_Rq 1;
BA_ "U_CD4_MY13_Hev_Rx" SG_ 846 SeatFnDrv_D_Rq 1;
BA_ "U_CD4_MY13_Phev_Rx" SG_ 846 SeatFnDrv_D_Rq 1;
BA_ "U_CD42_MY14_Diesel_Rx" SG_ 846 SeatFnDrv_D_Rq 1;
BA_ "U_CD42_MY14_Gas_Rx" SG_ 846 SeatFnDrv_D_Rq 1;
BA_ "U_P552_MY15_Gas_Rx" SG_ 846 SeatFnDrv_D_Rq 1;
BA_ "U_U502_MY15_Gas_Rx" SG_ 846 SeatFnDrv_D_Rq 1;
BA_ "U_CD43_MY16_Gas_Rx" SG_ 846 SeatFnDrv_D_Rq 1;
BA_ "CrossOver_InfoCAN" SG_ 846 SeatFnDfaltPsgr_B_Rq 1;
BA_ "U_CD4_MY13_Diesel_Rx" SG_ 846 SeatFnDfaltPsgr_B_Rq 1;
BA_ "U_CD4_MY13_Gas_Rx" SG_ 846 SeatFnDfaltPsgr_B_Rq 1;
BA_ "U_CD4_MY13_Hev_Rx" SG_ 846 SeatFnDfaltPsgr_B_Rq 1;
BA_ "U_CD4_MY13_Phev_Rx" SG_ 846 SeatFnDfaltPsgr_B_Rq 1;
BA_ "U_CD42_MY14_Diesel_Rx" SG_ 846 SeatFnDfaltPsgr_B_Rq 1;
BA_ "U_CD42_MY14_Gas_Rx" SG_ 846 SeatFnDfaltPsgr_B_Rq 1;
BA_ "U_P552_MY15_Gas_Rx" SG_ 846 SeatFnDfaltPsgr_B_Rq 1;
BA_ "U_U502_MY15_Gas_Rx" SG_ 846 SeatFnDfaltPsgr_B_Rq 1;
BA_ "U_CD43_MY16_Gas_Rx" SG_ 846 SeatFnDfaltPsgr_B_Rq 1;
BA_ "CrossOver_InfoCAN" SG_ 846 SeatFnDfaltDrv_B_Rq 1;
BA_ "U_CD4_MY13_Diesel_Rx" SG_ 846 SeatFnDfaltDrv_B_Rq 1;
BA_ "U_CD4_MY13_Gas_Rx" SG_ 846 SeatFnDfaltDrv_B_Rq 1;
BA_ "U_CD4_MY13_Hev_Rx" SG_ 846 SeatFnDfaltDrv_B_Rq 1;
BA_ "U_CD4_MY13_Phev_Rx" SG_ 846 SeatFnDfaltDrv_B_Rq 1;
BA_ "U_CD42_MY14_Diesel_Rx" SG_ 846 SeatFnDfaltDrv_B_Rq 1;
BA_ "U_CD42_MY14_Gas_Rx" SG_ 846 SeatFnDfaltDrv_B_Rq 1;
BA_ "U_P552_MY15_Gas_Rx" SG_ 846 SeatFnDfaltDrv_B_Rq 1;
BA_ "U_U502_MY15_Gas_Rx" SG_ 846 SeatFnDfaltDrv_B_Rq 1;
BA_ "U_CD43_MY16_Gas_Rx" SG_ 846 SeatFnDfaltDrv_B_Rq 1;
BA_ "CrossOver_InfoCAN" SG_ 846 SeatFnChngPsgr_D_Rq 1;
BA_ "U_CD4_MY13_Diesel_Rx" SG_ 846 SeatFnChngPsgr_D_Rq 1;
BA_ "U_CD4_MY13_Gas_Rx" SG_ 846 SeatFnChngPsgr_D_Rq 1;
BA_ "U_CD4_MY13_Hev_Rx" SG_ 846 SeatFnChngPsgr_D_Rq 1;
BA_ "U_CD4_MY13_Phev_Rx" SG_ 846 SeatFnChngPsgr_D_Rq 1;
BA_ "U_CD42_MY14_Diesel_Rx" SG_ 846 SeatFnChngPsgr_D_Rq 1;
BA_ "U_CD42_MY14_Gas_Rx" SG_ 846 SeatFnChngPsgr_D_Rq 1;
BA_ "U_P552_MY15_Gas_Rx" SG_ 846 SeatFnChngPsgr_D_Rq 1;
BA_ "U_U502_MY15_Gas_Rx" SG_ 846 SeatFnChngPsgr_D_Rq 1;
BA_ "U_CD43_MY16_Gas_Rx" SG_ 846 SeatFnChngPsgr_D_Rq 1;
BA_ "CrossOver_InfoCAN" SG_ 846 SeatFnChngDrv_D_Rq 1;
BA_ "U_CD4_MY13_Diesel_Rx" SG_ 846 SeatFnChngDrv_D_Rq 1;
BA_ "U_CD4_MY13_Gas_Rx" SG_ 846 SeatFnChngDrv_D_Rq 1;
BA_ "U_CD4_MY13_Hev_Rx" SG_ 846 SeatFnChngDrv_D_Rq 1;
BA_ "U_CD4_MY13_Phev_Rx" SG_ 846 SeatFnChngDrv_D_Rq 1;
BA_ "U_CD42_MY14_Diesel_Rx" SG_ 846 SeatFnChngDrv_D_Rq 1;
BA_ "U_CD42_MY14_Gas_Rx" SG_ 846 SeatFnChngDrv_D_Rq 1;
BA_ "U_P552_MY15_Gas_Rx" SG_ 846 SeatFnChngDrv_D_Rq 1;
BA_ "U_U502_MY15_Gas_Rx" SG_ 846 SeatFnChngDrv_D_Rq 1;
BA_ "U_CD43_MY16_Gas_Rx" SG_ 846 SeatFnChngDrv_D_Rq 1;
BA_ "CrossOver_InfoCAN" SG_ 846 PsgrMemory_Rq 1;
BA_ "U_CD4_MY13_Diesel_Rx" SG_ 846 PsgrMemory_Rq 1;
BA_ "U_CD4_MY13_Gas_Rx" SG_ 846 PsgrMemory_Rq 1;
BA_ "U_CD4_MY13_Hev_Rx" SG_ 846 PsgrMemory_Rq 1;
BA_ "U_CD4_MY13_Phev_Rx" SG_ 846 PsgrMemory_Rq 1;
BA_ "U_CD42_MY14_Diesel_Rx" SG_ 846 PsgrMemory_Rq 1;
BA_ "U_CD42_MY14_Gas_Rx" SG_ 846 PsgrMemory_Rq 1;
BA_ "U_P552_MY15_Gas_Rx" SG_ 846 PsgrMemory_Rq 1;
BA_ "U_U502_MY15_Gas_Rx" SG_ 846 PsgrMemory_Rq 1;
BA_ "U_CD43_MY16_Gas_Rx" SG_ 846 PsgrMemory_Rq 1;
BA_ "CrossOver_InfoCAN" SG_ 845 StmsLmbrPsgr_D_Stat 1;
BA_ "GenSigSendType" SG_ 845 StmsLmbrPsgr_D_Stat 3;
BA_ "U_CD4_MY13_Diesel_Tx" SG_ 845 StmsLmbrPsgr_D_Stat 1;
BA_ "U_CD4_MY13_Gas_Tx" SG_ 845 StmsLmbrPsgr_D_Stat 1;
BA_ "U_CD4_MY13_Hev_Tx" SG_ 845 StmsLmbrPsgr_D_Stat 1;
BA_ "U_CD4_MY13_Phev_Tx" SG_ 845 StmsLmbrPsgr_D_Stat 1;
BA_ "U_CD42_MY14_Diesel_Tx" SG_ 845 StmsLmbrPsgr_D_Stat 1;
BA_ "U_CD42_MY14_Gas_Tx" SG_ 845 StmsLmbrPsgr_D_Stat 1;
BA_ "U_P552_MY15_Gas_Tx" SG_ 845 StmsLmbrPsgr_D_Stat 1;
BA_ "U_U502_MY15_Gas_Tx" SG_ 845 StmsLmbrPsgr_D_Stat 1;
BA_ "U_CD43_MY16_Gas_Tx" SG_ 845 StmsLmbrPsgr_D_Stat 1;
BA_ "CrossOver_InfoCAN" SG_ 845 StmsCshnPsgr_D_Stat 1;
BA_ "GenSigSendType" SG_ 845 StmsCshnPsgr_D_Stat 3;
BA_ "U_CD4_MY13_Diesel_Tx" SG_ 845 StmsCshnPsgr_D_Stat 1;
BA_ "U_CD4_MY13_Gas_Tx" SG_ 845 StmsCshnPsgr_D_Stat 1;
BA_ "U_CD4_MY13_Hev_Tx" SG_ 845 StmsCshnPsgr_D_Stat 1;
BA_ "U_CD4_MY13_Phev_Tx" SG_ 845 StmsCshnPsgr_D_Stat 1;
BA_ "U_CD42_MY14_Diesel_Tx" SG_ 845 StmsCshnPsgr_D_Stat 1;
BA_ "U_CD42_MY14_Gas_Tx" SG_ 845 StmsCshnPsgr_D_Stat 1;
BA_ "U_P552_MY15_Gas_Tx" SG_ 845 StmsCshnPsgr_D_Stat 1;
BA_ "U_U502_MY15_Gas_Tx" SG_ 845 StmsCshnPsgr_D_Stat 1;
BA_ "U_CD43_MY16_Gas_Tx" SG_ 845 StmsCshnPsgr_D_Stat 1;
BA_ "CrossOver_InfoCAN" SG_ 845 SeatSwtchPsgr_B_Stat 1;
BA_ "GenSigSendType" SG_ 845 SeatSwtchPsgr_B_Stat 3;
BA_ "U_CD4_MY13_Diesel_Tx" SG_ 845 SeatSwtchPsgr_B_Stat 1;
BA_ "U_CD4_MY13_Gas_Tx" SG_ 845 SeatSwtchPsgr_B_Stat 1;
BA_ "U_CD4_MY13_Hev_Tx" SG_ 845 SeatSwtchPsgr_B_Stat 1;
BA_ "U_CD4_MY13_Phev_Tx" SG_ 845 SeatSwtchPsgr_B_Stat 1;
BA_ "U_CD42_MY14_Diesel_Tx" SG_ 845 SeatSwtchPsgr_B_Stat 1;
BA_ "U_CD42_MY14_Gas_Tx" SG_ 845 SeatSwtchPsgr_B_Stat 1;
BA_ "U_P552_MY15_Gas_Tx" SG_ 845 SeatSwtchPsgr_B_Stat 1;
BA_ "U_U502_MY15_Gas_Tx" SG_ 845 SeatSwtchPsgr_B_Stat 1;
BA_ "U_CD43_MY16_Gas_Tx" SG_ 845 SeatSwtchPsgr_B_Stat 1;
BA_ "CrossOver_InfoCAN" SG_ 845 SeatPPsgr_B_Stat 1;
BA_ "GenSigSendType" SG_ 845 SeatPPsgr_B_Stat 3;
BA_ "U_CD4_MY13_Diesel_Tx" SG_ 845 SeatPPsgr_B_Stat 1;
BA_ "U_CD4_MY13_Gas_Tx" SG_ 845 SeatPPsgr_B_Stat 1;
BA_ "U_CD4_MY13_Hev_Tx" SG_ 845 SeatPPsgr_B_Stat 1;
BA_ "U_CD4_MY13_Phev_Tx" SG_ 845 SeatPPsgr_B_Stat 1;
BA_ "U_CD42_MY14_Diesel_Tx" SG_ 845 SeatPPsgr_B_Stat 1;
BA_ "U_CD42_MY14_Gas_Tx" SG_ 845 SeatPPsgr_B_Stat 1;
BA_ "U_P552_MY15_Gas_Tx" SG_ 845 SeatPPsgr_B_Stat 1;
BA_ "U_U502_MY15_Gas_Tx" SG_ 845 SeatPPsgr_B_Stat 1;
BA_ "U_CD43_MY16_Gas_Tx" SG_ 845 SeatPPsgr_B_Stat 1;
BA_ "CrossOver_InfoCAN" SG_ 845 SeatFnPsgr_D_Stat 1;
BA_ "GenSigSendType" SG_ 845 SeatFnPsgr_D_Stat 3;
BA_ "U_CD4_MY13_Diesel_Tx" SG_ 845 SeatFnPsgr_D_Stat 1;
BA_ "U_CD4_MY13_Gas_Tx" SG_ 845 SeatFnPsgr_D_Stat 1;
BA_ "U_CD4_MY13_Hev_Tx" SG_ 845 SeatFnPsgr_D_Stat 1;
BA_ "U_CD4_MY13_Phev_Tx" SG_ 845 SeatFnPsgr_D_Stat 1;
BA_ "U_CD42_MY14_Diesel_Tx" SG_ 845 SeatFnPsgr_D_Stat 1;
BA_ "U_CD42_MY14_Gas_Tx" SG_ 845 SeatFnPsgr_D_Stat 1;
BA_ "U_P552_MY15_Gas_Tx" SG_ 845 SeatFnPsgr_D_Stat 1;
BA_ "U_U502_MY15_Gas_Tx" SG_ 845 SeatFnPsgr_D_Stat 1;
BA_ "U_CD43_MY16_Gas_Tx" SG_ 845 SeatFnPsgr_D_Stat 1;
BA_ "CrossOver_InfoCAN" SG_ 845 PsgrMemFeedback_Rsp 1;
BA_ "GenSigSendType" SG_ 845 PsgrMemFeedback_Rsp 3;
BA_ "U_CD4_MY13_Diesel_Tx" SG_ 845 PsgrMemFeedback_Rsp 1;
BA_ "U_CD4_MY13_Gas_Tx" SG_ 845 PsgrMemFeedback_Rsp 1;
BA_ "U_CD4_MY13_Hev_Tx" SG_ 845 PsgrMemFeedback_Rsp 1;
BA_ "U_CD4_MY13_Phev_Tx" SG_ 845 PsgrMemFeedback_Rsp 1;
BA_ "U_CD42_MY14_Diesel_Tx" SG_ 845 PsgrMemFeedback_Rsp 1;
BA_ "U_CD42_MY14_Gas_Tx" SG_ 845 PsgrMemFeedback_Rsp 1;
BA_ "U_P552_MY15_Gas_Tx" SG_ 845 PsgrMemFeedback_Rsp 1;
BA_ "U_U502_MY15_Gas_Tx" SG_ 845 PsgrMemFeedback_Rsp 1;
BA_ "U_CD43_MY16_Gas_Tx" SG_ 845 PsgrMemFeedback_Rsp 1;
BA_ "CrossOver_InfoCAN" SG_ 844 StmsLmbrDrv_D_Stat 1;
BA_ "GenSigSendType" SG_ 844 StmsLmbrDrv_D_Stat 3;
BA_ "U_CD4_MY13_Diesel_Tx" SG_ 844 StmsLmbrDrv_D_Stat 1;
BA_ "U_CD4_MY13_Gas_Tx" SG_ 844 StmsLmbrDrv_D_Stat 1;
BA_ "U_CD4_MY13_Hev_Tx" SG_ 844 StmsLmbrDrv_D_Stat 1;
BA_ "U_CD4_MY13_Phev_Tx" SG_ 844 StmsLmbrDrv_D_Stat 1;
BA_ "U_CD42_MY14_Diesel_Tx" SG_ 844 StmsLmbrDrv_D_Stat 1;
BA_ "U_CD42_MY14_Gas_Tx" SG_ 844 StmsLmbrDrv_D_Stat 1;
BA_ "U_P552_MY15_Gas_Tx" SG_ 844 StmsLmbrDrv_D_Stat 1;
BA_ "U_U502_MY15_Gas_Tx" SG_ 844 StmsLmbrDrv_D_Stat 1;
BA_ "U_CD43_MY16_Gas_Tx" SG_ 844 StmsLmbrDrv_D_Stat 1;
BA_ "CrossOver_InfoCAN" SG_ 844 StmsCshnDrv_D_Stat 1;
BA_ "GenSigSendType" SG_ 844 StmsCshnDrv_D_Stat 3;
BA_ "U_CD4_MY13_Diesel_Tx" SG_ 844 StmsCshnDrv_D_Stat 1;
BA_ "U_CD4_MY13_Gas_Tx" SG_ 844 StmsCshnDrv_D_Stat 1;
BA_ "U_CD4_MY13_Hev_Tx" SG_ 844 StmsCshnDrv_D_Stat 1;
BA_ "U_CD4_MY13_Phev_Tx" SG_ 844 StmsCshnDrv_D_Stat 1;
BA_ "U_CD42_MY14_Diesel_Tx" SG_ 844 StmsCshnDrv_D_Stat 1;
BA_ "U_CD42_MY14_Gas_Tx" SG_ 844 StmsCshnDrv_D_Stat 1;
BA_ "U_P552_MY15_Gas_Tx" SG_ 844 StmsCshnDrv_D_Stat 1;
BA_ "U_U502_MY15_Gas_Tx" SG_ 844 StmsCshnDrv_D_Stat 1;
BA_ "U_CD43_MY16_Gas_Tx" SG_ 844 StmsCshnDrv_D_Stat 1;
BA_ "CrossOver_InfoCAN" SG_ 844 SeatSwtchDrv_B_Stat 1;
BA_ "GenSigSendType" SG_ 844 SeatSwtchDrv_B_Stat 3;
BA_ "U_CD4_MY13_Diesel_Tx" SG_ 844 SeatSwtchDrv_B_Stat 1;
BA_ "U_CD4_MY13_Gas_Tx" SG_ 844 SeatSwtchDrv_B_Stat 1;
BA_ "U_CD4_MY13_Hev_Tx" SG_ 844 SeatSwtchDrv_B_Stat 1;
BA_ "U_CD4_MY13_Phev_Tx" SG_ 844 SeatSwtchDrv_B_Stat 1;
BA_ "U_CD42_MY14_Diesel_Tx" SG_ 844 SeatSwtchDrv_B_Stat 1;
BA_ "U_CD42_MY14_Gas_Tx" SG_ 844 SeatSwtchDrv_B_Stat 1;
BA_ "U_P552_MY15_Gas_Tx" SG_ 844 SeatSwtchDrv_B_Stat 1;
BA_ "U_U502_MY15_Gas_Tx" SG_ 844 SeatSwtchDrv_B_Stat 1;
BA_ "U_CD43_MY16_Gas_Tx" SG_ 844 SeatSwtchDrv_B_Stat 1;
BA_ "CrossOver_InfoCAN" SG_ 844 SeatFnDrv_D_Stat 1;
BA_ "GenSigSendType" SG_ 844 SeatFnDrv_D_Stat 3;
BA_ "U_CD4_MY13_Diesel_Tx" SG_ 844 SeatFnDrv_D_Stat 1;
BA_ "U_CD4_MY13_Gas_Tx" SG_ 844 SeatFnDrv_D_Stat 1;
BA_ "U_CD4_MY13_Hev_Tx" SG_ 844 SeatFnDrv_D_Stat 1;
BA_ "U_CD4_MY13_Phev_Tx" SG_ 844 SeatFnDrv_D_Stat 1;
BA_ "U_CD42_MY14_Diesel_Tx" SG_ 844 SeatFnDrv_D_Stat 1;
BA_ "U_CD42_MY14_Gas_Tx" SG_ 844 SeatFnDrv_D_Stat 1;
BA_ "U_P552_MY15_Gas_Tx" SG_ 844 SeatFnDrv_D_Stat 1;
BA_ "U_U502_MY15_Gas_Tx" SG_ 844 SeatFnDrv_D_Stat 1;
BA_ "U_CD43_MY16_Gas_Tx" SG_ 844 SeatFnDrv_D_Stat 1;
BA_ "CrossOver_InfoCAN" SG_ 844 SeatAirAmb_P_Actl 1;
BA_ "GenSigSendType" SG_ 844 SeatAirAmb_P_Actl 3;
BA_ "U_CD4_MY13_Diesel_Rx" SG_ 844 SeatAirAmb_P_Actl 1;
BA_ "U_CD4_MY13_Gas_Rx" SG_ 844 SeatAirAmb_P_Actl 1;
BA_ "U_CD4_MY13_Hev_Rx" SG_ 844 SeatAirAmb_P_Actl 1;
BA_ "U_CD4_MY13_Phev_Rx" SG_ 844 SeatAirAmb_P_Actl 1;
BA_ "U_CD42_MY14_Diesel_Rx" SG_ 844 SeatAirAmb_P_Actl 1;
BA_ "U_CD42_MY14_Gas_Rx" SG_ 844 SeatAirAmb_P_Actl 1;
BA_ "U_P552_MY15_Gas_Rx" SG_ 844 SeatAirAmb_P_Actl 1;
BA_ "U_U502_MY15_Gas_Rx" SG_ 844 SeatAirAmb_P_Actl 1;
BA_ "U_CD43_MY16_Gas_Rx" SG_ 844 SeatAirAmb_P_Actl 1;
BA_ "U_CD4_MY13_Diesel_Tx" SG_ 844 SeatAirAmb_P_Actl 1;
BA_ "U_CD4_MY13_Gas_Tx" SG_ 844 SeatAirAmb_P_Actl 1;
BA_ "U_CD4_MY13_Hev_Tx" SG_ 844 SeatAirAmb_P_Actl 1;
BA_ "U_CD4_MY13_Phev_Tx" SG_ 844 SeatAirAmb_P_Actl 1;
BA_ "U_CD42_MY14_Diesel_Tx" SG_ 844 SeatAirAmb_P_Actl 1;
BA_ "U_CD42_MY14_Gas_Tx" SG_ 844 SeatAirAmb_P_Actl 1;
BA_ "U_P552_MY15_Gas_Tx" SG_ 844 SeatAirAmb_P_Actl 1;
BA_ "U_U502_MY15_Gas_Tx" SG_ 844 SeatAirAmb_P_Actl 1;
BA_ "U_CD43_MY16_Gas_Tx" SG_ 844 SeatAirAmb_P_Actl 1;
BA_ "CrossOver_InfoCAN" SG_ 844 SeatPDrv_B_Stat 1;
BA_ "GenSigSendType" SG_ 844 SeatPDrv_B_Stat 3;
BA_ "U_CD4_MY13_Diesel_Tx" SG_ 844 SeatPDrv_B_Stat 1;
BA_ "U_CD4_MY13_Gas_Tx" SG_ 844 SeatPDrv_B_Stat 1;
BA_ "U_CD4_MY13_Hev_Tx" SG_ 844 SeatPDrv_B_Stat 1;
BA_ "U_CD4_MY13_Phev_Tx" SG_ 844 SeatPDrv_B_Stat 1;
BA_ "U_CD42_MY14_Diesel_Tx" SG_ 844 SeatPDrv_B_Stat 1;
BA_ "U_CD42_MY14_Gas_Tx" SG_ 844 SeatPDrv_B_Stat 1;
BA_ "U_P552_MY15_Gas_Tx" SG_ 844 SeatPDrv_B_Stat 1;
BA_ "U_U502_MY15_Gas_Tx" SG_ 844 SeatPDrv_B_Stat 1;
BA_ "U_CD43_MY16_Gas_Tx" SG_ 844 SeatPDrv_B_Stat 1;
BA_ "CrossOver_InfoCAN" SG_ 843 SeatLmbrUpPsgr_Pc_Actl 1;
BA_ "U_CD4_MY13_Diesel_Tx" SG_ 843 SeatLmbrUpPsgr_Pc_Actl 1;
BA_ "U_CD4_MY13_Gas_Tx" SG_ 843 SeatLmbrUpPsgr_Pc_Actl 1;
BA_ "U_CD4_MY13_Hev_Tx" SG_ 843 SeatLmbrUpPsgr_Pc_Actl 1;
BA_ "U_CD4_MY13_Phev_Tx" SG_ 843 SeatLmbrUpPsgr_Pc_Actl 1;
BA_ "U_CD42_MY14_Diesel_Tx" SG_ 843 SeatLmbrUpPsgr_Pc_Actl 1;
BA_ "U_CD42_MY14_Gas_Tx" SG_ 843 SeatLmbrUpPsgr_Pc_Actl 1;
BA_ "U_P552_MY15_Gas_Tx" SG_ 843 SeatLmbrUpPsgr_Pc_Actl 1;
BA_ "U_U502_MY15_Gas_Tx" SG_ 843 SeatLmbrUpPsgr_Pc_Actl 1;
BA_ "U_CD43_MY16_Gas_Tx" SG_ 843 SeatLmbrUpPsgr_Pc_Actl 1;
BA_ "CrossOver_InfoCAN" SG_ 843 SeatLmbrMidPsgr_Pc_Actl 1;
BA_ "U_CD4_MY13_Diesel_Tx" SG_ 843 SeatLmbrMidPsgr_Pc_Actl 1;
BA_ "U_CD4_MY13_Gas_Tx" SG_ 843 SeatLmbrMidPsgr_Pc_Actl 1;
BA_ "U_CD4_MY13_Hev_Tx" SG_ 843 SeatLmbrMidPsgr_Pc_Actl 1;
BA_ "U_CD4_MY13_Phev_Tx" SG_ 843 SeatLmbrMidPsgr_Pc_Actl 1;
BA_ "U_CD42_MY14_Diesel_Tx" SG_ 843 SeatLmbrMidPsgr_Pc_Actl 1;
BA_ "U_CD42_MY14_Gas_Tx" SG_ 843 SeatLmbrMidPsgr_Pc_Actl 1;
BA_ "U_P552_MY15_Gas_Tx" SG_ 843 SeatLmbrMidPsgr_Pc_Actl 1;
BA_ "U_U502_MY15_Gas_Tx" SG_ 843 SeatLmbrMidPsgr_Pc_Actl 1;
BA_ "U_CD43_MY16_Gas_Tx" SG_ 843 SeatLmbrMidPsgr_Pc_Actl 1;
BA_ "CrossOver_InfoCAN" SG_ 843 SeatLmbrLoPsgr_Pc_Actl 1;
BA_ "U_CD4_MY13_Diesel_Tx" SG_ 843 SeatLmbrLoPsgr_Pc_Actl 1;
BA_ "U_CD4_MY13_Gas_Tx" SG_ 843 SeatLmbrLoPsgr_Pc_Actl 1;
BA_ "U_CD4_MY13_Hev_Tx" SG_ 843 SeatLmbrLoPsgr_Pc_Actl 1;
BA_ "U_CD4_MY13_Phev_Tx" SG_ 843 SeatLmbrLoPsgr_Pc_Actl 1;
BA_ "U_CD42_MY14_Diesel_Tx" SG_ 843 SeatLmbrLoPsgr_Pc_Actl 1;
BA_ "U_CD42_MY14_Gas_Tx" SG_ 843 SeatLmbrLoPsgr_Pc_Actl 1;
BA_ "U_P552_MY15_Gas_Tx" SG_ 843 SeatLmbrLoPsgr_Pc_Actl 1;
BA_ "U_U502_MY15_Gas_Tx" SG_ 843 SeatLmbrLoPsgr_Pc_Actl 1;
BA_ "U_CD43_MY16_Gas_Tx" SG_ 843 SeatLmbrLoPsgr_Pc_Actl 1;
BA_ "CrossOver_InfoCAN" SG_ 843 SeatBlUpPsgr_Pc_Actl 1;
BA_ "GenSigStartValue" SG_ 843 SeatBlUpPsgr_Pc_Actl 127;
BA_ "U_CD4_MY13_Diesel_Tx" SG_ 843 SeatBlUpPsgr_Pc_Actl 1;
BA_ "U_CD4_MY13_Gas_Tx" SG_ 843 SeatBlUpPsgr_Pc_Actl 1;
BA_ "U_CD4_MY13_Hev_Tx" SG_ 843 SeatBlUpPsgr_Pc_Actl 1;
BA_ "U_CD4_MY13_Phev_Tx" SG_ 843 SeatBlUpPsgr_Pc_Actl 1;
BA_ "U_CD42_MY14_Diesel_Tx" SG_ 843 SeatBlUpPsgr_Pc_Actl 1;
BA_ "U_CD42_MY14_Gas_Tx" SG_ 843 SeatBlUpPsgr_Pc_Actl 1;
BA_ "U_P552_MY15_Gas_Tx" SG_ 843 SeatBlUpPsgr_Pc_Actl 1;
BA_ "U_U502_MY15_Gas_Tx" SG_ 843 SeatBlUpPsgr_Pc_Actl 1;
BA_ "U_CD43_MY16_Gas_Tx" SG_ 843 SeatBlUpPsgr_Pc_Actl 1;
BA_ "CrossOver_InfoCAN" SG_ 843 SeatBlLoPsgr_Pc_Actl 1;
BA_ "GenSigStartValue" SG_ 843 SeatBlLoPsgr_Pc_Actl 127;
BA_ "U_CD4_MY13_Diesel_Tx" SG_ 843 SeatBlLoPsgr_Pc_Actl 1;
BA_ "U_CD4_MY13_Gas_Tx" SG_ 843 SeatBlLoPsgr_Pc_Actl 1;
BA_ "U_CD4_MY13_Hev_Tx" SG_ 843 SeatBlLoPsgr_Pc_Actl 1;
BA_ "U_CD4_MY13_Phev_Tx" SG_ 843 SeatBlLoPsgr_Pc_Actl 1;
BA_ "U_CD42_MY14_Diesel_Tx" SG_ 843 SeatBlLoPsgr_Pc_Actl 1;
BA_ "U_CD42_MY14_Gas_Tx" SG_ 843 SeatBlLoPsgr_Pc_Actl 1;
BA_ "U_P552_MY15_Gas_Tx" SG_ 843 SeatBlLoPsgr_Pc_Actl 1;
BA_ "U_U502_MY15_Gas_Tx" SG_ 843 SeatBlLoPsgr_Pc_Actl 1;
BA_ "U_CD43_MY16_Gas_Tx" SG_ 843 SeatBlLoPsgr_Pc_Actl 1;
BA_ "CrossOver_InfoCAN" SG_ 842 SeatLmbrUpDrv_Pc_Actl 1;
BA_ "U_CD4_MY13_Diesel_Tx" SG_ 842 SeatLmbrUpDrv_Pc_Actl 1;
BA_ "U_CD4_MY13_Gas_Tx" SG_ 842 SeatLmbrUpDrv_Pc_Actl 1;
BA_ "U_CD4_MY13_Hev_Tx" SG_ 842 SeatLmbrUpDrv_Pc_Actl 1;
BA_ "U_CD4_MY13_Phev_Tx" SG_ 842 SeatLmbrUpDrv_Pc_Actl 1;
BA_ "U_CD42_MY14_Diesel_Tx" SG_ 842 SeatLmbrUpDrv_Pc_Actl 1;
BA_ "U_CD42_MY14_Gas_Tx" SG_ 842 SeatLmbrUpDrv_Pc_Actl 1;
BA_ "U_P552_MY15_Gas_Tx" SG_ 842 SeatLmbrUpDrv_Pc_Actl 1;
BA_ "U_U502_MY15_Gas_Tx" SG_ 842 SeatLmbrUpDrv_Pc_Actl 1;
BA_ "U_CD43_MY16_Gas_Tx" SG_ 842 SeatLmbrUpDrv_Pc_Actl 1;
BA_ "CrossOver_InfoCAN" SG_ 842 SeatLmbrMidDrv_Pc_Actl 1;
BA_ "U_CD4_MY13_Diesel_Tx" SG_ 842 SeatLmbrMidDrv_Pc_Actl 1;
BA_ "U_CD4_MY13_Gas_Tx" SG_ 842 SeatLmbrMidDrv_Pc_Actl 1;
BA_ "U_CD4_MY13_Hev_Tx" SG_ 842 SeatLmbrMidDrv_Pc_Actl 1;
BA_ "U_CD4_MY13_Phev_Tx" SG_ 842 SeatLmbrMidDrv_Pc_Actl 1;
BA_ "U_CD42_MY14_Diesel_Tx" SG_ 842 SeatLmbrMidDrv_Pc_Actl 1;
BA_ "U_CD42_MY14_Gas_Tx" SG_ 842 SeatLmbrMidDrv_Pc_Actl 1;
BA_ "U_P552_MY15_Gas_Tx" SG_ 842 SeatLmbrMidDrv_Pc_Actl 1;
BA_ "U_U502_MY15_Gas_Tx" SG_ 842 SeatLmbrMidDrv_Pc_Actl 1;
BA_ "U_CD43_MY16_Gas_Tx" SG_ 842 SeatLmbrMidDrv_Pc_Actl 1;
BA_ "CrossOver_InfoCAN" SG_ 842 SeatLmbrLoDrv_Pc_Actl 1;
BA_ "U_CD4_MY13_Diesel_Tx" SG_ 842 SeatLmbrLoDrv_Pc_Actl 1;
BA_ "U_CD4_MY13_Gas_Tx" SG_ 842 SeatLmbrLoDrv_Pc_Actl 1;
BA_ "U_CD4_MY13_Hev_Tx" SG_ 842 SeatLmbrLoDrv_Pc_Actl 1;
BA_ "U_CD4_MY13_Phev_Tx" SG_ 842 SeatLmbrLoDrv_Pc_Actl 1;
BA_ "U_CD42_MY14_Diesel_Tx" SG_ 842 SeatLmbrLoDrv_Pc_Actl 1;
BA_ "U_CD42_MY14_Gas_Tx" SG_ 842 SeatLmbrLoDrv_Pc_Actl 1;
BA_ "U_P552_MY15_Gas_Tx" SG_ 842 SeatLmbrLoDrv_Pc_Actl 1;
BA_ "U_U502_MY15_Gas_Tx" SG_ 842 SeatLmbrLoDrv_Pc_Actl 1;
BA_ "U_CD43_MY16_Gas_Tx" SG_ 842 SeatLmbrLoDrv_Pc_Actl 1;
BA_ "CrossOver_InfoCAN" SG_ 842 SeatBlUpDrv_Pc_Actl 1;
BA_ "GenSigStartValue" SG_ 842 SeatBlUpDrv_Pc_Actl 127;
BA_ "U_CD4_MY13_Diesel_Tx" SG_ 842 SeatBlUpDrv_Pc_Actl 1;
BA_ "U_CD4_MY13_Gas_Tx" SG_ 842 SeatBlUpDrv_Pc_Actl 1;
BA_ "U_CD4_MY13_Hev_Tx" SG_ 842 SeatBlUpDrv_Pc_Actl 1;
BA_ "U_CD4_MY13_Phev_Tx" SG_ 842 SeatBlUpDrv_Pc_Actl 1;
BA_ "U_CD42_MY14_Diesel_Tx" SG_ 842 SeatBlUpDrv_Pc_Actl 1;
BA_ "U_CD42_MY14_Gas_Tx" SG_ 842 SeatBlUpDrv_Pc_Actl 1;
BA_ "U_P552_MY15_Gas_Tx" SG_ 842 SeatBlUpDrv_Pc_Actl 1;
BA_ "U_U502_MY15_Gas_Tx" SG_ 842 SeatBlUpDrv_Pc_Actl 1;
BA_ "U_CD43_MY16_Gas_Tx" SG_ 842 SeatBlUpDrv_Pc_Actl 1;
BA_ "CrossOver_InfoCAN" SG_ 842 SeatBlLoDrv_Pc_Actl 1;
BA_ "GenSigStartValue" SG_ 842 SeatBlLoDrv_Pc_Actl 127;
BA_ "U_CD4_MY13_Diesel_Tx" SG_ 842 SeatBlLoDrv_Pc_Actl 1;
BA_ "U_CD4_MY13_Gas_Tx" SG_ 842 SeatBlLoDrv_Pc_Actl 1;
BA_ "U_CD4_MY13_Hev_Tx" SG_ 842 SeatBlLoDrv_Pc_Actl 1;
BA_ "U_CD4_MY13_Phev_Tx" SG_ 842 SeatBlLoDrv_Pc_Actl 1;
BA_ "U_CD42_MY14_Diesel_Tx" SG_ 842 SeatBlLoDrv_Pc_Actl 1;
BA_ "U_CD42_MY14_Gas_Tx" SG_ 842 SeatBlLoDrv_Pc_Actl 1;
BA_ "U_P552_MY15_Gas_Tx" SG_ 842 SeatBlLoDrv_Pc_Actl 1;
BA_ "U_U502_MY15_Gas_Tx" SG_ 842 SeatBlLoDrv_Pc_Actl 1;
BA_ "U_CD43_MY16_Gas_Tx" SG_ 842 SeatBlLoDrv_Pc_Actl 1;
BA_ "GenSigSendType" SG_ 1994 TesterPhysicalResRSM 3;
BA_ "U_CD4_MY13_Diesel_Tx" SG_ 1994 TesterPhysicalResRSM 1;
BA_ "U_CD4_MY13_Gas_Tx" SG_ 1994 TesterPhysicalResRSM 1;
BA_ "U_CD4_MY13_Hev_Tx" SG_ 1994 TesterPhysicalResRSM 1;
BA_ "U_CD4_MY13_Phev_Tx" SG_ 1994 TesterPhysicalResRSM 1;
BA_ "U_CD42_MY14_Diesel_Tx" SG_ 1994 TesterPhysicalResRSM 1;
BA_ "U_CD42_MY14_Gas_Tx" SG_ 1994 TesterPhysicalResRSM 1;
BA_ "U_P552_MY15_Gas_Tx" SG_ 1994 TesterPhysicalResRSM 1;
BA_ "U_S550_MY15_Gas_Tx" SG_ 1994 TesterPhysicalResRSM 1;
BA_ "U_C489_MY14_Gas_Tx" SG_ 1994 TesterPhysicalResRSM 1;
BA_ "U_U502_MY15_Gas_Tx" SG_ 1994 TesterPhysicalResRSM 1;
BA_ "U_CD43_MY16_Gas_Tx" SG_ 1994 TesterPhysicalResRSM 1;
BA_ "U_CD4_MY14_Diesel_Tx" SG_ 1994 TesterPhysicalResRSM 1;
BA_ "U_CD4_MY14_Gas_Tx" SG_ 1994 TesterPhysicalResRSM 1;
BA_ "U_CD4_MY14_Hev_Tx" SG_ 1994 TesterPhysicalResRSM 1;
BA_ "U_CD4_MY14_Phev_Tx" SG_ 1994 TesterPhysicalResRSM 1;
BA_ "GenSigSendType" SG_ 1986 TesterPhysicalReqRSM 3;
BA_ "U_CD4_MY13_Diesel_Rx" SG_ 1986 TesterPhysicalReqRSM 1;
BA_ "U_CD4_MY13_Gas_Rx" SG_ 1986 TesterPhysicalReqRSM 1;
BA_ "U_CD4_MY13_Hev_Rx" SG_ 1986 TesterPhysicalReqRSM 1;
BA_ "U_CD4_MY13_Phev_Rx" SG_ 1986 TesterPhysicalReqRSM 1;
BA_ "U_CD42_MY14_Diesel_Rx" SG_ 1986 TesterPhysicalReqRSM 1;
BA_ "U_CD42_MY14_Gas_Rx" SG_ 1986 TesterPhysicalReqRSM 1;
BA_ "U_P552_MY15_Gas_Rx" SG_ 1986 TesterPhysicalReqRSM 1;
BA_ "U_S550_MY15_Gas_Rx" SG_ 1986 TesterPhysicalReqRSM 1;
BA_ "U_C489_MY14_Gas_Rx" SG_ 1986 TesterPhysicalReqRSM 1;
BA_ "U_U502_MY15_Gas_Rx" SG_ 1986 TesterPhysicalReqRSM 1;
BA_ "U_CD43_MY16_Gas_Rx" SG_ 1986 TesterPhysicalReqRSM 1;
BA_ "U_CD4_MY14_Diesel_Rx" SG_ 1986 TesterPhysicalReqRSM 1;
BA_ "U_CD4_MY14_Gas_Rx" SG_ 1986 TesterPhysicalReqRSM 1;
BA_ "U_CD4_MY14_Hev_Rx" SG_ 1986 TesterPhysicalReqRSM 1;
BA_ "U_CD4_MY14_Phev_Rx" SG_ 1986 TesterPhysicalReqRSM 1;
BA_ "GenSigSendType" SG_ 1383 RSM_Network_Mgmt 3;
BA_ "U_CD4_MY13_Diesel_Rx" SG_ 1383 RSM_Network_Mgmt 1;
BA_ "U_CD4_MY13_Gas_Rx" SG_ 1383 RSM_Network_Mgmt 1;
BA_ "U_CD4_MY13_Hev_Rx" SG_ 1383 RSM_Network_Mgmt 1;
BA_ "U_CD4_MY13_Phev_Rx" SG_ 1383 RSM_Network_Mgmt 1;
BA_ "U_CD42_MY14_Diesel_Rx" SG_ 1383 RSM_Network_Mgmt 1;
BA_ "U_CD42_MY14_Gas_Rx" SG_ 1383 RSM_Network_Mgmt 1;
BA_ "U_P552_MY15_Gas_Rx" SG_ 1383 RSM_Network_Mgmt 1;
BA_ "U_C489_MY14_Gas_Rx" SG_ 1383 RSM_Network_Mgmt 1;
BA_ "U_UP375_MY15_Gas_Rx" SG_ 1383 RSM_Network_Mgmt 1;
BA_ "U_UP375_MY15_Diesel_Rx" SG_ 1383 RSM_Network_Mgmt 1;
BA_ "U_S550_MY15_Gas_Rx" SG_ 1383 RSM_Network_Mgmt 1;
BA_ "U_U502_MY15_Gas_Rx" SG_ 1383 RSM_Network_Mgmt 1;
BA_ "U_CD43_MY16_Gas_Rx" SG_ 1383 RSM_Network_Mgmt 1;
BA_ "U_CD4_MY14_Diesel_Rx" SG_ 1383 RSM_Network_Mgmt 1;
BA_ "U_CD4_MY14_Gas_Rx" SG_ 1383 RSM_Network_Mgmt 1;
BA_ "U_CD4_MY14_Hev_Rx" SG_ 1383 RSM_Network_Mgmt 1;
BA_ "U_CD4_MY14_Phev_Rx" SG_ 1383 RSM_Network_Mgmt 1;
BA_ "U_CD4_MY13_Diesel_Tx" SG_ 1383 RSM_Network_Mgmt 1;
BA_ "U_CD4_MY13_Gas_Tx" SG_ 1383 RSM_Network_Mgmt 1;
BA_ "U_CD4_MY13_Hev_Tx" SG_ 1383 RSM_Network_Mgmt 1;
BA_ "U_CD4_MY13_Phev_Tx" SG_ 1383 RSM_Network_Mgmt 1;
BA_ "U_CD42_MY14_Diesel_Tx" SG_ 1383 RSM_Network_Mgmt 1;
BA_ "U_CD42_MY14_Gas_Tx" SG_ 1383 RSM_Network_Mgmt 1;
BA_ "U_P552_MY15_Gas_Tx" SG_ 1383 RSM_Network_Mgmt 1;
BA_ "U_S550_MY15_Gas_Tx" SG_ 1383 RSM_Network_Mgmt 1;
BA_ "U_C489_MY14_Gas_Tx" SG_ 1383 RSM_Network_Mgmt 1;
BA_ "U_U502_MY15_Gas_Tx" SG_ 1383 RSM_Network_Mgmt 1;
BA_ "U_CD43_MY16_Gas_Tx" SG_ 1383 RSM_Network_Mgmt 1;
BA_ "U_CD4_MY14_Diesel_Tx" SG_ 1383 RSM_Network_Mgmt 1;
BA_ "U_CD4_MY14_Gas_Tx" SG_ 1383 RSM_Network_Mgmt 1;
BA_ "U_CD4_MY14_Hev_Tx" SG_ 1383 RSM_Network_Mgmt 1;
BA_ "U_CD4_MY14_Phev_Tx" SG_ 1383 RSM_Network_Mgmt 1;
BA_ "GenSigSendType" SG_ 958 EngOff_T_Actl 3;
BA_ "U_CD4_MY13_Diesel_Rx" SG_ 958 EngOff_T_Actl 1;
BA_ "U_CD4_MY13_Gas_Rx" SG_ 958 EngOff_T_Actl 1;
BA_ "U_CD4_MY13_Hev_Rx" SG_ 958 EngOff_T_Actl 1;
BA_ "U_CD4_MY13_Phev_Rx" SG_ 958 EngOff_T_Actl 1;
BA_ "U_CD42_MY14_Diesel_Rx" SG_ 958 EngOff_T_Actl 1;
BA_ "U_CD42_MY14_Gas_Rx" SG_ 958 EngOff_T_Actl 1;
BA_ "U_P552_MY15_Gas_Rx" SG_ 958 EngOff_T_Actl 1;
BA_ "U_S550_MY15_Gas_Rx" SG_ 958 EngOff_T_Actl 1;
BA_ "U_C489_MY14_Gas_Rx" SG_ 958 EngOff_T_Actl 1;
BA_ "U_U502_MY15_Gas_Rx" SG_ 958 EngOff_T_Actl 1;
BA_ "U_UP375_MY15_Gas_Rx" SG_ 958 EngOff_T_Actl 1;
BA_ "U_UP375_MY15_Diesel_Rx" SG_ 958 EngOff_T_Actl 1;
BA_ "U_CD43_MY16_Gas_Rx" SG_ 958 EngOff_T_Actl 1;
BA_ "U_CD4_MY13_Diesel_Rx" SG_ 958 EngOff_T_Actl_UB 1;
BA_ "U_CD4_MY13_Gas_Rx" SG_ 958 EngOff_T_Actl_UB 1;
BA_ "U_CD4_MY13_Hev_Rx" SG_ 958 EngOff_T_Actl_UB 1;
BA_ "U_CD4_MY13_Phev_Rx" SG_ 958 EngOff_T_Actl_UB 1;
BA_ "U_CD42_MY14_Diesel_Rx" SG_ 958 EngOff_T_Actl_UB 1;
BA_ "U_CD42_MY14_Gas_Rx" SG_ 958 EngOff_T_Actl_UB 1;
BA_ "U_P552_MY15_Gas_Rx" SG_ 958 EngOff_T_Actl_UB 1;
BA_ "U_S550_MY15_Gas_Rx" SG_ 958 EngOff_T_Actl_UB 1;
BA_ "U_C489_MY14_Gas_Rx" SG_ 958 EngOff_T_Actl_UB 1;
BA_ "U_U502_MY15_Gas_Rx" SG_ 958 EngOff_T_Actl_UB 1;
BA_ "U_UP375_MY15_Gas_Rx" SG_ 958 EngOff_T_Actl_UB 1;
BA_ "U_UP375_MY15_Diesel_Rx" SG_ 958 EngOff_T_Actl_UB 1;
BA_ "U_CD43_MY16_Gas_Rx" SG_ 958 EngOff_T_Actl_UB 1;
BA_ "U_CD4_MY13_Diesel_Rx" SG_ 958 StopStrtDrvMde_D_Indic_UB 1;
BA_ "U_CD4_MY13_Gas_Rx" SG_ 958 StopStrtDrvMde_D_Indic_UB 1;
BA_ "U_CD4_MY13_Hev_Rx" SG_ 958 StopStrtDrvMde_D_Indic_UB 1;
BA_ "U_CD4_MY13_Phev_Rx" SG_ 958 StopStrtDrvMde_D_Indic_UB 1;
BA_ "U_CD42_MY14_Diesel_Rx" SG_ 958 StopStrtDrvMde_D_Indic_UB 1;
BA_ "U_CD42_MY14_Gas_Rx" SG_ 958 StopStrtDrvMde_D_Indic_UB 1;
BA_ "U_P552_MY15_Gas_Rx" SG_ 958 StopStrtDrvMde_D_Indic_UB 1;
BA_ "U_U502_MY15_Gas_Rx" SG_ 958 StopStrtDrvMde_D_Indic_UB 1;
BA_ "U_UP375_MY15_Gas_Rx" SG_ 958 StopStrtDrvMde_D_Indic_UB 1;
BA_ "U_UP375_MY15_Diesel_Rx" SG_ 958 StopStrtDrvMde_D_Indic_UB 1;
BA_ "U_CD43_MY16_Gas_Rx" SG_ 958 StopStrtDrvMde_D_Indic_UB 1;
BA_ "GenSigSendType" SG_ 958 PrmtrAlrmEvnt_D_Stat 3;
BA_ "U_CD4_MY13_Diesel_Rx" SG_ 958 PrmtrAlrmEvnt_D_Stat 1;
BA_ "U_CD4_MY13_Gas_Rx" SG_ 958 PrmtrAlrmEvnt_D_Stat 1;
BA_ "U_CD4_MY13_Hev_Rx" SG_ 958 PrmtrAlrmEvnt_D_Stat 1;
BA_ "U_CD4_MY13_Phev_Rx" SG_ 958 PrmtrAlrmEvnt_D_Stat 1;
BA_ "U_CD42_MY14_Diesel_Rx" SG_ 958 PrmtrAlrmEvnt_D_Stat 1;
BA_ "U_CD42_MY14_Gas_Rx" SG_ 958 PrmtrAlrmEvnt_D_Stat 1;
BA_ "U_P552_MY15_Gas_Rx" SG_ 958 PrmtrAlrmEvnt_D_Stat 1;
BA_ "U_S550_MY15_Gas_Rx" SG_ 958 PrmtrAlrmEvnt_D_Stat 1;
BA_ "U_C489_MY14_Gas_Rx" SG_ 958 PrmtrAlrmEvnt_D_Stat 1;
BA_ "U_U502_MY15_Gas_Rx" SG_ 958 PrmtrAlrmEvnt_D_Stat 1;
BA_ "U_CD43_MY16_Gas_Rx" SG_ 958 PrmtrAlrmEvnt_D_Stat 1;
BA_ "U_CD4_MY14_Diesel_Rx" SG_ 958 PrmtrAlrmEvnt_D_Stat 1;
BA_ "U_CD4_MY14_Gas_Rx" SG_ 958 PrmtrAlrmEvnt_D_Stat 1;
BA_ "U_CD4_MY14_Hev_Rx" SG_ 958 PrmtrAlrmEvnt_D_Stat 1;
BA_ "U_CD4_MY14_Phev_Rx" SG_ 958 PrmtrAlrmEvnt_D_Stat 1;
BA_ "U_CD4_MY13_Diesel_Rx" SG_ 958 PrmtrAlrmEvnt_D_Stat_UB 1;
BA_ "U_CD4_MY13_Gas_Rx" SG_ 958 PrmtrAlrmEvnt_D_Stat_UB 1;
BA_ "U_CD4_MY13_Hev_Rx" SG_ 958 PrmtrAlrmEvnt_D_Stat_UB 1;
BA_ "U_CD4_MY13_Phev_Rx" SG_ 958 PrmtrAlrmEvnt_D_Stat_UB 1;
BA_ "U_CD42_MY14_Diesel_Rx" SG_ 958 PrmtrAlrmEvnt_D_Stat_UB 1;
BA_ "U_CD42_MY14_Gas_Rx" SG_ 958 PrmtrAlrmEvnt_D_Stat_UB 1;
BA_ "U_P552_MY15_Gas_Rx" SG_ 958 PrmtrAlrmEvnt_D_Stat_UB 1;
BA_ "U_S550_MY15_Gas_Rx" SG_ 958 PrmtrAlrmEvnt_D_Stat_UB 1;
BA_ "U_C489_MY14_Gas_Rx" SG_ 958 PrmtrAlrmEvnt_D_Stat_UB 1;
BA_ "U_U502_MY15_Gas_Rx" SG_ 958 PrmtrAlrmEvnt_D_Stat_UB 1;
BA_ "U_CD43_MY16_Gas_Rx" SG_ 958 PrmtrAlrmEvnt_D_Stat_UB 1;
BA_ "U_CD4_MY14_Diesel_Rx" SG_ 958 PrmtrAlrmEvnt_D_Stat_UB 1;
BA_ "U_CD4_MY14_Gas_Rx" SG_ 958 PrmtrAlrmEvnt_D_Stat_UB 1;
BA_ "U_CD4_MY14_Hev_Rx" SG_ 958 PrmtrAlrmEvnt_D_Stat_UB 1;
BA_ "U_CD4_MY14_Phev_Rx" SG_ 958 PrmtrAlrmEvnt_D_Stat_UB 1;
BA_ "CrossOver_InfoCAN" SG_ 958 StopStrtDrvMde_D_Indic 1;
BA_ "GenSigSendType" SG_ 958 StopStrtDrvMde_D_Indic 3;
BA_ "U_CD4_MY13_Diesel_Rx" SG_ 958 StopStrtDrvMde_D_Indic 1;
BA_ "U_CD4_MY13_Gas_Rx" SG_ 958 StopStrtDrvMde_D_Indic 1;
BA_ "U_CD4_MY13_Hev_Rx" SG_ 958 StopStrtDrvMde_D_Indic 1;
BA_ "U_CD4_MY13_Phev_Rx" SG_ 958 StopStrtDrvMde_D_Indic 1;
BA_ "U_CD42_MY14_Diesel_Rx" SG_ 958 StopStrtDrvMde_D_Indic 1;
BA_ "U_CD42_MY14_Gas_Rx" SG_ 958 StopStrtDrvMde_D_Indic 1;
BA_ "U_P552_MY15_Gas_Rx" SG_ 958 StopStrtDrvMde_D_Indic 1;
BA_ "U_U502_MY15_Gas_Rx" SG_ 958 StopStrtDrvMde_D_Indic 1;
BA_ "U_UP375_MY15_Gas_Rx" SG_ 958 StopStrtDrvMde_D_Indic 1;
BA_ "U_UP375_MY15_Diesel_Rx" SG_ 958 StopStrtDrvMde_D_Indic 1;
BA_ "U_CD43_MY16_Gas_Rx" SG_ 958 StopStrtDrvMde_D_Indic 1;
BA_ "CrossOver_InfoCAN" SG_ 958 FuelLvl_Pc_Dsply 1;
BA_ "GenSigSendType" SG_ 958 FuelLvl_Pc_Dsply 3;
BA_ "CrossOver_InfoCAN" SG_ 958 OdometerMasterValue 1;
BA_ "GenSigSendType" SG_ 958 OdometerMasterValue 3;
BA_ "WakeupSignal" SG_ 827 SteClmnSwtchTlt_D_Stat 1;
BA_ "U_CD4_MY13_Diesel_Rx" SG_ 827 SteClmnSwtchTlt_D_Stat 1;
BA_ "U_CD4_MY13_Gas_Rx" SG_ 827 SteClmnSwtchTlt_D_Stat 1;
BA_ "U_CD4_MY13_Hev_Rx" SG_ 827 SteClmnSwtchTlt_D_Stat 1;
BA_ "U_CD4_MY13_Phev_Rx" SG_ 827 SteClmnSwtchTlt_D_Stat 1;
BA_ "U_CD42_MY14_Diesel_Rx" SG_ 827 SteClmnSwtchTlt_D_Stat 1;
BA_ "U_CD42_MY14_Gas_Rx" SG_ 827 SteClmnSwtchTlt_D_Stat 1;
BA_ "U_P552_MY15_Gas_Rx" SG_ 827 SteClmnSwtchTlt_D_Stat 1;
BA_ "U_S550_MY15_Gas_Rx" SG_ 827 SteClmnSwtchTlt_D_Stat 1;
BA_ "U_C489_MY14_Gas_Rx" SG_ 827 SteClmnSwtchTlt_D_Stat 1;
BA_ "U_U502_MY15_Gas_Rx" SG_ 827 SteClmnSwtchTlt_D_Stat 1;
BA_ "U_CD43_MY16_Gas_Rx" SG_ 827 SteClmnSwtchTlt_D_Stat 1;
BA_ "WakeupSignal" SG_ 827 SteClmnSwtchTel_D_Stat 1;
BA_ "U_CD4_MY13_Diesel_Rx" SG_ 827 SteClmnSwtchTel_D_Stat 1;
BA_ "U_CD4_MY13_Gas_Rx" SG_ 827 SteClmnSwtchTel_D_Stat 1;
BA_ "U_CD4_MY13_Hev_Rx" SG_ 827 SteClmnSwtchTel_D_Stat 1;
BA_ "U_CD4_MY13_Phev_Rx" SG_ 827 SteClmnSwtchTel_D_Stat 1;
BA_ "U_CD42_MY14_Diesel_Rx" SG_ 827 SteClmnSwtchTel_D_Stat 1;
BA_ "U_CD42_MY14_Gas_Rx" SG_ 827 SteClmnSwtchTel_D_Stat 1;
BA_ "U_P552_MY15_Gas_Rx" SG_ 827 SteClmnSwtchTel_D_Stat 1;
BA_ "U_S550_MY15_Gas_Rx" SG_ 827 SteClmnSwtchTel_D_Stat 1;
BA_ "U_C489_MY14_Gas_Rx" SG_ 827 SteClmnSwtchTel_D_Stat 1;
BA_ "U_U502_MY15_Gas_Rx" SG_ 827 SteClmnSwtchTel_D_Stat 1;
BA_ "U_CD43_MY16_Gas_Rx" SG_ 827 SteClmnSwtchTel_D_Stat 1;
BA_ "WakeupSignal" SG_ 902 PrmtrAlrmWarnRq_No_Actl 1;
BA_ "GenSigSendType" SG_ 902 PrmtrAlrmWarnRq_No_Actl 3;
BA_ "U_CD42_MY14_Diesel_Tx" SG_ 902 PrmtrAlrmWarnRq_No_Actl 1;
BA_ "U_CD42_MY14_Gas_Tx" SG_ 902 PrmtrAlrmWarnRq_No_Actl 1;
BA_ "U_P552_MY15_Gas_Tx" SG_ 902 PrmtrAlrmWarnRq_No_Actl 1;
BA_ "U_S550_MY15_Gas_Tx" SG_ 902 PrmtrAlrmWarnRq_No_Actl 1;
BA_ "U_C489_MY14_Gas_Tx" SG_ 902 PrmtrAlrmWarnRq_No_Actl 1;
BA_ "U_U502_MY15_Gas_Tx" SG_ 902 PrmtrAlrmWarnRq_No_Actl 1;
BA_ "U_CD43_MY16_Gas_Tx" SG_ 902 PrmtrAlrmWarnRq_No_Actl 1;
BA_ "U_CD4_MY14_Diesel_Tx" SG_ 902 PrmtrAlrmWarnRq_No_Actl 1;
BA_ "U_CD4_MY14_Gas_Tx" SG_ 902 PrmtrAlrmWarnRq_No_Actl 1;
BA_ "U_CD4_MY14_Hev_Tx" SG_ 902 PrmtrAlrmWarnRq_No_Actl 1;
BA_ "U_CD4_MY14_Phev_Tx" SG_ 902 PrmtrAlrmWarnRq_No_Actl 1;
BA_ "WakeupSignal" SG_ 902 PrmtrAlrmTrgRq_No_Actl 1;
BA_ "GenSigSendType" SG_ 902 PrmtrAlrmTrgRq_No_Actl 3;
BA_ "U_CD42_MY14_Diesel_Tx" SG_ 902 PrmtrAlrmTrgRq_No_Actl 1;
BA_ "U_CD42_MY14_Gas_Tx" SG_ 902 PrmtrAlrmTrgRq_No_Actl 1;
BA_ "U_P552_MY15_Gas_Tx" SG_ 902 PrmtrAlrmTrgRq_No_Actl 1;
BA_ "U_S550_MY15_Gas_Tx" SG_ 902 PrmtrAlrmTrgRq_No_Actl 1;
BA_ "U_C489_MY14_Gas_Tx" SG_ 902 PrmtrAlrmTrgRq_No_Actl 1;
BA_ "U_U502_MY15_Gas_Tx" SG_ 902 PrmtrAlrmTrgRq_No_Actl 1;
BA_ "U_CD43_MY16_Gas_Tx" SG_ 902 PrmtrAlrmTrgRq_No_Actl 1;
BA_ "U_CD4_MY14_Diesel_Tx" SG_ 902 PrmtrAlrmTrgRq_No_Actl 1;
BA_ "U_CD4_MY14_Gas_Tx" SG_ 902 PrmtrAlrmTrgRq_No_Actl 1;
BA_ "U_CD4_MY14_Hev_Tx" SG_ 902 PrmtrAlrmTrgRq_No_Actl 1;
BA_ "U_CD4_MY14_Phev_Tx" SG_ 902 PrmtrAlrmTrgRq_No_Actl 1;
BA_ "WakeupSignal" SG_ 902 Remote_Start_Req 1;
BA_ "GenSigSendType" SG_ 902 Remote_Start_Req 3;
BA_ "U_CD4_MY13_Diesel_Tx" SG_ 902 Remote_Start_Req 1;
BA_ "U_CD4_MY13_Gas_Tx" SG_ 902 Remote_Start_Req 1;
BA_ "U_CD4_MY13_Hev_Tx" SG_ 902 Remote_Start_Req 1;
BA_ "U_CD4_MY13_Phev_Tx" SG_ 902 Remote_Start_Req 1;
BA_ "U_CD42_MY14_Diesel_Tx" SG_ 902 Remote_Start_Req 1;
BA_ "U_CD42_MY14_Gas_Tx" SG_ 902 Remote_Start_Req 1;
BA_ "U_P552_MY15_Gas_Tx" SG_ 902 Remote_Start_Req 1;
BA_ "U_S550_MY15_Gas_Tx" SG_ 902 Remote_Start_Req 1;
BA_ "U_C489_MY14_Gas_Tx" SG_ 902 Remote_Start_Req 1;
BA_ "U_U502_MY15_Gas_Tx" SG_ 902 Remote_Start_Req 1;
BA_ "U_CD43_MY16_Gas_Tx" SG_ 902 Remote_Start_Req 1;
BA_ "U_CD4_MY14_Diesel_Tx" SG_ 902 Remote_Start_Req 1;
BA_ "U_CD4_MY14_Gas_Tx" SG_ 902 Remote_Start_Req 1;
BA_ "U_CD4_MY14_Hev_Tx" SG_ 902 Remote_Start_Req 1;
BA_ "U_CD4_MY14_Phev_Tx" SG_ 902 Remote_Start_Req 1;
BA_ "WakeupSignal" SG_ 902 RollCode_No_ActlRsm 1;
BA_ "GenSigSendType" SG_ 902 RollCode_No_ActlRsm 3;
BA_ "U_CD4_MY13_Diesel_Tx" SG_ 902 RollCode_No_ActlRsm 1;
BA_ "U_CD4_MY13_Gas_Tx" SG_ 902 RollCode_No_ActlRsm 1;
BA_ "U_CD4_MY13_Hev_Tx" SG_ 902 RollCode_No_ActlRsm 1;
BA_ "U_CD4_MY13_Phev_Tx" SG_ 902 RollCode_No_ActlRsm 1;
BA_ "U_CD42_MY14_Diesel_Tx" SG_ 902 RollCode_No_ActlRsm 1;
BA_ "U_CD42_MY14_Gas_Tx" SG_ 902 RollCode_No_ActlRsm 1;
BA_ "U_P552_MY15_Gas_Tx" SG_ 902 RollCode_No_ActlRsm 1;
BA_ "U_S550_MY15_Gas_Tx" SG_ 902 RollCode_No_ActlRsm 1;
BA_ "U_C489_MY14_Gas_Tx" SG_ 902 RollCode_No_ActlRsm 1;
BA_ "U_U502_MY15_Gas_Tx" SG_ 902 RollCode_No_ActlRsm 1;
BA_ "U_CD43_MY16_Gas_Tx" SG_ 902 RollCode_No_ActlRsm 1;
BA_ "U_CD4_MY14_Diesel_Tx" SG_ 902 RollCode_No_ActlRsm 1;
BA_ "U_CD4_MY14_Gas_Tx" SG_ 902 RollCode_No_ActlRsm 1;
BA_ "U_CD4_MY14_Hev_Tx" SG_ 902 RollCode_No_ActlRsm 1;
BA_ "U_CD4_MY14_Phev_Tx" SG_ 902 RollCode_No_ActlRsm 1;
BA_ "WakeupSignal" SG_ 902 PrmtrAlrmWarn_B_Rq 1;
BA_ "GenSigSendType" SG_ 902 PrmtrAlrmWarn_B_Rq 3;
BA_ "U_CD4_MY13_Diesel_Tx" SG_ 902 PrmtrAlrmWarn_B_Rq 1;
BA_ "U_CD4_MY13_Gas_Tx" SG_ 902 PrmtrAlrmWarn_B_Rq 1;
BA_ "U_CD4_MY13_Hev_Tx" SG_ 902 PrmtrAlrmWarn_B_Rq 1;
BA_ "U_CD4_MY13_Phev_Tx" SG_ 902 PrmtrAlrmWarn_B_Rq 1;
BA_ "U_CD42_MY14_Diesel_Tx" SG_ 902 PrmtrAlrmWarn_B_Rq 1;
BA_ "U_CD42_MY14_Gas_Tx" SG_ 902 PrmtrAlrmWarn_B_Rq 1;
BA_ "U_P552_MY15_Gas_Tx" SG_ 902 PrmtrAlrmWarn_B_Rq 1;
BA_ "U_S550_MY15_Gas_Tx" SG_ 902 PrmtrAlrmWarn_B_Rq 1;
BA_ "U_C489_MY14_Gas_Tx" SG_ 902 PrmtrAlrmWarn_B_Rq 1;
BA_ "U_U502_MY15_Gas_Tx" SG_ 902 PrmtrAlrmWarn_B_Rq 1;
BA_ "U_CD43_MY16_Gas_Tx" SG_ 902 PrmtrAlrmWarn_B_Rq 1;
BA_ "U_CD4_MY14_Diesel_Tx" SG_ 902 PrmtrAlrmWarn_B_Rq 1;
BA_ "U_CD4_MY14_Gas_Tx" SG_ 902 PrmtrAlrmWarn_B_Rq 1;
BA_ "U_CD4_MY14_Hev_Tx" SG_ 902 PrmtrAlrmWarn_B_Rq 1;
BA_ "U_CD4_MY14_Phev_Tx" SG_ 902 PrmtrAlrmWarn_B_Rq 1;
BA_ "WakeupSignal" SG_ 902 PrmtrAlrmTrg_B_Rq 1;
BA_ "GenSigSendType" SG_ 902 PrmtrAlrmTrg_B_Rq 3;
BA_ "U_CD4_MY13_Diesel_Tx" SG_ 902 PrmtrAlrmTrg_B_Rq 1;
BA_ "U_CD4_MY13_Gas_Tx" SG_ 902 PrmtrAlrmTrg_B_Rq 1;
BA_ "U_CD4_MY13_Hev_Tx" SG_ 902 PrmtrAlrmTrg_B_Rq 1;
BA_ "U_CD4_MY13_Phev_Tx" SG_ 902 PrmtrAlrmTrg_B_Rq 1;
BA_ "U_CD42_MY14_Diesel_Tx" SG_ 902 PrmtrAlrmTrg_B_Rq 1;
BA_ "U_CD42_MY14_Gas_Tx" SG_ 902 PrmtrAlrmTrg_B_Rq 1;
BA_ "U_P552_MY15_Gas_Tx" SG_ 902 PrmtrAlrmTrg_B_Rq 1;
BA_ "U_S550_MY15_Gas_Tx" SG_ 902 PrmtrAlrmTrg_B_Rq 1;
BA_ "U_C489_MY14_Gas_Tx" SG_ 902 PrmtrAlrmTrg_B_Rq 1;
BA_ "U_U502_MY15_Gas_Tx" SG_ 902 PrmtrAlrmTrg_B_Rq 1;
BA_ "U_CD43_MY16_Gas_Tx" SG_ 902 PrmtrAlrmTrg_B_Rq 1;
BA_ "U_CD4_MY14_Diesel_Tx" SG_ 902 PrmtrAlrmTrg_B_Rq 1;
BA_ "U_CD4_MY14_Gas_Tx" SG_ 902 PrmtrAlrmTrg_B_Rq 1;
BA_ "U_CD4_MY14_Hev_Tx" SG_ 902 PrmtrAlrmTrg_B_Rq 1;
BA_ "U_CD4_MY14_Phev_Tx" SG_ 902 PrmtrAlrmTrg_B_Rq 1;
BA_ "WakeupSignal" SG_ 902 PanicRq_No_ActlRsm 1;
BA_ "GenSigSendType" SG_ 902 PanicRq_No_ActlRsm 3;
BA_ "U_CD4_MY13_Diesel_Tx" SG_ 902 PanicRq_No_ActlRsm 1;
BA_ "U_CD4_MY13_Gas_Tx" SG_ 902 PanicRq_No_ActlRsm 1;
BA_ "U_CD4_MY13_Hev_Tx" SG_ 902 PanicRq_No_ActlRsm 1;
BA_ "U_CD4_MY13_Phev_Tx" SG_ 902 PanicRq_No_ActlRsm 1;
BA_ "U_CD42_MY14_Diesel_Tx" SG_ 902 PanicRq_No_ActlRsm 1;
BA_ "U_CD42_MY14_Gas_Tx" SG_ 902 PanicRq_No_ActlRsm 1;
BA_ "U_P552_MY15_Gas_Tx" SG_ 902 PanicRq_No_ActlRsm 1;
BA_ "U_S550_MY15_Gas_Tx" SG_ 902 PanicRq_No_ActlRsm 1;
BA_ "U_C489_MY14_Gas_Tx" SG_ 902 PanicRq_No_ActlRsm 1;
BA_ "U_U502_MY15_Gas_Tx" SG_ 902 PanicRq_No_ActlRsm 1;
BA_ "U_CD43_MY16_Gas_Tx" SG_ 902 PanicRq_No_ActlRsm 1;
BA_ "U_CD4_MY14_Diesel_Tx" SG_ 902 PanicRq_No_ActlRsm 1;
BA_ "U_CD4_MY14_Gas_Tx" SG_ 902 PanicRq_No_ActlRsm 1;
BA_ "U_CD4_MY14_Hev_Tx" SG_ 902 PanicRq_No_ActlRsm 1;
BA_ "U_CD4_MY14_Phev_Tx" SG_ 902 PanicRq_No_ActlRsm 1;
BA_ "WakeupSignal" SG_ 902 Panic_D_RqRsm 1;
BA_ "GenSigSendType" SG_ 902 Panic_D_RqRsm 3;
BA_ "U_CD4_MY13_Diesel_Tx" SG_ 902 Panic_D_RqRsm 1;
BA_ "U_CD4_MY13_Gas_Tx" SG_ 902 Panic_D_RqRsm 1;
BA_ "U_CD4_MY13_Hev_Tx" SG_ 902 Panic_D_RqRsm 1;
BA_ "U_CD4_MY13_Phev_Tx" SG_ 902 Panic_D_RqRsm 1;
BA_ "U_CD42_MY14_Diesel_Tx" SG_ 902 Panic_D_RqRsm 1;
BA_ "U_CD42_MY14_Gas_Tx" SG_ 902 Panic_D_RqRsm 1;
BA_ "U_P552_MY15_Gas_Tx" SG_ 902 Panic_D_RqRsm 1;
BA_ "U_S550_MY15_Gas_Tx" SG_ 902 Panic_D_RqRsm 1;
BA_ "U_C489_MY14_Gas_Tx" SG_ 902 Panic_D_RqRsm 1;
BA_ "U_U502_MY15_Gas_Tx" SG_ 902 Panic_D_RqRsm 1;
BA_ "U_CD43_MY16_Gas_Tx" SG_ 902 Panic_D_RqRsm 1;
BA_ "U_CD4_MY14_Diesel_Tx" SG_ 902 Panic_D_RqRsm 1;
BA_ "U_CD4_MY14_Gas_Tx" SG_ 902 Panic_D_RqRsm 1;
BA_ "U_CD4_MY14_Hev_Tx" SG_ 902 Panic_D_RqRsm 1;
BA_ "U_CD4_MY14_Phev_Tx" SG_ 902 Panic_D_RqRsm 1;
BA_ "WakeupSignal" SG_ 902 CellLockRq_No_ActlRsm 1;
BA_ "GenSigSendType" SG_ 902 CellLockRq_No_ActlRsm 3;
BA_ "U_CD4_MY13_Diesel_Tx" SG_ 902 CellLockRq_No_ActlRsm 1;
BA_ "U_CD4_MY13_Gas_Tx" SG_ 902 CellLockRq_No_ActlRsm 1;
BA_ "U_CD4_MY13_Hev_Tx" SG_ 902 CellLockRq_No_ActlRsm 1;
BA_ "U_CD4_MY13_Phev_Tx" SG_ 902 CellLockRq_No_ActlRsm 1;
BA_ "U_CD42_MY14_Diesel_Tx" SG_ 902 CellLockRq_No_ActlRsm 1;
BA_ "U_CD42_MY14_Gas_Tx" SG_ 902 CellLockRq_No_ActlRsm 1;
BA_ "U_P552_MY15_Gas_Tx" SG_ 902 CellLockRq_No_ActlRsm 1;
BA_ "U_S550_MY15_Gas_Tx" SG_ 902 CellLockRq_No_ActlRsm 1;
BA_ "U_C489_MY14_Gas_Tx" SG_ 902 CellLockRq_No_ActlRsm 1;
BA_ "U_U502_MY15_Gas_Tx" SG_ 902 CellLockRq_No_ActlRsm 1;
BA_ "U_CD43_MY16_Gas_Tx" SG_ 902 CellLockRq_No_ActlRsm 1;
BA_ "U_CD4_MY14_Diesel_Tx" SG_ 902 CellLockRq_No_ActlRsm 1;
BA_ "U_CD4_MY14_Gas_Tx" SG_ 902 CellLockRq_No_ActlRsm 1;
BA_ "U_CD4_MY14_Hev_Tx" SG_ 902 CellLockRq_No_ActlRsm 1;
BA_ "U_CD4_MY14_Phev_Tx" SG_ 902 CellLockRq_No_ActlRsm 1;
BA_ "WakeupSignal" SG_ 902 CellLock_D_RqRsm 1;
BA_ "GenSigSendType" SG_ 902 CellLock_D_RqRsm 3;
BA_ "U_CD4_MY13_Diesel_Tx" SG_ 902 CellLock_D_RqRsm 1;
BA_ "U_CD4_MY13_Gas_Tx" SG_ 902 CellLock_D_RqRsm 1;
BA_ "U_CD4_MY13_Hev_Tx" SG_ 902 CellLock_D_RqRsm 1;
BA_ "U_CD4_MY13_Phev_Tx" SG_ 902 CellLock_D_RqRsm 1;
BA_ "U_CD42_MY14_Diesel_Tx" SG_ 902 CellLock_D_RqRsm 1;
BA_ "U_CD42_MY14_Gas_Tx" SG_ 902 CellLock_D_RqRsm 1;
BA_ "U_P552_MY15_Gas_Tx" SG_ 902 CellLock_D_RqRsm 1;
BA_ "U_S550_MY15_Gas_Tx" SG_ 902 CellLock_D_RqRsm 1;
BA_ "U_C489_MY14_Gas_Tx" SG_ 902 CellLock_D_RqRsm 1;
BA_ "U_U502_MY15_Gas_Tx" SG_ 902 CellLock_D_RqRsm 1;
BA_ "U_CD43_MY16_Gas_Tx" SG_ 902 CellLock_D_RqRsm 1;
BA_ "U_CD4_MY14_Diesel_Tx" SG_ 902 CellLock_D_RqRsm 1;
BA_ "U_CD4_MY14_Gas_Tx" SG_ 902 CellLock_D_RqRsm 1;
BA_ "U_CD4_MY14_Hev_Tx" SG_ 902 CellLock_D_RqRsm 1;
BA_ "U_CD4_MY14_Phev_Tx" SG_ 902 CellLock_D_RqRsm 1;
BA_ "U_U55x_MY18_Gas_Rx" SG_ 765 EmPrflButtnAssoc_D_Rq 1;
BA_ "GenSigSendType" SG_ 765 EmPrflButtnAssoc_D_Rq 3;
BA_ "U_U502_MY16_Gas_Rx" SG_ 765 ValetMode_D_Stat_UB 1;
BA_ "U_CD42_MY16_Diesel_Rx" SG_ 765 ValetMode_D_Stat_UB 1;
BA_ "U_CD42_MY16_Gas_Rx" SG_ 765 ValetMode_D_Stat_UB 1;
BA_ "GenSigSendType" SG_ 765 ValetMode_D_Stat 3;
BA_ "CrossOver_InfoCAN" SG_ 765 ValetMode_D_Stat 1;
BA_ "U_U502_MY16_Gas_Rx" SG_ 765 ValetMode_D_Stat 1;
BA_ "U_CD42_MY16_Diesel_Rx" SG_ 765 ValetMode_D_Stat 1;
BA_ "U_CD42_MY16_Gas_Rx" SG_ 765 ValetMode_D_Stat 1;
BA_ "U_P558_MY17_Diesel_Rx" SG_ 765 TrlrBrkActCnnct_B_Actl_UB 1;
BA_ "U_P558_MY17_Gas_Rx" SG_ 765 TrlrBrkActCnnct_B_Actl_UB 1;
BA_ "GenSigSendType" SG_ 765 TrlrBrkActCnnct_B_Actl 3;
BA_ "U_P558_MY17_Diesel_Rx" SG_ 765 TrlrBrkActCnnct_B_Actl 1;
BA_ "U_P558_MY17_Gas_Rx" SG_ 765 TrlrBrkActCnnct_B_Actl 1;
BA_ "U_P552_MY17_Gas_Rx" SG_ 765 TrlrAidMsgTxt_D_Rq 1;
BA_ "GenSigSendType" SG_ 765 TrlrAidMsgTxt_D_Rq 3;
BA_ "U_P558_MY17_Diesel_Rx" SG_ 765 Voice_Blower_Limit_UB 1;
BA_ "U_P558_MY17_Gas_Rx" SG_ 765 Voice_Blower_Limit_UB 1;
BA_ "U_CD43_MY16_Gas_Rx" SG_ 765 Voice_Blower_Limit_UB 1;
BA_ "U_UP375_MY15_Diesel_Rx" SG_ 765 Voice_Blower_Limit_UB 1;
BA_ "U_UP375_MY15_Gas_Rx" SG_ 765 Voice_Blower_Limit_UB 1;
BA_ "U_S550_MY15_Gas_Rx" SG_ 765 Voice_Blower_Limit_UB 1;
BA_ "U_CD42_MY15_Gas_Rx" SG_ 765 Voice_Blower_Limit_UB 1;
BA_ "U_CD42_MY15_Diesel_Rx" SG_ 765 Voice_Blower_Limit_UB 1;
BA_ "U_CD4_MY13_Phev_Rx" SG_ 765 Voice_Blower_Limit_UB 1;
BA_ "U_CD4_MY13_Hev_Rx" SG_ 765 Voice_Blower_Limit_UB 1;
BA_ "U_CD4_MY13_Gas_Rx" SG_ 765 Voice_Blower_Limit_UB 1;
BA_ "U_CD4_MY13_Diesel_Rx" SG_ 765 Voice_Blower_Limit_UB 1;
BA_ "CrossOver_InfoCAN" SG_ 765 Voice_Blower_Limit_UB 1;
BA_ "CrossOver_InfoCAN" SG_ 765 Voice_Blower_Limit 1;
BA_ "U_CD4_MY13_Diesel_Rx" SG_ 765 Voice_Blower_Limit 1;
BA_ "U_CD4_MY13_Gas_Rx" SG_ 765 Voice_Blower_Limit 1;
BA_ "U_CD4_MY13_Hev_Rx" SG_ 765 Voice_Blower_Limit 1;
BA_ "U_CD4_MY13_Phev_Rx" SG_ 765 Voice_Blower_Limit 1;
BA_ "U_CD42_MY14_Diesel_Rx" SG_ 765 Voice_Blower_Limit 1;
BA_ "U_CD42_MY14_Gas_Rx" SG_ 765 Voice_Blower_Limit 1;
BA_ "U_P552_MY15_Gas_Rx" SG_ 765 Voice_Blower_Limit 1;
BA_ "U_S550_MY15_Gas_Rx" SG_ 765 Voice_Blower_Limit 1;
BA_ "U_C489_MY14_Gas_Rx" SG_ 765 Voice_Blower_Limit 1;
BA_ "U_U502_MY15_Gas_Rx" SG_ 765 Voice_Blower_Limit 1;
BA_ "U_UP375_MY15_Gas_Rx" SG_ 765 Voice_Blower_Limit 1;
BA_ "U_UP375_MY15_Diesel_Rx" SG_ 765 Voice_Blower_Limit 1;
BA_ "U_CD43_MY16_Gas_Rx" SG_ 765 Voice_Blower_Limit 1;
BA_ "U_P558_MY17_Diesel_Rx" SG_ 765 Voice_Blower_Limit 1;
BA_ "U_P558_MY17_Gas_Rx" SG_ 765 Voice_Blower_Limit 1;
BA_ "U_CD42_MY15_Gas_Rx" SG_ 765 Voice_Blower_Limit 1;
BA_ "U_CD42_MY15_Diesel_Rx" SG_ 765 Voice_Blower_Limit 1;
BA_ "GenSigSendType" SG_ 765 Voice_Blower_Limit 3;
BA_ "GenSigSendType" SG_ 765 CamraFrntStat_D_Stat 3;
BA_ "GenSigSendType" SG_ 765 SteWhlHeat_D_Stat 3;
BA_ "U_CD4_MY13_Diesel_Rx" SG_ 765 SteWhlHeat_D_Stat 1;
BA_ "U_CD4_MY13_Gas_Rx" SG_ 765 SteWhlHeat_D_Stat 1;
BA_ "U_CD4_MY13_Hev_Rx" SG_ 765 SteWhlHeat_D_Stat 1;
BA_ "U_CD4_MY13_Phev_Rx" SG_ 765 SteWhlHeat_D_Stat 1;
BA_ "U_CD42_MY14_Diesel_Rx" SG_ 765 SteWhlHeat_D_Stat 1;
BA_ "U_CD42_MY14_Gas_Rx" SG_ 765 SteWhlHeat_D_Stat 1;
BA_ "U_P552_MY15_Gas_Rx" SG_ 765 SteWhlHeat_D_Stat 1;
BA_ "U_C489_MY14_Gas_Rx" SG_ 765 SteWhlHeat_D_Stat 1;
BA_ "U_UP375_MY15_Gas_Rx" SG_ 765 SteWhlHeat_D_Stat 1;
BA_ "U_UP375_MY15_Diesel_Rx" SG_ 765 SteWhlHeat_D_Stat 1;
BA_ "U_CD43_MY16_Gas_Rx" SG_ 765 SteWhlHeat_D_Stat 1;
BA_ "U_CD4_MY13_Diesel_Tx" SG_ 765 SteWhlHeat_D_Stat 1;
BA_ "U_CD4_MY13_Gas_Tx" SG_ 765 SteWhlHeat_D_Stat 1;
BA_ "U_CD4_MY13_Hev_Tx" SG_ 765 SteWhlHeat_D_Stat 1;
BA_ "U_CD4_MY13_Phev_Tx" SG_ 765 SteWhlHeat_D_Stat 1;
BA_ "U_CD42_MY14_Diesel_Tx" SG_ 765 SteWhlHeat_D_Stat 1;
BA_ "U_CD42_MY14_Gas_Tx" SG_ 765 SteWhlHeat_D_Stat 1;
BA_ "U_P552_MY15_Gas_Tx" SG_ 765 SteWhlHeat_D_Stat 1;
BA_ "U_C489_MY14_Gas_Tx" SG_ 765 SteWhlHeat_D_Stat 1;
BA_ "U_U502_MY15_Gas_Tx" SG_ 765 SteWhlHeat_D_Stat 1;
BA_ "U_CD43_MY16_Gas_Tx" SG_ 765 SteWhlHeat_D_Stat 1;
BA_ "U_P552_MY15_Gas_Rx" SG_ 765 Running_Board_Cmd_UB 1;
BA_ "GenSigSendType" SG_ 765 Running_Board_Cmd 3;
BA_ "U_P552_MY15_Gas_Rx" SG_ 765 Running_Board_Cmd 1;
BA_ "U_CD4_MY13_Diesel_Rx" SG_ 765 Bezel_Beeps_Rq_UB 1;
BA_ "U_CD4_MY13_Gas_Rx" SG_ 765 Bezel_Beeps_Rq_UB 1;
BA_ "U_CD4_MY13_Hev_Rx" SG_ 765 Bezel_Beeps_Rq_UB 1;
BA_ "U_CD4_MY13_Phev_Rx" SG_ 765 Bezel_Beeps_Rq_UB 1;
BA_ "U_CD42_MY14_Diesel_Rx" SG_ 765 Bezel_Beeps_Rq_UB 1;
BA_ "U_CD42_MY14_Gas_Rx" SG_ 765 Bezel_Beeps_Rq_UB 1;
BA_ "U_P552_MY15_Gas_Rx" SG_ 765 Bezel_Beeps_Rq_UB 1;
BA_ "U_S550_MY15_Gas_Rx" SG_ 765 Bezel_Beeps_Rq_UB 1;
BA_ "U_C489_MY14_Gas_Rx" SG_ 765 Bezel_Beeps_Rq_UB 1;
BA_ "U_U502_MY15_Gas_Rx" SG_ 765 Bezel_Beeps_Rq_UB 1;
BA_ "U_UP375_MY15_Gas_Rx" SG_ 765 Bezel_Beeps_Rq_UB 1;
BA_ "U_UP375_MY15_Diesel_Rx" SG_ 765 Bezel_Beeps_Rq_UB 1;
BA_ "U_CD43_MY16_Gas_Rx" SG_ 765 Bezel_Beeps_Rq_UB 1;
BA_ "WakeupSignal" SG_ 765 Bezel_Beeps_Rq 1;
BA_ "CrossOver_InfoCAN" SG_ 765 Bezel_Beeps_Rq 1;
BA_ "GenSigSendType" SG_ 765 Bezel_Beeps_Rq 3;
BA_ "U_CD4_MY13_Diesel_Rx" SG_ 765 Bezel_Beeps_Rq 1;
BA_ "U_CD4_MY13_Gas_Rx" SG_ 765 Bezel_Beeps_Rq 1;
BA_ "U_CD4_MY13_Hev_Rx" SG_ 765 Bezel_Beeps_Rq 1;
BA_ "U_CD4_MY13_Phev_Rx" SG_ 765 Bezel_Beeps_Rq 1;
BA_ "U_CD42_MY14_Diesel_Rx" SG_ 765 Bezel_Beeps_Rq 1;
BA_ "U_CD42_MY14_Gas_Rx" SG_ 765 Bezel_Beeps_Rq 1;
BA_ "U_P552_MY15_Gas_Rx" SG_ 765 Bezel_Beeps_Rq 1;
BA_ "U_S550_MY15_Gas_Rx" SG_ 765 Bezel_Beeps_Rq 1;
BA_ "U_C489_MY14_Gas_Rx" SG_ 765 Bezel_Beeps_Rq 1;
BA_ "U_U502_MY15_Gas_Rx" SG_ 765 Bezel_Beeps_Rq 1;
BA_ "U_UP375_MY15_Gas_Rx" SG_ 765 Bezel_Beeps_Rq 1;
BA_ "U_UP375_MY15_Diesel_Rx" SG_ 765 Bezel_Beeps_Rq 1;
BA_ "U_CD43_MY16_Gas_Rx" SG_ 765 Bezel_Beeps_Rq 1;
BA_ "U_CD4_MY13_Diesel_Rx" SG_ 765 Diagnostic_Operation_Rq_UB 1;
BA_ "U_CD4_MY13_Gas_Rx" SG_ 765 Diagnostic_Operation_Rq_UB 1;
BA_ "U_CD4_MY13_Hev_Rx" SG_ 765 Diagnostic_Operation_Rq_UB 1;
BA_ "U_CD4_MY13_Phev_Rx" SG_ 765 Diagnostic_Operation_Rq_UB 1;
BA_ "U_CD42_MY14_Diesel_Rx" SG_ 765 Diagnostic_Operation_Rq_UB 1;
BA_ "U_CD42_MY14_Gas_Rx" SG_ 765 Diagnostic_Operation_Rq_UB 1;
BA_ "U_P552_MY15_Gas_Rx" SG_ 765 Diagnostic_Operation_Rq_UB 1;
BA_ "U_S550_MY15_Gas_Rx" SG_ 765 Diagnostic_Operation_Rq_UB 1;
BA_ "U_C489_MY14_Gas_Rx" SG_ 765 Diagnostic_Operation_Rq_UB 1;
BA_ "U_U502_MY15_Gas_Rx" SG_ 765 Diagnostic_Operation_Rq_UB 1;
BA_ "U_UP375_MY15_Gas_Rx" SG_ 765 Diagnostic_Operation_Rq_UB 1;
BA_ "U_UP375_MY15_Diesel_Rx" SG_ 765 Diagnostic_Operation_Rq_UB 1;
BA_ "U_CD43_MY16_Gas_Rx" SG_ 765 Diagnostic_Operation_Rq_UB 1;
BA_ "U_CD4_MY13_Diesel_Rx" SG_ 765 Bezel_Diag_State_Rq_UB 1;
BA_ "U_CD4_MY13_Gas_Rx" SG_ 765 Bezel_Diag_State_Rq_UB 1;
BA_ "U_CD4_MY13_Hev_Rx" SG_ 765 Bezel_Diag_State_Rq_UB 1;
BA_ "U_CD4_MY13_Phev_Rx" SG_ 765 Bezel_Diag_State_Rq_UB 1;
BA_ "U_CD42_MY14_Diesel_Rx" SG_ 765 Bezel_Diag_State_Rq_UB 1;
BA_ "U_CD42_MY14_Gas_Rx" SG_ 765 Bezel_Diag_State_Rq_UB 1;
BA_ "U_P552_MY15_Gas_Rx" SG_ 765 Bezel_Diag_State_Rq_UB 1;
BA_ "U_S550_MY15_Gas_Rx" SG_ 765 Bezel_Diag_State_Rq_UB 1;
BA_ "U_C489_MY14_Gas_Rx" SG_ 765 Bezel_Diag_State_Rq_UB 1;
BA_ "U_U502_MY15_Gas_Rx" SG_ 765 Bezel_Diag_State_Rq_UB 1;
BA_ "U_UP375_MY15_Gas_Rx" SG_ 765 Bezel_Diag_State_Rq_UB 1;
BA_ "U_UP375_MY15_Diesel_Rx" SG_ 765 Bezel_Diag_State_Rq_UB 1;
BA_ "U_CD43_MY16_Gas_Rx" SG_ 765 Bezel_Diag_State_Rq_UB 1;
BA_ "U_CD4_MY13_Diesel_Rx" SG_ 765 Bezel_Diag_Module_Rq_UB 1;
BA_ "U_CD4_MY13_Gas_Rx" SG_ 765 Bezel_Diag_Module_Rq_UB 1;
BA_ "U_CD4_MY13_Hev_Rx" SG_ 765 Bezel_Diag_Module_Rq_UB 1;
BA_ "U_CD4_MY13_Phev_Rx" SG_ 765 Bezel_Diag_Module_Rq_UB 1;
BA_ "U_CD42_MY14_Diesel_Rx" SG_ 765 Bezel_Diag_Module_Rq_UB 1;
BA_ "U_CD42_MY14_Gas_Rx" SG_ 765 Bezel_Diag_Module_Rq_UB 1;
BA_ "U_P552_MY15_Gas_Rx" SG_ 765 Bezel_Diag_Module_Rq_UB 1;
BA_ "U_S550_MY15_Gas_Rx" SG_ 765 Bezel_Diag_Module_Rq_UB 1;
BA_ "U_C489_MY14_Gas_Rx" SG_ 765 Bezel_Diag_Module_Rq_UB 1;
BA_ "U_U502_MY15_Gas_Rx" SG_ 765 Bezel_Diag_Module_Rq_UB 1;
BA_ "U_UP375_MY15_Gas_Rx" SG_ 765 Bezel_Diag_Module_Rq_UB 1;
BA_ "U_UP375_MY15_Diesel_Rx" SG_ 765 Bezel_Diag_Module_Rq_UB 1;
BA_ "U_CD43_MY16_Gas_Rx" SG_ 765 Bezel_Diag_Module_Rq_UB 1;
BA_ "CrossOver_InfoCAN" SG_ 765 Diagnostic_Operation_Rq 1;
BA_ "GenSigSendType" SG_ 765 Diagnostic_Operation_Rq 3;
BA_ "U_CD4_MY13_Diesel_Rx" SG_ 765 Diagnostic_Operation_Rq 1;
BA_ "U_CD4_MY13_Gas_Rx" SG_ 765 Diagnostic_Operation_Rq 1;
BA_ "U_CD4_MY13_Hev_Rx" SG_ 765 Diagnostic_Operation_Rq 1;
BA_ "U_CD4_MY13_Phev_Rx" SG_ 765 Diagnostic_Operation_Rq 1;
BA_ "U_CD42_MY14_Diesel_Rx" SG_ 765 Diagnostic_Operation_Rq 1;
BA_ "U_CD42_MY14_Gas_Rx" SG_ 765 Diagnostic_Operation_Rq 1;
BA_ "U_P552_MY15_Gas_Rx" SG_ 765 Diagnostic_Operation_Rq 1;
BA_ "U_S550_MY15_Gas_Rx" SG_ 765 Diagnostic_Operation_Rq 1;
BA_ "U_C489_MY14_Gas_Rx" SG_ 765 Diagnostic_Operation_Rq 1;
BA_ "U_U502_MY15_Gas_Rx" SG_ 765 Diagnostic_Operation_Rq 1;
BA_ "U_UP375_MY15_Gas_Rx" SG_ 765 Diagnostic_Operation_Rq 1;
BA_ "U_UP375_MY15_Diesel_Rx" SG_ 765 Diagnostic_Operation_Rq 1;
BA_ "U_CD43_MY16_Gas_Rx" SG_ 765 Diagnostic_Operation_Rq 1;
BA_ "CrossOver_InfoCAN" SG_ 765 Bezel_Diag_State_Rq 1;
BA_ "GenSigSendType" SG_ 765 Bezel_Diag_State_Rq 3;
BA_ "U_CD4_MY13_Diesel_Rx" SG_ 765 Bezel_Diag_State_Rq 1;
BA_ "U_CD4_MY13_Gas_Rx" SG_ 765 Bezel_Diag_State_Rq 1;
BA_ "U_CD4_MY13_Hev_Rx" SG_ 765 Bezel_Diag_State_Rq 1;
BA_ "U_CD4_MY13_Phev_Rx" SG_ 765 Bezel_Diag_State_Rq 1;
BA_ "U_CD42_MY14_Diesel_Rx" SG_ 765 Bezel_Diag_State_Rq 1;
BA_ "U_CD42_MY14_Gas_Rx" SG_ 765 Bezel_Diag_State_Rq 1;
BA_ "U_P552_MY15_Gas_Rx" SG_ 765 Bezel_Diag_State_Rq 1;
BA_ "U_S550_MY15_Gas_Rx" SG_ 765 Bezel_Diag_State_Rq 1;
BA_ "U_C489_MY14_Gas_Rx" SG_ 765 Bezel_Diag_State_Rq 1;
BA_ "U_U502_MY15_Gas_Rx" SG_ 765 Bezel_Diag_State_Rq 1;
BA_ "U_UP375_MY15_Gas_Rx" SG_ 765 Bezel_Diag_State_Rq 1;
BA_ "U_UP375_MY15_Diesel_Rx" SG_ 765 Bezel_Diag_State_Rq 1;
BA_ "U_CD43_MY16_Gas_Rx" SG_ 765 Bezel_Diag_State_Rq 1;
BA_ "CrossOver_InfoCAN" SG_ 765 Bezel_Diag_Module_Rq 1;
BA_ "GenSigSendType" SG_ 765 Bezel_Diag_Module_Rq 3;
BA_ "U_CD4_MY13_Diesel_Rx" SG_ 765 Bezel_Diag_Module_Rq 1;
BA_ "U_CD4_MY13_Gas_Rx" SG_ 765 Bezel_Diag_Module_Rq 1;
BA_ "U_CD4_MY13_Hev_Rx" SG_ 765 Bezel_Diag_Module_Rq 1;
BA_ "U_CD4_MY13_Phev_Rx" SG_ 765 Bezel_Diag_Module_Rq 1;
BA_ "U_CD42_MY14_Diesel_Rx" SG_ 765 Bezel_Diag_Module_Rq 1;
BA_ "U_CD42_MY14_Gas_Rx" SG_ 765 Bezel_Diag_Module_Rq 1;
BA_ "U_P552_MY15_Gas_Rx" SG_ 765 Bezel_Diag_Module_Rq 1;
BA_ "U_S550_MY15_Gas_Rx" SG_ 765 Bezel_Diag_Module_Rq 1;
BA_ "U_C489_MY14_Gas_Rx" SG_ 765 Bezel_Diag_Module_Rq 1;
BA_ "U_U502_MY15_Gas_Rx" SG_ 765 Bezel_Diag_Module_Rq 1;
BA_ "U_UP375_MY15_Gas_Rx" SG_ 765 Bezel_Diag_Module_Rq 1;
BA_ "U_UP375_MY15_Diesel_Rx" SG_ 765 Bezel_Diag_Module_Rq 1;
BA_ "U_CD43_MY16_Gas_Rx" SG_ 765 Bezel_Diag_Module_Rq 1;
BA_ "U_CD4_MY13_Diesel_Rx" SG_ 765 HMI_HMIMode_St_UB 1;
BA_ "U_CD4_MY13_Gas_Rx" SG_ 765 HMI_HMIMode_St_UB 1;
BA_ "U_CD4_MY13_Hev_Rx" SG_ 765 HMI_HMIMode_St_UB 1;
BA_ "U_CD4_MY13_Phev_Rx" SG_ 765 HMI_HMIMode_St_UB 1;
BA_ "U_CD42_MY14_Diesel_Rx" SG_ 765 HMI_HMIMode_St_UB 1;
BA_ "U_CD42_MY14_Gas_Rx" SG_ 765 HMI_HMIMode_St_UB 1;
BA_ "U_P552_MY15_Gas_Rx" SG_ 765 HMI_HMIMode_St_UB 1;
BA_ "U_S550_MY15_Gas_Rx" SG_ 765 HMI_HMIMode_St_UB 1;
BA_ "U_C489_MY14_Gas_Rx" SG_ 765 HMI_HMIMode_St_UB 1;
BA_ "U_U502_MY15_Gas_Rx" SG_ 765 HMI_HMIMode_St_UB 1;
BA_ "U_UP375_MY15_Gas_Rx" SG_ 765 HMI_HMIMode_St_UB 1;
BA_ "U_UP375_MY15_Diesel_Rx" SG_ 765 HMI_HMIMode_St_UB 1;
BA_ "U_CD43_MY16_Gas_Rx" SG_ 765 HMI_HMIMode_St_UB 1;
BA_ "CrossOver_InfoCAN" SG_ 765 HMI_HMIMode_St 1;
BA_ "GenSigSendType" SG_ 765 HMI_HMIMode_St 3;
BA_ "U_CD4_MY13_Diesel_Rx" SG_ 765 HMI_HMIMode_St 1;
BA_ "U_CD4_MY13_Gas_Rx" SG_ 765 HMI_HMIMode_St 1;
BA_ "U_CD4_MY13_Hev_Rx" SG_ 765 HMI_HMIMode_St 1;
BA_ "U_CD4_MY13_Phev_Rx" SG_ 765 HMI_HMIMode_St 1;
BA_ "U_CD42_MY14_Diesel_Rx" SG_ 765 HMI_HMIMode_St 1;
BA_ "U_CD42_MY14_Gas_Rx" SG_ 765 HMI_HMIMode_St 1;
BA_ "U_P552_MY15_Gas_Rx" SG_ 765 HMI_HMIMode_St 1;
BA_ "U_S550_MY15_Gas_Rx" SG_ 765 HMI_HMIMode_St 1;
BA_ "U_C489_MY14_Gas_Rx" SG_ 765 HMI_HMIMode_St 1;
BA_ "U_U502_MY15_Gas_Rx" SG_ 765 HMI_HMIMode_St 1;
BA_ "U_UP375_MY15_Gas_Rx" SG_ 765 HMI_HMIMode_St 1;
BA_ "U_UP375_MY15_Diesel_Rx" SG_ 765 HMI_HMIMode_St 1;
BA_ "U_CD43_MY16_Gas_Rx" SG_ 765 HMI_HMIMode_St 1;
BA_ "U_CD4_MY13_Diesel_Rx" SG_ 765 Mc_VehUnitTempUsrSel_St_UB 1;
BA_ "U_CD4_MY13_Gas_Rx" SG_ 765 Mc_VehUnitTempUsrSel_St_UB 1;
BA_ "U_CD4_MY13_Hev_Rx" SG_ 765 Mc_VehUnitTempUsrSel_St_UB 1;
BA_ "U_CD4_MY13_Phev_Rx" SG_ 765 Mc_VehUnitTempUsrSel_St_UB 1;
BA_ "U_CD42_MY14_Diesel_Rx" SG_ 765 Mc_VehUnitTempUsrSel_St_UB 1;
BA_ "U_CD42_MY14_Gas_Rx" SG_ 765 Mc_VehUnitTempUsrSel_St_UB 1;
BA_ "U_P552_MY15_Gas_Rx" SG_ 765 Mc_VehUnitTempUsrSel_St_UB 1;
BA_ "U_S550_MY15_Gas_Rx" SG_ 765 Mc_VehUnitTempUsrSel_St_UB 1;
BA_ "U_C489_MY14_Gas_Rx" SG_ 765 Mc_VehUnitTempUsrSel_St_UB 1;
BA_ "U_U502_MY15_Gas_Rx" SG_ 765 Mc_VehUnitTempUsrSel_St_UB 1;
BA_ "U_UP375_MY15_Gas_Rx" SG_ 765 Mc_VehUnitTempUsrSel_St_UB 1;
BA_ "U_UP375_MY15_Diesel_Rx" SG_ 765 Mc_VehUnitTempUsrSel_St_UB 1;
BA_ "U_CD43_MY16_Gas_Rx" SG_ 765 Mc_VehUnitTempUsrSel_St_UB 1;
BA_ "CrossOver_InfoCAN" SG_ 765 Mc_VehUnitTempUsrSel_St 1;
BA_ "GenSigSendType" SG_ 765 Mc_VehUnitTempUsrSel_St 3;
BA_ "U_CD4_MY13_Diesel_Rx" SG_ 765 Mc_VehUnitTempUsrSel_St 1;
BA_ "U_CD4_MY13_Gas_Rx" SG_ 765 Mc_VehUnitTempUsrSel_St 1;
BA_ "U_CD4_MY13_Hev_Rx" SG_ 765 Mc_VehUnitTempUsrSel_St 1;
BA_ "U_CD4_MY13_Phev_Rx" SG_ 765 Mc_VehUnitTempUsrSel_St 1;
BA_ "U_CD42_MY14_Diesel_Rx" SG_ 765 Mc_VehUnitTempUsrSel_St 1;
BA_ "U_CD42_MY14_Gas_Rx" SG_ 765 Mc_VehUnitTempUsrSel_St 1;
BA_ "U_P552_MY15_Gas_Rx" SG_ 765 Mc_VehUnitTempUsrSel_St 1;
BA_ "U_S550_MY15_Gas_Rx" SG_ 765 Mc_VehUnitTempUsrSel_St 1;
BA_ "U_C489_MY14_Gas_Rx" SG_ 765 Mc_VehUnitTempUsrSel_St 1;
BA_ "U_U502_MY15_Gas_Rx" SG_ 765 Mc_VehUnitTempUsrSel_St 1;
BA_ "U_UP375_MY15_Gas_Rx" SG_ 765 Mc_VehUnitTempUsrSel_St 1;
BA_ "U_UP375_MY15_Diesel_Rx" SG_ 765 Mc_VehUnitTempUsrSel_St 1;
BA_ "U_CD43_MY16_Gas_Rx" SG_ 765 Mc_VehUnitTempUsrSel_St 1;
BA_ "U_CD42_MY14_Gas_Rx" SG_ 765 SteWhlHeat_D_Stat_UB 1;
BA_ "U_P552_MY15_Gas_Rx" SG_ 765 SteWhlHeat_D_Stat_UB 1;
BA_ "U_C489_MY14_Gas_Rx" SG_ 765 SteWhlHeat_D_Stat_UB 1;
BA_ "U_CD43_MY16_Gas_Rx" SG_ 765 SteWhlHeat_D_Stat_UB 1;
BA_ "U_CD4_MY13_Diesel_Rx" SG_ 765 ParkDetect_Stat_UB 1;
BA_ "U_CD4_MY13_Gas_Rx" SG_ 765 ParkDetect_Stat_UB 1;
BA_ "U_CD42_MY14_Diesel_Rx" SG_ 765 ParkDetect_Stat_UB 1;
BA_ "U_CD42_MY14_Gas_Rx" SG_ 765 ParkDetect_Stat_UB 1;
BA_ "U_P552_MY15_Gas_Rx" SG_ 765 ParkDetect_Stat_UB 1;
BA_ "U_S550_MY15_Gas_Rx" SG_ 765 ParkDetect_Stat_UB 1;
BA_ "U_C489_MY14_Gas_Rx" SG_ 765 ParkDetect_Stat_UB 1;
BA_ "U_U502_MY15_Gas_Rx" SG_ 765 ParkDetect_Stat_UB 1;
BA_ "U_CD43_MY16_Gas_Rx" SG_ 765 ParkDetect_Stat_UB 1;
BA_ "U_CD4_MY14_Diesel_Rx" SG_ 765 ParkDetect_Stat_UB 1;
BA_ "U_CD4_MY14_Gas_Rx" SG_ 765 ParkDetect_Stat_UB 1;
BA_ "U_CD4_MY14_Hev_Rx" SG_ 765 ParkDetect_Stat_UB 1;
BA_ "U_CD4_MY14_Phev_Rx" SG_ 765 ParkDetect_Stat_UB 1;
BA_ "CrossOver_InfoCAN" SG_ 765 ParkDetect_Stat 1;
BA_ "GenSigSendType" SG_ 765 ParkDetect_Stat 3;
BA_ "U_CD4_MY13_Diesel_Rx" SG_ 765 ParkDetect_Stat 1;
BA_ "U_CD4_MY13_Gas_Rx" SG_ 765 ParkDetect_Stat 1;
BA_ "U_CD42_MY14_Diesel_Rx" SG_ 765 ParkDetect_Stat 1;
BA_ "U_CD42_MY14_Gas_Rx" SG_ 765 ParkDetect_Stat 1;
BA_ "U_P552_MY15_Gas_Rx" SG_ 765 ParkDetect_Stat 1;
BA_ "U_S550_MY15_Gas_Rx" SG_ 765 ParkDetect_Stat 1;
BA_ "U_C489_MY14_Gas_Rx" SG_ 765 ParkDetect_Stat 1;
BA_ "U_U502_MY15_Gas_Rx" SG_ 765 ParkDetect_Stat 1;
BA_ "U_CD43_MY16_Gas_Rx" SG_ 765 ParkDetect_Stat 1;
BA_ "U_CD4_MY14_Diesel_Rx" SG_ 765 ParkDetect_Stat 1;
BA_ "U_CD4_MY14_Gas_Rx" SG_ 765 ParkDetect_Stat 1;
BA_ "U_CD4_MY14_Hev_Rx" SG_ 765 ParkDetect_Stat 1;
BA_ "U_CD4_MY14_Phev_Rx" SG_ 765 ParkDetect_Stat 1;
BA_ "WakeupSignal" SG_ 672 SetPointVolume 1;
BA_ "CrossOver_InfoCAN" SG_ 672 SetPointVolume 1;
BA_ "GenSigSendType" SG_ 672 SetPointVolume 3;
BA_ "U_CD4_MY13_Diesel_Rx" SG_ 672 SetPointVolume 1;
BA_ "U_CD4_MY13_Gas_Rx" SG_ 672 SetPointVolume 1;
BA_ "U_CD4_MY13_Hev_Rx" SG_ 672 SetPointVolume 1;
BA_ "U_CD4_MY13_Phev_Rx" SG_ 672 SetPointVolume 1;
BA_ "U_CD42_MY14_Diesel_Rx" SG_ 672 SetPointVolume 1;
BA_ "U_CD42_MY14_Gas_Rx" SG_ 672 SetPointVolume 1;
BA_ "U_P552_MY15_Gas_Rx" SG_ 672 SetPointVolume 1;
BA_ "U_S550_MY15_Gas_Rx" SG_ 672 SetPointVolume 1;
BA_ "U_C489_MY14_Gas_Rx" SG_ 672 SetPointVolume 1;
BA_ "U_U502_MY15_Gas_Rx" SG_ 672 SetPointVolume 1;
BA_ "U_B479_MY15_Gas_Rx" SG_ 672 SetPointVolume 1;
BA_ "U_UP375_MY15_Gas_Rx" SG_ 672 SetPointVolume 1;
BA_ "U_UP375_MY15_Diesel_Rx" SG_ 672 SetPointVolume 1;
BA_ "U_CD4_MY13_Diesel_Tx" SG_ 672 SetPointVolume 1;
BA_ "U_CD4_MY13_Gas_Tx" SG_ 672 SetPointVolume 1;
BA_ "U_CD4_MY13_Hev_Tx" SG_ 672 SetPointVolume 1;
BA_ "U_CD4_MY13_Phev_Tx" SG_ 672 SetPointVolume 1;
BA_ "U_CD42_MY14_Diesel_Tx" SG_ 672 SetPointVolume 1;
BA_ "U_CD42_MY14_Gas_Tx" SG_ 672 SetPointVolume 1;
BA_ "U_P552_MY15_Gas_Tx" SG_ 672 SetPointVolume 1;
BA_ "U_S550_MY15_Gas_Tx" SG_ 672 SetPointVolume 1;
BA_ "U_C489_MY14_Gas_Tx" SG_ 672 SetPointVolume 1;
BA_ "U_U502_MY15_Gas_Tx" SG_ 672 SetPointVolume 1;
BA_ "U_UP375_MY15_Gas_Tx" SG_ 672 SetPointVolume 1;
BA_ "U_UP375_MY15_Diesel_Tx" SG_ 672 SetPointVolume 1;
BA_ "U_CD43_MY16_Gas_Tx" SG_ 672 SetPointVolume 1;
BA_ "WakeupSignal" SG_ 672 SetVolume 1;
BA_ "CrossOver_InfoCAN" SG_ 672 SetVolume 1;
BA_ "GenSigStartValue" SG_ 672 SetVolume 30;
BA_ "GenSigSendType" SG_ 672 SetVolume 3;
BA_ "U_CD4_MY13_Diesel_Rx" SG_ 672 SetVolume 1;
BA_ "U_CD4_MY13_Gas_Rx" SG_ 672 SetVolume 1;
BA_ "U_CD4_MY13_Hev_Rx" SG_ 672 SetVolume 1;
BA_ "U_CD4_MY13_Phev_Rx" SG_ 672 SetVolume 1;
BA_ "U_CD42_MY14_Diesel_Rx" SG_ 672 SetVolume 1;
BA_ "U_CD42_MY14_Gas_Rx" SG_ 672 SetVolume 1;
BA_ "U_P552_MY15_Gas_Rx" SG_ 672 SetVolume 1;
BA_ "U_S550_MY15_Gas_Rx" SG_ 672 SetVolume 1;
BA_ "U_C489_MY14_Gas_Rx" SG_ 672 SetVolume 1;
BA_ "U_U502_MY15_Gas_Rx" SG_ 672 SetVolume 1;
BA_ "U_B479_MY15_Gas_Rx" SG_ 672 SetVolume 1;
BA_ "U_UP375_MY15_Gas_Rx" SG_ 672 SetVolume 1;
BA_ "U_UP375_MY15_Diesel_Rx" SG_ 672 SetVolume 1;
BA_ "U_CD4_MY13_Diesel_Tx" SG_ 672 SetVolume 1;
BA_ "U_CD4_MY13_Gas_Tx" SG_ 672 SetVolume 1;
BA_ "U_CD4_MY13_Hev_Tx" SG_ 672 SetVolume 1;
BA_ "U_CD4_MY13_Phev_Tx" SG_ 672 SetVolume 1;
BA_ "U_CD42_MY14_Diesel_Tx" SG_ 672 SetVolume 1;
BA_ "U_CD42_MY14_Gas_Tx" SG_ 672 SetVolume 1;
BA_ "U_P552_MY15_Gas_Tx" SG_ 672 SetVolume 1;
BA_ "U_S550_MY15_Gas_Tx" SG_ 672 SetVolume 1;
BA_ "U_C489_MY14_Gas_Tx" SG_ 672 SetVolume 1;
BA_ "U_U502_MY15_Gas_Tx" SG_ 672 SetVolume 1;
BA_ "U_UP375_MY15_Gas_Tx" SG_ 672 SetVolume 1;
BA_ "U_UP375_MY15_Diesel_Tx" SG_ 672 SetVolume 1;
BA_ "U_CD43_MY16_Gas_Tx" SG_ 672 SetVolume 1;
BA_ "WakeupSignal" SG_ 672 Coding_BtnID_D 1;
BA_ "CrossOver_InfoCAN" SG_ 672 Coding_BtnID_D 1;
BA_ "GenSigSendType" SG_ 672 Coding_BtnID_D 3;
BA_ "U_CD4_MY13_Diesel_Rx" SG_ 672 Coding_BtnID_D 1;
BA_ "U_CD4_MY13_Gas_Rx" SG_ 672 Coding_BtnID_D 1;
BA_ "U_CD4_MY13_Hev_Rx" SG_ 672 Coding_BtnID_D 1;
BA_ "U_CD4_MY13_Phev_Rx" SG_ 672 Coding_BtnID_D 1;
BA_ "U_CD42_MY14_Diesel_Rx" SG_ 672 Coding_BtnID_D 1;
BA_ "U_CD42_MY14_Gas_Rx" SG_ 672 Coding_BtnID_D 1;
BA_ "U_P552_MY15_Gas_Rx" SG_ 672 Coding_BtnID_D 1;
BA_ "U_S550_MY15_Gas_Rx" SG_ 672 Coding_BtnID_D 1;
BA_ "U_C489_MY14_Gas_Rx" SG_ 672 Coding_BtnID_D 1;
BA_ "U_U502_MY15_Gas_Rx" SG_ 672 Coding_BtnID_D 1;
BA_ "U_B479_MY15_Gas_Rx" SG_ 672 Coding_BtnID_D 1;
BA_ "U_UP375_MY15_Gas_Rx" SG_ 672 Coding_BtnID_D 1;
BA_ "U_UP375_MY15_Diesel_Rx" SG_ 672 Coding_BtnID_D 1;
BA_ "U_CD4_MY13_Diesel_Tx" SG_ 672 Coding_BtnID_D 1;
BA_ "U_CD4_MY13_Gas_Tx" SG_ 672 Coding_BtnID_D 1;
BA_ "U_CD4_MY13_Hev_Tx" SG_ 672 Coding_BtnID_D 1;
BA_ "U_CD4_MY13_Phev_Tx" SG_ 672 Coding_BtnID_D 1;
BA_ "U_CD42_MY14_Diesel_Tx" SG_ 672 Coding_BtnID_D 1;
BA_ "U_CD42_MY14_Gas_Tx" SG_ 672 Coding_BtnID_D 1;
BA_ "U_P552_MY15_Gas_Tx" SG_ 672 Coding_BtnID_D 1;
BA_ "U_S550_MY15_Gas_Tx" SG_ 672 Coding_BtnID_D 1;
BA_ "U_C489_MY14_Gas_Tx" SG_ 672 Coding_BtnID_D 1;
BA_ "U_U502_MY15_Gas_Tx" SG_ 672 Coding_BtnID_D 1;
BA_ "U_UP375_MY15_Gas_Tx" SG_ 672 Coding_BtnID_D 1;
BA_ "U_UP375_MY15_Diesel_Tx" SG_ 672 Coding_BtnID_D 1;
BA_ "U_CD43_MY16_Gas_Tx" SG_ 672 Coding_BtnID_D 1;
BA_ "WakeupSignal" SG_ 672 Coding_BtnID_C 1;
BA_ "CrossOver_InfoCAN" SG_ 672 Coding_BtnID_C 1;
BA_ "GenSigSendType" SG_ 672 Coding_BtnID_C 3;
BA_ "U_CD4_MY13_Diesel_Rx" SG_ 672 Coding_BtnID_C 1;
BA_ "U_CD4_MY13_Gas_Rx" SG_ 672 Coding_BtnID_C 1;
BA_ "U_CD4_MY13_Hev_Rx" SG_ 672 Coding_BtnID_C 1;
BA_ "U_CD4_MY13_Phev_Rx" SG_ 672 Coding_BtnID_C 1;
BA_ "U_CD42_MY14_Diesel_Rx" SG_ 672 Coding_BtnID_C 1;
BA_ "U_CD42_MY14_Gas_Rx" SG_ 672 Coding_BtnID_C 1;
BA_ "U_P552_MY15_Gas_Rx" SG_ 672 Coding_BtnID_C 1;
BA_ "U_S550_MY15_Gas_Rx" SG_ 672 Coding_BtnID_C 1;
BA_ "U_C489_MY14_Gas_Rx" SG_ 672 Coding_BtnID_C 1;
BA_ "U_U502_MY15_Gas_Rx" SG_ 672 Coding_BtnID_C 1;
BA_ "U_B479_MY15_Gas_Rx" SG_ 672 Coding_BtnID_C 1;
BA_ "U_UP375_MY15_Gas_Rx" SG_ 672 Coding_BtnID_C 1;
BA_ "U_UP375_MY15_Diesel_Rx" SG_ 672 Coding_BtnID_C 1;
BA_ "U_CD4_MY13_Diesel_Tx" SG_ 672 Coding_BtnID_C 1;
BA_ "U_CD4_MY13_Gas_Tx" SG_ 672 Coding_BtnID_C 1;
BA_ "U_CD4_MY13_Hev_Tx" SG_ 672 Coding_BtnID_C 1;
BA_ "U_CD4_MY13_Phev_Tx" SG_ 672 Coding_BtnID_C 1;
BA_ "U_CD42_MY14_Diesel_Tx" SG_ 672 Coding_BtnID_C 1;
BA_ "U_CD42_MY14_Gas_Tx" SG_ 672 Coding_BtnID_C 1;
BA_ "U_P552_MY15_Gas_Tx" SG_ 672 Coding_BtnID_C 1;
BA_ "U_S550_MY15_Gas_Tx" SG_ 672 Coding_BtnID_C 1;
BA_ "U_C489_MY14_Gas_Tx" SG_ 672 Coding_BtnID_C 1;
BA_ "U_U502_MY15_Gas_Tx" SG_ 672 Coding_BtnID_C 1;
BA_ "U_UP375_MY15_Gas_Tx" SG_ 672 Coding_BtnID_C 1;
BA_ "U_UP375_MY15_Diesel_Tx" SG_ 672 Coding_BtnID_C 1;
BA_ "U_CD43_MY16_Gas_Tx" SG_ 672 Coding_BtnID_C 1;
BA_ "WakeupSignal" SG_ 672 Coding_BtnID_B 1;
BA_ "CrossOver_InfoCAN" SG_ 672 Coding_BtnID_B 1;
BA_ "GenSigSendType" SG_ 672 Coding_BtnID_B 3;
BA_ "U_CD4_MY13_Diesel_Rx" SG_ 672 Coding_BtnID_B 1;
BA_ "U_CD4_MY13_Gas_Rx" SG_ 672 Coding_BtnID_B 1;
BA_ "U_CD4_MY13_Hev_Rx" SG_ 672 Coding_BtnID_B 1;
BA_ "U_CD4_MY13_Phev_Rx" SG_ 672 Coding_BtnID_B 1;
BA_ "U_CD42_MY14_Diesel_Rx" SG_ 672 Coding_BtnID_B 1;
BA_ "U_CD42_MY14_Gas_Rx" SG_ 672 Coding_BtnID_B 1;
BA_ "U_P552_MY15_Gas_Rx" SG_ 672 Coding_BtnID_B 1;
BA_ "U_S550_MY15_Gas_Rx" SG_ 672 Coding_BtnID_B 1;
BA_ "U_C489_MY14_Gas_Rx" SG_ 672 Coding_BtnID_B 1;
BA_ "U_U502_MY15_Gas_Rx" SG_ 672 Coding_BtnID_B 1;
BA_ "U_B479_MY15_Gas_Rx" SG_ 672 Coding_BtnID_B 1;
BA_ "U_UP375_MY15_Gas_Rx" SG_ 672 Coding_BtnID_B 1;
BA_ "U_UP375_MY15_Diesel_Rx" SG_ 672 Coding_BtnID_B 1;
BA_ "U_CD4_MY13_Diesel_Tx" SG_ 672 Coding_BtnID_B 1;
BA_ "U_CD4_MY13_Gas_Tx" SG_ 672 Coding_BtnID_B 1;
BA_ "U_CD4_MY13_Hev_Tx" SG_ 672 Coding_BtnID_B 1;
BA_ "U_CD4_MY13_Phev_Tx" SG_ 672 Coding_BtnID_B 1;
BA_ "U_CD42_MY14_Diesel_Tx" SG_ 672 Coding_BtnID_B 1;
BA_ "U_CD42_MY14_Gas_Tx" SG_ 672 Coding_BtnID_B 1;
BA_ "U_P552_MY15_Gas_Tx" SG_ 672 Coding_BtnID_B 1;
BA_ "U_S550_MY15_Gas_Tx" SG_ 672 Coding_BtnID_B 1;
BA_ "U_C489_MY14_Gas_Tx" SG_ 672 Coding_BtnID_B 1;
BA_ "U_U502_MY15_Gas_Tx" SG_ 672 Coding_BtnID_B 1;
BA_ "U_UP375_MY15_Gas_Tx" SG_ 672 Coding_BtnID_B 1;
BA_ "U_UP375_MY15_Diesel_Tx" SG_ 672 Coding_BtnID_B 1;
BA_ "U_CD43_MY16_Gas_Tx" SG_ 672 Coding_BtnID_B 1;
BA_ "WakeupSignal" SG_ 672 Coding_BtnID_A 1;
BA_ "CrossOver_InfoCAN" SG_ 672 Coding_BtnID_A 1;
BA_ "GenSigSendType" SG_ 672 Coding_BtnID_A 3;
BA_ "U_CD4_MY13_Diesel_Rx" SG_ 672 Coding_BtnID_A 1;
BA_ "U_CD4_MY13_Gas_Rx" SG_ 672 Coding_BtnID_A 1;
BA_ "U_CD4_MY13_Hev_Rx" SG_ 672 Coding_BtnID_A 1;
BA_ "U_CD4_MY13_Phev_Rx" SG_ 672 Coding_BtnID_A 1;
BA_ "U_CD42_MY14_Diesel_Rx" SG_ 672 Coding_BtnID_A 1;
BA_ "U_CD42_MY14_Gas_Rx" SG_ 672 Coding_BtnID_A 1;
BA_ "U_P552_MY15_Gas_Rx" SG_ 672 Coding_BtnID_A 1;
BA_ "U_S550_MY15_Gas_Rx" SG_ 672 Coding_BtnID_A 1;
BA_ "U_C489_MY14_Gas_Rx" SG_ 672 Coding_BtnID_A 1;
BA_ "U_U502_MY15_Gas_Rx" SG_ 672 Coding_BtnID_A 1;
BA_ "U_B479_MY15_Gas_Rx" SG_ 672 Coding_BtnID_A 1;
BA_ "U_UP375_MY15_Gas_Rx" SG_ 672 Coding_BtnID_A 1;
BA_ "U_UP375_MY15_Diesel_Rx" SG_ 672 Coding_BtnID_A 1;
BA_ "U_CD4_MY13_Diesel_Tx" SG_ 672 Coding_BtnID_A 1;
BA_ "U_CD4_MY13_Gas_Tx" SG_ 672 Coding_BtnID_A 1;
BA_ "U_CD4_MY13_Hev_Tx" SG_ 672 Coding_BtnID_A 1;
BA_ "U_CD4_MY13_Phev_Tx" SG_ 672 Coding_BtnID_A 1;
BA_ "U_CD42_MY14_Diesel_Tx" SG_ 672 Coding_BtnID_A 1;
BA_ "U_CD42_MY14_Gas_Tx" SG_ 672 Coding_BtnID_A 1;
BA_ "U_P552_MY15_Gas_Tx" SG_ 672 Coding_BtnID_A 1;
BA_ "U_S550_MY15_Gas_Tx" SG_ 672 Coding_BtnID_A 1;
BA_ "U_C489_MY14_Gas_Tx" SG_ 672 Coding_BtnID_A 1;
BA_ "U_U502_MY15_Gas_Tx" SG_ 672 Coding_BtnID_A 1;
BA_ "U_UP375_MY15_Gas_Tx" SG_ 672 Coding_BtnID_A 1;
BA_ "U_UP375_MY15_Diesel_Tx" SG_ 672 Coding_BtnID_A 1;
BA_ "U_CD43_MY16_Gas_Tx" SG_ 672 Coding_BtnID_A 1;
BA_ "WakeupSignal" SG_ 672 BtnID_D 1;
BA_ "CrossOver_InfoCAN" SG_ 672 BtnID_D 1;
BA_ "GenSigStartValue" SG_ 672 BtnID_D 255;
BA_ "GenSigSendType" SG_ 672 BtnID_D 3;
BA_ "U_CD4_MY13_Diesel_Rx" SG_ 672 BtnID_D 1;
BA_ "U_CD4_MY13_Gas_Rx" SG_ 672 BtnID_D 1;
BA_ "U_CD4_MY13_Hev_Rx" SG_ 672 BtnID_D 1;
BA_ "U_CD4_MY13_Phev_Rx" SG_ 672 BtnID_D 1;
BA_ "U_CD42_MY14_Diesel_Rx" SG_ 672 BtnID_D 1;
BA_ "U_CD42_MY14_Gas_Rx" SG_ 672 BtnID_D 1;
BA_ "U_P552_MY15_Gas_Rx" SG_ 672 BtnID_D 1;
BA_ "U_S550_MY15_Gas_Rx" SG_ 672 BtnID_D 1;
BA_ "U_C489_MY14_Gas_Rx" SG_ 672 BtnID_D 1;
BA_ "U_U502_MY15_Gas_Rx" SG_ 672 BtnID_D 1;
BA_ "U_B479_MY15_Gas_Rx" SG_ 672 BtnID_D 1;
BA_ "U_UP375_MY15_Gas_Rx" SG_ 672 BtnID_D 1;
BA_ "U_UP375_MY15_Diesel_Rx" SG_ 672 BtnID_D 1;
BA_ "U_CD4_MY13_Diesel_Tx" SG_ 672 BtnID_D 1;
BA_ "U_CD4_MY13_Gas_Tx" SG_ 672 BtnID_D 1;
BA_ "U_CD4_MY13_Hev_Tx" SG_ 672 BtnID_D 1;
BA_ "U_CD4_MY13_Phev_Tx" SG_ 672 BtnID_D 1;
BA_ "U_CD42_MY14_Diesel_Tx" SG_ 672 BtnID_D 1;
BA_ "U_CD42_MY14_Gas_Tx" SG_ 672 BtnID_D 1;
BA_ "U_P552_MY15_Gas_Tx" SG_ 672 BtnID_D 1;
BA_ "U_S550_MY15_Gas_Tx" SG_ 672 BtnID_D 1;
BA_ "U_C489_MY14_Gas_Tx" SG_ 672 BtnID_D 1;
BA_ "U_U502_MY15_Gas_Tx" SG_ 672 BtnID_D 1;
BA_ "U_UP375_MY15_Gas_Tx" SG_ 672 BtnID_D 1;
BA_ "U_UP375_MY15_Diesel_Tx" SG_ 672 BtnID_D 1;
BA_ "U_CD43_MY16_Gas_Tx" SG_ 672 BtnID_D 1;
BA_ "WakeupSignal" SG_ 672 BtnID_C 1;
BA_ "CrossOver_InfoCAN" SG_ 672 BtnID_C 1;
BA_ "GenSigStartValue" SG_ 672 BtnID_C 255;
BA_ "GenSigSendType" SG_ 672 BtnID_C 3;
BA_ "U_CD4_MY13_Diesel_Rx" SG_ 672 BtnID_C 1;
BA_ "U_CD4_MY13_Gas_Rx" SG_ 672 BtnID_C 1;
BA_ "U_CD4_MY13_Hev_Rx" SG_ 672 BtnID_C 1;
BA_ "U_CD4_MY13_Phev_Rx" SG_ 672 BtnID_C 1;
BA_ "U_CD42_MY14_Diesel_Rx" SG_ 672 BtnID_C 1;
BA_ "U_CD42_MY14_Gas_Rx" SG_ 672 BtnID_C 1;
BA_ "U_P552_MY15_Gas_Rx" SG_ 672 BtnID_C 1;
BA_ "U_S550_MY15_Gas_Rx" SG_ 672 BtnID_C 1;
BA_ "U_C489_MY14_Gas_Rx" SG_ 672 BtnID_C 1;
BA_ "U_U502_MY15_Gas_Rx" SG_ 672 BtnID_C 1;
BA_ "U_B479_MY15_Gas_Rx" SG_ 672 BtnID_C 1;
BA_ "U_UP375_MY15_Gas_Rx" SG_ 672 BtnID_C 1;
BA_ "U_UP375_MY15_Diesel_Rx" SG_ 672 BtnID_C 1;
BA_ "U_CD4_MY13_Diesel_Tx" SG_ 672 BtnID_C 1;
BA_ "U_CD4_MY13_Gas_Tx" SG_ 672 BtnID_C 1;
BA_ "U_CD4_MY13_Hev_Tx" SG_ 672 BtnID_C 1;
BA_ "U_CD4_MY13_Phev_Tx" SG_ 672 BtnID_C 1;
BA_ "U_CD42_MY14_Diesel_Tx" SG_ 672 BtnID_C 1;
BA_ "U_CD42_MY14_Gas_Tx" SG_ 672 BtnID_C 1;
BA_ "U_P552_MY15_Gas_Tx" SG_ 672 BtnID_C 1;
BA_ "U_S550_MY15_Gas_Tx" SG_ 672 BtnID_C 1;
BA_ "U_C489_MY14_Gas_Tx" SG_ 672 BtnID_C 1;
BA_ "U_U502_MY15_Gas_Tx" SG_ 672 BtnID_C 1;
BA_ "U_UP375_MY15_Gas_Tx" SG_ 672 BtnID_C 1;
BA_ "U_UP375_MY15_Diesel_Tx" SG_ 672 BtnID_C 1;
BA_ "U_CD43_MY16_Gas_Tx" SG_ 672 BtnID_C 1;
BA_ "WakeupSignal" SG_ 672 BtnID_B 1;
BA_ "CrossOver_InfoCAN" SG_ 672 BtnID_B 1;
BA_ "GenSigStartValue" SG_ 672 BtnID_B 255;
BA_ "GenSigSendType" SG_ 672 BtnID_B 3;
BA_ "U_CD4_MY13_Diesel_Rx" SG_ 672 BtnID_B 1;
BA_ "U_CD4_MY13_Gas_Rx" SG_ 672 BtnID_B 1;
BA_ "U_CD4_MY13_Hev_Rx" SG_ 672 BtnID_B 1;
BA_ "U_CD4_MY13_Phev_Rx" SG_ 672 BtnID_B 1;
BA_ "U_CD42_MY14_Diesel_Rx" SG_ 672 BtnID_B 1;
BA_ "U_CD42_MY14_Gas_Rx" SG_ 672 BtnID_B 1;
BA_ "U_P552_MY15_Gas_Rx" SG_ 672 BtnID_B 1;
BA_ "U_S550_MY15_Gas_Rx" SG_ 672 BtnID_B 1;
BA_ "U_C489_MY14_Gas_Rx" SG_ 672 BtnID_B 1;
BA_ "U_U502_MY15_Gas_Rx" SG_ 672 BtnID_B 1;
BA_ "U_B479_MY15_Gas_Rx" SG_ 672 BtnID_B 1;
BA_ "U_UP375_MY15_Gas_Rx" SG_ 672 BtnID_B 1;
BA_ "U_UP375_MY15_Diesel_Rx" SG_ 672 BtnID_B 1;
BA_ "U_CD4_MY13_Diesel_Tx" SG_ 672 BtnID_B 1;
BA_ "U_CD4_MY13_Gas_Tx" SG_ 672 BtnID_B 1;
BA_ "U_CD4_MY13_Hev_Tx" SG_ 672 BtnID_B 1;
BA_ "U_CD4_MY13_Phev_Tx" SG_ 672 BtnID_B 1;
BA_ "U_CD42_MY14_Diesel_Tx" SG_ 672 BtnID_B 1;
BA_ "U_CD42_MY14_Gas_Tx" SG_ 672 BtnID_B 1;
BA_ "U_P552_MY15_Gas_Tx" SG_ 672 BtnID_B 1;
BA_ "U_S550_MY15_Gas_Tx" SG_ 672 BtnID_B 1;
BA_ "U_C489_MY14_Gas_Tx" SG_ 672 BtnID_B 1;
BA_ "U_U502_MY15_Gas_Tx" SG_ 672 BtnID_B 1;
BA_ "U_UP375_MY15_Gas_Tx" SG_ 672 BtnID_B 1;
BA_ "U_UP375_MY15_Diesel_Tx" SG_ 672 BtnID_B 1;
BA_ "U_CD43_MY16_Gas_Tx" SG_ 672 BtnID_B 1;
BA_ "WakeupSignal" SG_ 672 BtnID_A 1;
BA_ "CrossOver_InfoCAN" SG_ 672 BtnID_A 1;
BA_ "GenSigStartValue" SG_ 672 BtnID_A 255;
BA_ "GenSigSendType" SG_ 672 BtnID_A 3;
BA_ "U_CD4_MY13_Diesel_Rx" SG_ 672 BtnID_A 1;
BA_ "U_CD4_MY13_Gas_Rx" SG_ 672 BtnID_A 1;
BA_ "U_CD4_MY13_Hev_Rx" SG_ 672 BtnID_A 1;
BA_ "U_CD4_MY13_Phev_Rx" SG_ 672 BtnID_A 1;
BA_ "U_CD42_MY14_Diesel_Rx" SG_ 672 BtnID_A 1;
BA_ "U_CD42_MY14_Gas_Rx" SG_ 672 BtnID_A 1;
BA_ "U_P552_MY15_Gas_Rx" SG_ 672 BtnID_A 1;
BA_ "U_S550_MY15_Gas_Rx" SG_ 672 BtnID_A 1;
BA_ "U_C489_MY14_Gas_Rx" SG_ 672 BtnID_A 1;
BA_ "U_U502_MY15_Gas_Rx" SG_ 672 BtnID_A 1;
BA_ "U_B479_MY15_Gas_Rx" SG_ 672 BtnID_A 1;
BA_ "U_UP375_MY15_Gas_Rx" SG_ 672 BtnID_A 1;
BA_ "U_UP375_MY15_Diesel_Rx" SG_ 672 BtnID_A 1;
BA_ "U_CD4_MY13_Diesel_Tx" SG_ 672 BtnID_A 1;
BA_ "U_CD4_MY13_Gas_Tx" SG_ 672 BtnID_A 1;
BA_ "U_CD4_MY13_Hev_Tx" SG_ 672 BtnID_A 1;
BA_ "U_CD4_MY13_Phev_Tx" SG_ 672 BtnID_A 1;
BA_ "U_CD42_MY14_Diesel_Tx" SG_ 672 BtnID_A 1;
BA_ "U_CD42_MY14_Gas_Tx" SG_ 672 BtnID_A 1;
BA_ "U_P552_MY15_Gas_Tx" SG_ 672 BtnID_A 1;
BA_ "U_S550_MY15_Gas_Tx" SG_ 672 BtnID_A 1;
BA_ "U_C489_MY14_Gas_Tx" SG_ 672 BtnID_A 1;
BA_ "U_U502_MY15_Gas_Tx" SG_ 672 BtnID_A 1;
BA_ "U_UP375_MY15_Gas_Tx" SG_ 672 BtnID_A 1;
BA_ "U_UP375_MY15_Diesel_Tx" SG_ 672 BtnID_A 1;
BA_ "U_CD43_MY16_Gas_Tx" SG_ 672 BtnID_A 1;
BA_ "CrossOver_InfoCAN" SG_ 672 BCP_Audible_Beep_Rq 1;
BA_ "GenSigSendType" SG_ 672 BCP_Audible_Beep_Rq 3;
BA_ "U_CD4_MY13_Diesel_Tx" SG_ 672 BCP_Audible_Beep_Rq 1;
BA_ "U_CD4_MY13_Gas_Tx" SG_ 672 BCP_Audible_Beep_Rq 1;
BA_ "U_CD4_MY13_Hev_Tx" SG_ 672 BCP_Audible_Beep_Rq 1;
BA_ "U_CD4_MY13_Phev_Tx" SG_ 672 BCP_Audible_Beep_Rq 1;
BA_ "U_CD42_MY14_Diesel_Tx" SG_ 672 BCP_Audible_Beep_Rq 1;
BA_ "U_CD42_MY14_Gas_Tx" SG_ 672 BCP_Audible_Beep_Rq 1;
BA_ "U_P552_MY15_Gas_Tx" SG_ 672 BCP_Audible_Beep_Rq 1;
BA_ "U_S550_MY15_Gas_Tx" SG_ 672 BCP_Audible_Beep_Rq 1;
BA_ "U_C489_MY14_Gas_Tx" SG_ 672 BCP_Audible_Beep_Rq 1;
BA_ "U_U502_MY15_Gas_Tx" SG_ 672 BCP_Audible_Beep_Rq 1;
BA_ "U_UP375_MY15_Gas_Tx" SG_ 672 BCP_Audible_Beep_Rq 1;
BA_ "U_UP375_MY15_Diesel_Tx" SG_ 672 BCP_Audible_Beep_Rq 1;
BA_ "U_CD43_MY16_Gas_Tx" SG_ 672 BCP_Audible_Beep_Rq 1;
BA_ "CrossOver_InfoCAN" SG_ 710 BEZEL_RDISP_WORD_Tx 1;
BA_ "U_CD4_MY13_Diesel_Tx" SG_ 710 BEZEL_RDISP_WORD_Tx 1;
BA_ "U_CD4_MY13_Gas_Tx" SG_ 710 BEZEL_RDISP_WORD_Tx 1;
BA_ "U_CD4_MY13_Hev_Tx" SG_ 710 BEZEL_RDISP_WORD_Tx 1;
BA_ "U_CD4_MY13_Phev_Tx" SG_ 710 BEZEL_RDISP_WORD_Tx 1;
BA_ "U_CD42_MY14_Diesel_Tx" SG_ 710 BEZEL_RDISP_WORD_Tx 1;
BA_ "U_CD42_MY14_Gas_Tx" SG_ 710 BEZEL_RDISP_WORD_Tx 1;
BA_ "U_P552_MY15_Gas_Tx" SG_ 710 BEZEL_RDISP_WORD_Tx 1;
BA_ "U_S550_MY15_Gas_Tx" SG_ 710 BEZEL_RDISP_WORD_Tx 1;
BA_ "U_C489_MY14_Gas_Tx" SG_ 710 BEZEL_RDISP_WORD_Tx 1;
BA_ "U_U502_MY15_Gas_Tx" SG_ 710 BEZEL_RDISP_WORD_Tx 1;
BA_ "U_UP375_MY15_Gas_Tx" SG_ 710 BEZEL_RDISP_WORD_Tx 1;
BA_ "U_UP375_MY15_Diesel_Tx" SG_ 710 BEZEL_RDISP_WORD_Tx 1;
BA_ "U_CD43_MY16_Gas_Tx" SG_ 710 BEZEL_RDISP_WORD_Tx 1;
BA_ "CrossOver_InfoCAN" SG_ 556 EFP_Bezel_Diag_St 1;
BA_ "GenSigSendType" SG_ 556 EFP_Bezel_Diag_St 3;
BA_ "U_CD4_MY13_Diesel_Tx" SG_ 556 EFP_Bezel_Diag_St 1;
BA_ "U_CD4_MY13_Gas_Tx" SG_ 556 EFP_Bezel_Diag_St 1;
BA_ "U_CD4_MY13_Hev_Tx" SG_ 556 EFP_Bezel_Diag_St 1;
BA_ "U_CD4_MY13_Phev_Tx" SG_ 556 EFP_Bezel_Diag_St 1;
BA_ "U_CD42_MY14_Diesel_Tx" SG_ 556 EFP_Bezel_Diag_St 1;
BA_ "U_CD42_MY14_Gas_Tx" SG_ 556 EFP_Bezel_Diag_St 1;
BA_ "U_P552_MY15_Gas_Tx" SG_ 556 EFP_Bezel_Diag_St 1;
BA_ "U_S550_MY15_Gas_Tx" SG_ 556 EFP_Bezel_Diag_St 1;
BA_ "U_C489_MY14_Gas_Tx" SG_ 556 EFP_Bezel_Diag_St 1;
BA_ "U_U502_MY15_Gas_Tx" SG_ 556 EFP_Bezel_Diag_St 1;
BA_ "U_UP375_MY15_Gas_Tx" SG_ 556 EFP_Bezel_Diag_St 1;
BA_ "U_UP375_MY15_Diesel_Tx" SG_ 556 EFP_Bezel_Diag_St 1;
BA_ "U_CD43_MY16_Gas_Tx" SG_ 556 EFP_Bezel_Diag_St 1;
BA_ "CrossOver_InfoCAN" SG_ 556 Bezel_Beeps_Supported 1;
BA_ "GenSigSendType" SG_ 556 Bezel_Beeps_Supported 3;
BA_ "U_CD4_MY13_Diesel_Tx" SG_ 556 Bezel_Beeps_Supported 1;
BA_ "U_CD4_MY13_Gas_Tx" SG_ 556 Bezel_Beeps_Supported 1;
BA_ "U_CD4_MY13_Hev_Tx" SG_ 556 Bezel_Beeps_Supported 1;
BA_ "U_CD4_MY13_Phev_Tx" SG_ 556 Bezel_Beeps_Supported 1;
BA_ "U_CD42_MY14_Diesel_Tx" SG_ 556 Bezel_Beeps_Supported 1;
BA_ "U_CD42_MY14_Gas_Tx" SG_ 556 Bezel_Beeps_Supported 1;
BA_ "U_P552_MY15_Gas_Tx" SG_ 556 Bezel_Beeps_Supported 1;
BA_ "U_S550_MY15_Gas_Tx" SG_ 556 Bezel_Beeps_Supported 1;
BA_ "U_C489_MY14_Gas_Tx" SG_ 556 Bezel_Beeps_Supported 1;
BA_ "U_U502_MY15_Gas_Tx" SG_ 556 Bezel_Beeps_Supported 1;
BA_ "U_UP375_MY15_Gas_Tx" SG_ 556 Bezel_Beeps_Supported 1;
BA_ "U_UP375_MY15_Diesel_Tx" SG_ 556 Bezel_Beeps_Supported 1;
BA_ "U_CD43_MY16_Gas_Tx" SG_ 556 Bezel_Beeps_Supported 1;
BA_ "CrossOver_InfoCAN" SG_ 556 Bezel_Beep_St 1;
BA_ "GenSigSendType" SG_ 556 Bezel_Beep_St 3;
BA_ "U_CD4_MY13_Diesel_Tx" SG_ 556 Bezel_Beep_St 1;
BA_ "U_CD4_MY13_Gas_Tx" SG_ 556 Bezel_Beep_St 1;
BA_ "U_CD4_MY13_Hev_Tx" SG_ 556 Bezel_Beep_St 1;
BA_ "U_CD4_MY13_Phev_Tx" SG_ 556 Bezel_Beep_St 1;
BA_ "U_CD42_MY14_Diesel_Tx" SG_ 556 Bezel_Beep_St 1;
BA_ "U_CD42_MY14_Gas_Tx" SG_ 556 Bezel_Beep_St 1;
BA_ "U_P552_MY15_Gas_Tx" SG_ 556 Bezel_Beep_St 1;
BA_ "U_S550_MY15_Gas_Tx" SG_ 556 Bezel_Beep_St 1;
BA_ "U_C489_MY14_Gas_Tx" SG_ 556 Bezel_Beep_St 1;
BA_ "U_U502_MY15_Gas_Tx" SG_ 556 Bezel_Beep_St 1;
BA_ "U_UP375_MY15_Gas_Tx" SG_ 556 Bezel_Beep_St 1;
BA_ "U_UP375_MY15_Diesel_Tx" SG_ 556 Bezel_Beep_St 1;
BA_ "U_CD43_MY16_Gas_Tx" SG_ 556 Bezel_Beep_St 1;
BA_ "GenSigStartValue" SG_ 556 PassRstrnInd_Stat 1;
BA_ "GenSigSendType" SG_ 556 PassRstrnInd_Stat 3;
BA_ "U_CD4_MY13_Diesel_Tx" SG_ 556 PassRstrnInd_Stat 1;
BA_ "U_CD4_MY13_Gas_Tx" SG_ 556 PassRstrnInd_Stat 1;
BA_ "U_CD4_MY13_Hev_Tx" SG_ 556 PassRstrnInd_Stat 1;
BA_ "U_CD4_MY13_Phev_Tx" SG_ 556 PassRstrnInd_Stat 1;
BA_ "U_CD42_MY14_Diesel_Tx" SG_ 556 PassRstrnInd_Stat 1;
BA_ "U_CD42_MY14_Gas_Tx" SG_ 556 PassRstrnInd_Stat 1;
BA_ "U_P552_MY15_Gas_Tx" SG_ 556 PassRstrnInd_Stat 1;
BA_ "U_S550_MY15_Gas_Tx" SG_ 556 PassRstrnInd_Stat 1;
BA_ "U_C489_MY14_Gas_Tx" SG_ 556 PassRstrnInd_Stat 1;
BA_ "U_U502_MY15_Gas_Tx" SG_ 556 PassRstrnInd_Stat 1;
BA_ "U_UP375_MY15_Gas_Tx" SG_ 556 PassRstrnInd_Stat 1;
BA_ "U_UP375_MY15_Diesel_Tx" SG_ 556 PassRstrnInd_Stat 1;
BA_ "U_CD43_MY16_Gas_Tx" SG_ 556 PassRstrnInd_Stat 1;
VAL_ 945 KeyOffMde_D_Actl 15 "NotUsed_11" 14 "NotUsed_10" 13 "NotUsed_9" 12 "NotUsed_8" 11 "NotUsed_7" 10 "NotUsed_6" 9 "NotUsed_5" 8 "NotUsed_4" 7 "NotUsed_3" 6 "NotUsed_2" 5 "NotUsed_1" 4 "CriticalBattery" 3 "Hibernate" 2 "TransportPower" 1 "FactoryPower" 0 "NormalPower" ;
VAL_ 1079 BattULo2_Te_Actl 127 "Fault" ;
VAL_ 1079 BattULo2_Te_Actl_UB 1 "Fresh_data" 0 "Unchanged_data" ;
VAL_ 1075 SelDrvMdePt_D_Rq_UB 1 "Fresh_data" 0 "Unchanged_data" ;
VAL_ 1075 SelDrvMdePt_D_Rq 31 "NotUsed16" 30 "NotUsed15" 29 "NotUsed14" 28 "NotUsed13" 27 "NotUsed12" 26 "NotUsed11" 25 "NotUsed10" 24 "NotUsed9" 23 "NotUsed8" 22 "NotUsed7" 21 "NotUsed6" 20 "NotUsed5" 19 "NotUsed4" 18 "NotUsed3" 17 "NotUsed2" 16 "NotUsed1" 15 "HighSpeedDesertMode_Baja" 14 "SportAdaptiveMode" 13 "NotAvailable_13" 12 "NotAvailable_12" 11 "NotAvailable_11" 10 "NotAvailable_10" 9 "RockCrawlMode" 8 "MudRutsMode" 7 "SandMode" 6 "EconomyMode" 5 "GrassGravelSnow" 4 "NotAvailable_04" 3 "TowHaulMode" 2 "NotAvailable_02" 1 "SportMode" 0 "NormalMode" ;
VAL_ 1075 PrkAidSnsRrCrnr_D_Stat_UB 1 "Fresh_data" 0 "Unchanged_data" ;
VAL_ 1075 PrkAidSnsRrCrnr_D_Stat 15 "Zone_15" 14 "Zone_14" 13 "Zone_13" 12 "Zone_12" 11 "Zone_11" 10 "Zone_10" 9 "Zone_9" 8 "Zone_8" 7 "Zone_7" 6 "Zone_6" 5 "Zone_5" 4 "Zone_4" 3 "Zone_3" 2 "Zone_2" 1 "Zone_1" 0 "Off" ;
VAL_ 1075 PrkAidSnsRrCntr_D_Stat_UB 1 "Fresh_data" 0 "Unchanged_data" ;
VAL_ 1075 PrkAidSnsRrCntr_D_Stat 15 "Zone_15" 14 "Zone_14" 13 "Zone_13" 12 "Zone_12" 11 "Zone_11" 10 "Zone_10" 9 "Zone_9" 8 "Zone_8" 7 "Zone_7" 6 "Zone_6" 5 "Zone_5" 4 "Zone_4" 3 "Zone_3" 2 "Zone_2" 1 "Zone_1" 0 "Off" ;
VAL_ 1075 PrkAidSnsRlCrnr_D_Stat_UB 1 "Fresh_data" 0 "Unchanged_data" ;
VAL_ 1075 PrkAidSnsRlCrnr_D_Stat 15 "Zone_15" 14 "Zone_14" 13 "Zone_13" 12 "Zone_12" 11 "Zone_11" 10 "Zone_10" 9 "Zone_9" 8 "Zone_8" 7 "Zone_7" 6 "Zone_6" 5 "Zone_5" 4 "Zone_4" 3 "Zone_3" 2 "Zone_2" 1 "Zone_1" 0 "Off" ;
VAL_ 1075 PrkAidSnsRlCntr_D_Stat_UB 1 "Fresh_data" 0 "Unchanged_data" ;
VAL_ 1075 PrkAidSnsRlCntr_D_Stat 15 "Zone_15" 14 "Zone_14" 13 "Zone_13" 12 "Zone_12" 11 "Zone_11" 10 "Zone_10" 9 "Zone_9" 8 "Zone_8" 7 "Zone_7" 6 "Zone_6" 5 "Zone_5" 4 "Zone_4" 3 "Zone_3" 2 "Zone_2" 1 "Zone_1" 0 "Off" ;
VAL_ 1075 Btt_L_Actl_UB 1 "Fresh_data" 0 "Unchanged_data" ;
VAL_ 1075 Btt_L_Actl 127 "Faulty" 126 "NoDataExists" ;
VAL_ 1075 BttOn_B_Rq_UB 1 "Fresh_data" 0 "Unchanged_data" ;
VAL_ 1075 BttOn_B_Rq 1 "On" 0 "Off" ;
VAL_ 1098 TrlrAidSwtch_D_RqDrv 3 "Faulty" 2 "NotUsed" 1 "Pressed" 0 "Not_Pressed" ;
VAL_ 1098 TrlrAidCtl_U_RqDrv 4095 "Faulty" 4094 "NoDataExists" ;
VAL_ 1045 VehVActlBrk_D_Qf 3 "OK" 2 "Not_Within_Specifications" 1 "No_Data_Exists" 0 "Faulty" ;
VAL_ 1189 Running_Board_Stat 3 "Unused" 2 "Manually_Deployed" 1 "All_Enabled" 0 "All_Disabled" ;
VAL_ 1095 VehLck_D_Dsply 3 "Faulty" 2 "Unlock" 1 "Lock" 0 "Off" ;
VAL_ 1095 PepsKeyActv_D_Stat 15 "NotUsed11" 14 "NotUsed10" 13 "NotUsed9" 12 "NotUsed8" 11 "NotUsed7" 10 "NotUsed6" 9 "NotUsed5" 8 "Key4Active" 7 "NotUsed4" 6 "NotUsed3" 5 "NotUsed2" 4 "Key3Active" 3 "NotUsed1" 2 "Key2Active" 1 "Key1Active" 0 "NoKeyActive" ;
VAL_ 1095 HeadLghtOn_D_Rq 7 "NotUsed2" 6 "NotUsed1" 5 "DrlBoth" 4 "DrlRight" 3 "DrlLeft" 2 "High" 1 "Low" 0 "Off" ;
VAL_ 948 Tire_Press_ILR_Stat 4 "Alert" 15 "Not_Supported" 3 "Fault" 2 "Low" 1 "Normal" 0 "Unknown" ;
VAL_ 948 Tire_Press_IRR_Stat 4 "Alert" 15 "Not_Supported" 3 "Fault" 2 "Low" 1 "Normal" 0 "Unknown" ;
VAL_ 948 Tire_Press_LR_OLR_Stat 4 "Alert" 15 "Not_Supported" 3 "Fault" 2 "Low" 1 "Normal" 0 "Unknown" ;
VAL_ 948 Tire_Press_RR_ORR_Stat 4 "Alert" 15 "Not_Supported" 3 "Fault" 2 "Low" 1 "Normal" 0 "Unknown" ;
VAL_ 948 Tire_Press_RF_Stat 4 "Alert" 15 "Not_Supported" 3 "Fault" 2 "Low" 1 "Normal" 0 "Unknown" ;
VAL_ 948 Tire_Press_LF_Stat 4 "Alert" 15 "Not_Supported" 3 "Fault" 2 "Low" 1 "Normal" 0 "Unknown" ;
VAL_ 948 Tire_Press_System_Stat 13 "Training_Complete" 12 "Train_InsideLeftRear_tire" 11 "Train_OutsideLeftRear_tire" 10 "Train_LeftRear_tire" 9 "Train_InsideRtRear_tire" 8 "Train_OutsideRtRear_tire" 7 "Train_RightRear_tire" 14 "Tires_not_trained" 6 "Train_RightFront_tire" 5 "Train_LeftFront_tire" 4 "Systm_Activ_Composite_Stat" 3 "Low_Composite_Stat" 2 "Sensr_Fault_Composite_Stat" 1 "Systm_Fault_Composite_Stat" 0 "Unknown_Composite_Stat" ;
VAL_ 948 Tire_Press_Telltale 3 "Not_Used" 2 "Flash" 1 "On" 0 "Off" ;
VAL_ 948 TirePReset_D_Stat 3 "Not_Used" 2 "Nack" 1 "Ack" 0 "Null" ;
VAL_ 839 FohKeyOff_B_Rq 1 "Enable" 0 "Disable" ;
VAL_ 850 SeatBlLoPsgr_Pc_Actl2 127 "Null" ;
VAL_ 850 SeatCshnPsgrRR_Pc_Actl 127 "Null" ;
VAL_ 850 SeatCshnPsgrRL_Pc_Actl 127 "Null" ;
VAL_ 850 SeatCshnPsgrFR_Pc_Actl 127 "Null" ;
VAL_ 850 SeatCshnPsgrFL_Pc_Actl 127 "Null" ;
VAL_ 849 SeatCshnDrvRR_Pc_Actl 127 "Null" ;
VAL_ 849 SeatCshnDrvRL_Pc_Actl 127 "Null" ;
VAL_ 849 SeatCshnDrvFR_Pc_Actl 127 "Null" ;
VAL_ 849 SeatCshnDrvFL_Pc_Actl 127 "Null" ;
VAL_ 846 SeatFnChngPsgr2_D_Rq 15 "Faulty" 14 "NotUsed9" 13 "NotUsed8" 12 "NotUsed7" 11 "NotUsed6" 10 "NotUsed5" 9 "NotUsed4" 8 "NotUsed3" 7 "NotUsed2" 6 "High" 5 "Low" 4 "Off" 3 "Decrease" 2 "Increase" 1 "NotUsed1" 0 "Inactive" ;
VAL_ 846 SeatFnChngDrv2_D_Rq 15 "Faulty" 14 "NotUsed9" 13 "NotUsed8" 12 "NotUsed7" 11 "NotUsed6" 10 "NotUsed5" 9 "NotUsed4" 8 "NotUsed3" 7 "NotUsed2" 6 "High" 5 "Low" 4 "Off" 3 "Decrease" 2 "Increase" 1 "NotUsed1" 0 "Inactive" ;
VAL_ 846 SeatFnPsgr_D_Rq 7 "CushionMassage" 6 "LumbarMassage" 5 "UpperBolster" 4 "LowerBolster" 3 "UpperLumbar" 2 "MiddleLumbar" 1 "LowerLumbar" 0 "Inactive" ;
VAL_ 846 SeatFnDrv_D_Rq 7 "CushionMassage" 6 "LumbarMassage" 5 "UpperBolster" 4 "LowerBolster" 3 "UpperLumbar" 2 "MiddleLumbar" 1 "LowerLumbar" 0 "Inactive" ;
VAL_ 846 SeatFnDfaltPsgr_B_Rq 1 "Active" 0 "Inactive" ;
VAL_ 846 SeatFnDfaltDrv_B_Rq 1 "Active" 0 "Inactive" ;
VAL_ 846 SeatFnChngPsgr_D_Rq 2 "Decrease" 1 "Increase" 0 "Inactive" ;
VAL_ 846 SeatFnChngDrv_D_Rq 2 "Decrease" 1 "Increase" 0 "Inactive" ;
VAL_ 846 PsgrMemory_Rq 8 "Recall_4" 7 "Recall_3" 6 "Recall_2" 5 "Recall_1" 4 "Store_4" 3 "Store_3" 2 "Store_2" 1 "Store_1" 0 "Inactive" ;
VAL_ 845 StmsLmbrPsgr_D_Stat 3 "High" 2 "Low" 1 "Off" 0 "Null" ;
VAL_ 845 StmsCshnPsgr_D_Stat 3 "High" 2 "Low" 1 "Off" 0 "Null" ;
VAL_ 845 SeatSwtchPsgr_B_Stat 1 "On" 0 "Off" ;
VAL_ 845 SeatPPsgr_B_Stat 1 "Updating" 0 "NotUpdating" ;
VAL_ 845 SeatFnPsgr_D_Stat 7 "CushionMassage" 6 "LumbarMassage" 5 "UpperBolster" 4 "LowerBolster" 3 "UpperLumbar" 2 "MiddleLumbar" 1 "LowerLumbar" 0 "Null" ;
VAL_ 845 PsgrMemFeedback_Rsp 8 "Recall_4" 7 "Recall_3" 6 "Recall_2" 5 "Recall_1" 4 "Store_4" 3 "Store_3" 2 "Store_2" 1 "Store_1" 0 "Inactive" ;
VAL_ 844 StmsLmbrDrv_D_Stat 3 "High" 2 "Low" 1 "Off" 0 "Null" ;
VAL_ 844 StmsCshnDrv_D_Stat 3 "High" 2 "Low" 1 "Off" 0 "Null" ;
VAL_ 844 SeatSwtchDrv_B_Stat 1 "On" 0 "Off" ;
VAL_ 844 SeatFnDrv_D_Stat 7 "CushionMassage" 6 "LumbarMassage" 5 "UpperBolster" 4 "LowerBolster" 3 "UpperLumbar" 2 "MiddleLumbar" 1 "LowerLumbar" 0 "Null" ;
VAL_ 844 SeatPDrv_B_Stat 1 "Updating" 0 "NotUpdating" ;
VAL_ 843 SeatLmbrUpPsgr_Pc_Actl 127 "Null" ;
VAL_ 843 SeatLmbrMidPsgr_Pc_Actl 127 "Null" ;
VAL_ 843 SeatLmbrLoPsgr_Pc_Actl 127 "Null" ;
VAL_ 843 SeatBlUpPsgr_Pc_Actl 127 "Null" ;
VAL_ 843 SeatBlLoPsgr_Pc_Actl 127 "Null" ;
VAL_ 842 SeatLmbrUpDrv_Pc_Actl 127 "Null" ;
VAL_ 842 SeatLmbrMidDrv_Pc_Actl 127 "Null" ;
VAL_ 842 SeatLmbrLoDrv_Pc_Actl 127 "Null" ;
VAL_ 842 SeatBlUpDrv_Pc_Actl 127 "Null" ;
VAL_ 842 SeatBlLoDrv_Pc_Actl 127 "Null" ;
VAL_ 958 EngOff_T_Actl 65535 "Invalid" ;
VAL_ 958 EngOff_T_Actl_UB 1 "Fresh_data" 0 "Unchanged_data" ;
VAL_ 958 StopStrtDrvMde_D_Indic_UB 1 "Fresh_data" 0 "Unchanged_data" ;
VAL_ 958 PrmtrAlrmEvnt_D_Stat 15 "Diag_Tamper" 14 "Trailer" 13 "Shock_Sensor" 12 "Post_Crash" 11 "Panic" 10 "Intrusion" 9 "Inclination" 8 "Ign_Tamper" 7 "LG_Door" 6 "Decklid" 5 "Hood" 4 "PR_Door" 3 "PF_Door" 2 "DR_Door" 1 "DF_Door" 0 "Null" ;
VAL_ 958 PrmtrAlrmEvnt_D_Stat_UB 1 "Fresh_data" 0 "Unchanged_data" ;
VAL_ 958 StopStrtDrvMde_D_Indic 3 "NotUsed" 2 "StartStop_IndirectDeselect" 1 "StopStart_Deselected" 0 "StopStart_Selected" ;
VAL_ 958 FuelLvl_Pc_Dsply_UB 1 "Fresh_data" 0 "Unchanged_data" ;
VAL_ 958 OdometerMasterValue_UB 1 "Fresh_data" 0 "Unchanged_data" ;
VAL_ 958 OdometerMasterValue 16777215 "Invalid" ;
VAL_ 827 SteClmnSwtchTlt_D_Stat 3 "Unused" 2 "Down" 1 "Up" 0 "Null" ;
VAL_ 827 SteClmnSwtchTel_D_Stat 3 "Unused" 2 "Rearward" 1 "Forward" 0 "Null" ;
VAL_ 902 Remote_Start_Req 3 "Not_Used" 2 "Remote_Cancel" 1 "Remote_Start" 0 "No_Request" ;
VAL_ 902 PrmtrAlrmWarn_B_Rq 1 "Active" 0 "Null" ;
VAL_ 902 PrmtrAlrmTrg_B_Rq 1 "Active" 0 "Null" ;
VAL_ 902 Panic_D_RqRsm 3 "NotUsed" 2 "On" 1 "Off" 0 "Null" ;
VAL_ 902 CellLock_D_RqRsm 7 "NotUsed3" 6 "NotUsed2" 5 "NotUsed1" 4 "TrunkRelPopGlassLgCargo" 3 "LockAllDoorsandTailgate" 2 "UnlockDriversDoor" 1 "UnlockAllDoorsandTailgate" 0 "NoRequest" ;
VAL_ 765 EmPrflButtnAssoc_D_Rq_UB 1 "Fresh_data" 0 "Unchanged_data" ;
VAL_ 765 EmPrflButtnAssoc_D_Rq 3 "NotUsed" 2 "ExitButtonAssociation" 1 "EnterButtonAssociation" 0 "Null" ;
VAL_ 765 ValetMode_D_Stat_UB 1 "Fresh_data" 0 "Unchanged_data" ;
VAL_ 765 ValetMode_D_Stat 3 "NotUsed" 2 "On" 1 "Off" 0 "Null" ;
VAL_ 765 TrlrBrkActCnnct_B_Actl_UB 1 "Fresh_data" 0 "Unchanged_data" ;
VAL_ 765 TrlrBrkActCnnct_B_Actl 1 "Yes" 0 "No" ;
VAL_ 765 TrlrAidMsgTxt_D_Rq_UB 1 "Fresh_data" 0 "Unchanged_data" ;
VAL_ 765 TrlrAidMsgTxt_D_Rq 31 "Message31" 30 "Message30" 29 "Message29" 28 "Message28" 27 "Message27" 26 "Message26" 25 "Message25" 24 "Message24" 23 "Message23" 22 "Message22" 21 "Message21" 20 "Message20" 19 "Message19" 18 "Message18" 17 "Message17" 16 "Message16" 15 "Message15" 14 "Message14" 13 "Message13" 12 "Message12" 11 "Message11" 10 "Message10" 9 "Message9" 8 "Message8" 7 "Message7" 6 "Message6" 5 "Message5" 4 "Message4" 3 "Message3" 2 "Message2" 1 "Message1" 0 "NoMessage" ;
VAL_ 765 Voice_Blower_Limit_UB 1 "Fresh_data" 0 "Unchanged_data" ;
VAL_ 765 Voice_Blower_Limit 1 "Request" 0 "NoRequest" ;
VAL_ 765 CamraFrntStat_D_Stat_UB 1 "Fresh_data" 0 "Unchanged_data" ;
VAL_ 765 CamraFrntStat_D_Stat 3 "No_Data_Present" 2 "NotUsed" 1 "On" 0 "Off" ;
VAL_ 765 SteWhlHeat_D_Stat 15 "NotUsed6" 14 "NotUsed5" 13 "NotUsed4" 12 "NotUsed3" 11 "NotUsed2" 10 "NotUsed1" 9 "Reserved_3" 8 "Reserved_2" 7 "Reserved_1" 6 "Level_3_Heating" 5 "Level_3_Heating_LS" 4 "Level_2_Heating" 3 "Level_2_Heating_LS" 2 "Level_1_Heating" 1 "Level_1_Heating_LS" 0 "Off" ;
VAL_ 765 Running_Board_Cmd_UB 1 "Fresh_data" 0 "Unchanged_data" ;
VAL_ 765 Running_Board_Cmd 3 "Unused" 2 "Manually_Deployed" 1 "All_Enabled" 0 "All_Disabled" ;
VAL_ 765 Bezel_Beeps_Rq_UB 1 "Fresh_data" 0 "Unchanged_data" ;
VAL_ 765 Bezel_Beeps_Rq 0 "Inactive" 2 "Disable" 1 "Enable" ;
VAL_ 765 Diagnostic_Operation_Rq_UB 1 "Fresh_data" 0 "Unchanged_data" ;
VAL_ 765 Bezel_Diag_State_Rq_UB 1 "Fresh_data" 0 "Unchanged_data" ;
VAL_ 765 Bezel_Diag_Module_Rq_UB 1 "Fresh_data" 0 "Unchanged_data" ;
VAL_ 765 Diagnostic_Operation_Rq 7 "SignalStrength" 6 "SDARSESNNumber" 5 "SpeakerWalkAround" 4 "CalibrationPartNumber" 15 "Reserved" 3 "HardwarePartNumber" 2 "SoftwarePartNumber" 1 "GetAllBackgroundDiagRq" 0 "Inactive" ;
VAL_ 765 Bezel_Diag_State_Rq 1 "Active" 0 "Inactive" ;
VAL_ 765 Bezel_Diag_Module_Rq 15 "Reserved" 3 "EFP" 2 "DSP_AMP" 1 "AHU" 0 "Inactive" ;
VAL_ 765 HMI_HMIMode_St_UB 1 "Fresh_data" 0 "Unchanged_data" ;
VAL_ 765 HMI_HMIMode_St 5 "Load_Shed_Active" 0 "Invalid" 1 "OffMode" 2 "On" 3 "Phone" 4 "Climate" ;
VAL_ 765 Mc_VehUnitTempUsrSel_St_UB 1 "Fresh_data" 0 "Unchanged_data" ;
VAL_ 765 Mc_VehUnitTempUsrSel_St 0 "Temperature_deg_c" 1 "Temperature_deg_f" ;
VAL_ 765 SteWhlHeat_D_Stat_UB 1 "Fresh_data" 0 "Unchanged_data" ;
VAL_ 765 ParkDetect_Stat_UB 1 "Fresh_data" 0 "Unchanged_data" ;
VAL_ 765 ParkDetect_Stat 1 "Park" 0 "Not_Park" ;
VAL_ 672 Coding_BtnID_D 1 "Pressed" 0 "Not_Pressed" ;
VAL_ 672 Coding_BtnID_C 1 "Pressed" 0 "Not_Pressed" ;
VAL_ 672 Coding_BtnID_B 1 "Pressed" 0 "Not_Pressed" ;
VAL_ 672 Coding_BtnID_A 1 "Pressed" 0 "Not_Pressed" ;
VAL_ 672 BCP_Audible_Beep_Rq 1 "Active" 0 "Inactive" ;
VAL_ 556 EFP_Bezel_Diag_St 15 "Reserved" 3 "CalibrationPartNumber" 2 "HardwarePartNumber" 1 "SoftwarePartNumber" 0 "Inactive_NOP" ;
VAL_ 556 Bezel_Beeps_Supported 2 "Not_Supported" 1 "Supported" 0 "Invalid" ;
VAL_ 556 Bezel_Beep_St 0 "Invalid" 2 "Disabled" 1 "Enabled" ;
VAL_ 556 PassRstrnInd_Stat 7 "Invalid" 6 "Unused_2" 5 "Unused_1" 4 "Both_Indicators_Faulted" 3 "AirbagOff_Indicator_fault" 2 "AirbagOn_Indicator_fault" 1 "Normal" 0 "Not_Supported" ;
